VERSION ""

NS_ :

BS_:

BU_: VMCU TPM RCIOM FCIOM FAS ECUspare4 EBS EAS CCIOM BPMU APM

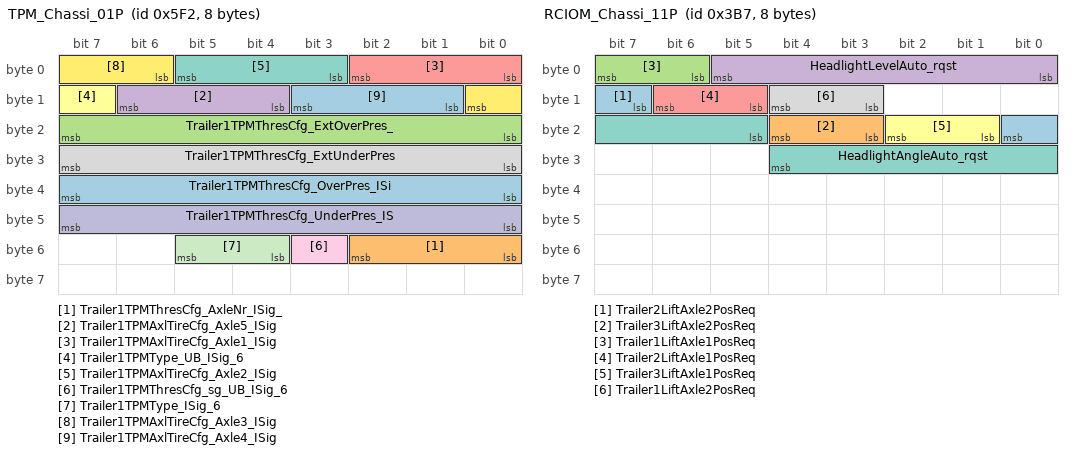
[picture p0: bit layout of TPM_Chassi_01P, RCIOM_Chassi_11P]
BO_ 1522 TPM_Chassi_01P: 8 TPM
 SG_ Trailer1TPMThresCfg_OverPres_ISi : 32|8@1+ (1,-125) [-125|130] "Percent"  VMCU
 SG_ Trailer1TPMThresCfg_AxleNr_ISig_ : 48|3@1+ (1,0) [0|0] ""  VMCU
 SG_ Trailer1TPMThresCfg_ExtOverPres_ : 16|8@1+ (1,-125) [-125|130] "Percent"  VMCU
 SG_ Trailer1TPMAxlTireCfg_Axle5_ISig : 12|3@1+ (1,0) [0|0] ""  VMCU
 SG_ Trailer1TPMAxlTireCfg_Axle1_ISig : 0|3@1+ (1,0) [0|0] ""  VMCU
 SG_ Trailer1TPMType_UB_ISig_6 : 15|1@1+ (1,0) [0|0] ""  VMCU
 SG_ Trailer1TPMAxlTireCfg_Axle2_ISig : 3|3@1+ (1,0) [0|0] ""  VMCU
 SG_ Trailer1TPMThresCfg_ExtUnderPres : 24|8@1+ (1,-125) [-125|130] "Percent"  VMCU
 SG_ Trailer1TPMThresCfg_sg_UB_ISig_6 : 51|1@1+ (1,0) [0|0] ""  VMCU
 SG_ Trailer1TPMThresCfg_UnderPres_IS : 40|8@1+ (1,-125) [-125|130] "Percent"  VMCU
 SG_ Trailer1TPMType_ISig_6 : 52|2@1+ (1,0) [0|0] ""  VMCU
 SG_ Trailer1TPMAxlTireCfg_Axle3_ISig : 6|3@1+ (1,0) [0|0] ""  VMCU
 SG_ Trailer1TPMAxlTireCfg_Axle4_ISig : 9|3@1+ (1,0) [0|0] ""  VMCU

BO_ 1349 RCIOM_Chassi_12P: 8 RCIOM
 SG_ RearAxleGroupLoad_ISig_6 : 0|16@1+ (2,0) [0|131070] "kg"  VMCU

BO_ 951 RCIOM_Chassi_11P: 8 RCIOM
 SG_ Trailer2LiftAxle2PosReq : 15|2@1+ (1,0) [0|0] ""  EBS
 SG_ Trailer3LiftAxle2PosReq : 19|2@1+ (1,0) [0|0] ""  EBS
 SG_ Trailer1LiftAxle1PosReq : 6|2@1+ (1,0) [0|0] ""  EBS
 SG_ HeadlightLevelAuto_rqst : 0|6@1+ (1,-16) [-16|47] ""  VMCU
 SG_ Trailer2LiftAxle1PosReq : 13|2@1+ (1,0) [0|0] ""  EBS
 SG_ Trailer3LiftAxle1PosReq : 17|2@1+ (1,0) [0|0] ""  EBS
 SG_ HeadlightAngleAuto_rqst : 21|8@1+ (0.025,-4) [-4|2.375] "deg"  VMCU
 SG_ Trailer1LiftAxle2PosReq : 11|2@1+ (1,0) [0|0] ""  EBS

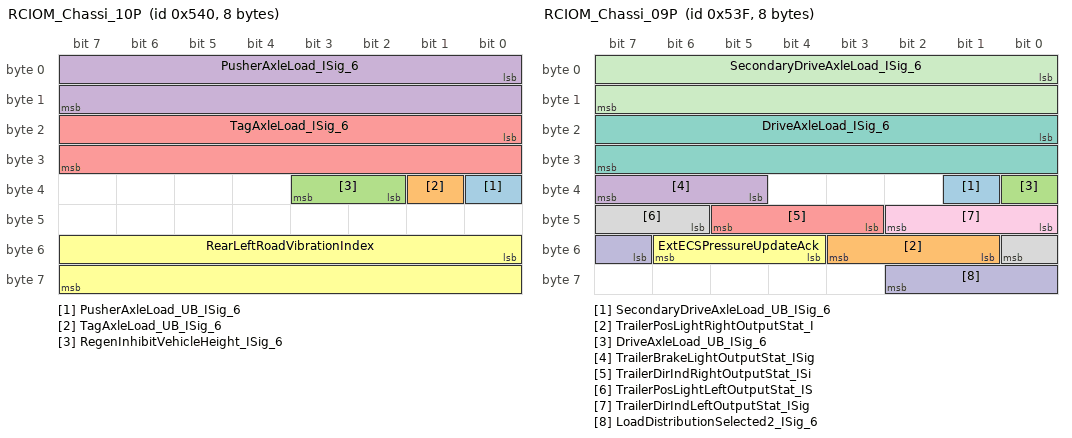
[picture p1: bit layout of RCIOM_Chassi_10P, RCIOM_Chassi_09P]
BO_ 1344 RCIOM_Chassi_10P: 8 RCIOM
 SG_ PusherAxleLoad_UB_ISig_6 : 32|1@1+ (1,0) [0|0] ""  FAS,EBS,EAS,APM,VMCU
 SG_ TagAxleLoad_UB_ISig_6 : 33|1@1+ (1,0) [0|0] ""  VMCU,EAS,APM,FAS,EBS
 SG_ RegenInhibitVehicleHeight_ISig_6 : 34|2@1+ (1,0) [0|0] ""  VMCU
 SG_ PusherAxleLoad_ISig_6 : 0|16@1+ (0.5,0) [0|32767.5] "kg"  EAS,VMCU,FAS,APM,EBS
 SG_ TagAxleLoad_ISig_6 : 16|16@1+ (0.5,0) [0|32767.5] "kg"  VMCU,EBS,APM,EAS,FAS
 SG_ RearLeftRoadVibrationIndex : 48|16@1+ (0.01,0) [0|655.35] ""  VMCU

BO_ 1343 RCIOM_Chassi_09P: 8 RCIOM
 SG_ SecondaryDriveAxleLoad_UB_ISig_6 : 33|1@1+ (1,0) [0|0] ""  FAS,APM,EBS,VMCU
 SG_ TrailerPosLightRightOutputStat_I : 49|3@1+ (1,0) [0|0] ""  VMCU
 SG_ DriveAxleLoad_UB_ISig_6 : 32|1@1+ (1,0) [0|0] ""  VMCU,EBS,FAS,APM
 SG_ TrailerBrakeLightOutputStat_ISig : 37|3@1+ (1,0) [0|0] ""  VMCU
 SG_ TrailerDirIndRightOutputStat_ISi : 43|3@1+ (1,0) [0|0] ""  VMCU
 SG_ ExtECSPressureUpdateAck : 52|3@1+ (1,0) [0|0] ""  VMCU
 SG_ DriveAxleLoad_ISig_6 : 16|16@1+ (0.5,0) [0|32767.5] "kg"  VMCU,FAS,EBS,APM
 SG_ TrailerPosLightLeftOutputStat_IS : 46|3@1+ (1,0) [0|0] ""  VMCU
 SG_ TrailerDirIndLeftOutputStat_ISig : 40|3@1+ (1,0) [0|0] ""  VMCU
 SG_ LoadDistributionSelected2_ISig_6 : 55|4@1+ (1,0) [0|0] ""  VMCU
 SG_ SecondaryDriveAxleLoad_ISig_6 : 0|16@1+ (0.5,0) [0|32767.5] "kg"  VMCU,FAS,APM,EBS

BO_ 825 RCIOM_Chassi_08P: 8 RCIOM
 SG_ RevLight_cmd : 6|2@1+ (1,0) [0|0] ""  CCIOM,VMCU
 SG_ LoadDistributionALDChangeACK_ISi : 32|3@1+ (1,0) [0|0] ""  VMCU
 SG_ LiftAxle2AutoLiftSelected_ISig_6 : 10|2@1+ (1,0) [0|0] ""  VMCU
 SG_ DriveLevelPosUserInteraction_ISi : 59|3@1+ (1,0) [0|0] ""  VMCU
 SG_ FirstAxleLowerPrioSelected_ISig_ : 27|3@1+ (1,0) [0|0] ""  VMCU
 SG_ FerryFunctionSwitchChangeACK_ISi : 0|2@1+ (1,0) [0|0] ""  VMCU
 SG_ TrailerDirInd_status : 56|3@1+ (1,0) [0|0] ""  VMCU
 SG_ RevLightLamp_stat_ISig_6 : 43|3@1+ (1,0) [0|0] ""  VMCU
 SG_ UnevenLoadWarning_ISig_6 : 38|2@1+ (1,0) [0|0] ""  VMCU
 SG_ LoadDistributionSelected_ISig_6 : 12|4@1+ (1,0) [0|0] ""  VMCU
 SG_ PositionLightRearLamp_stat_ISig_ : 40|3@1+ (1,0) [0|0] ""  VMCU
 SG_ LiftAxle1AutoLiftSelected_ISig_6 : 8|2@1+ (1,0) [0|0] ""  VMCU
 SG_ StartupProhibitStatus_ISig_6 : 53|2@1+ (1,0) [0|0] ""  VMCU
 SG_ BrakeLight_rqst_UB_ISig_6 : 55|1@1+ (1,0) [0|0] ""  VMCU
 SG_ LiftAxle1LowerACK_ISig_6 : 24|3@1+ (1,0) [0|0] ""  VMCU
 SG_ RampLevelRequestACK_ISig_6 : 4|2@1+ (1,0) [0|0] ""  VMCU
 SG_ BrakeLightLamp_stat_ISig_6 : 35|3@1+ (1,0) [0|0] ""  VMCU
 SG_ BrakeLightConvoy_rqst_UB_ISig_6 : 62|1@1+ (1,0) [0|0] ""  VMCU
 SG_ TrailerABSStatus_ISig_6 : 2|2@1+ (1,0) [0|0] ""  EBS,APM,VMCU
 SG_ FogLightRearLamp_stat_ISig_6 : 48|3@1+ (1,0) [0|0] ""  VMCU
 SG_ ECSLimpHomeNotification_ISig_6 : 19|3@1+ (1,0) [0|0] ""  VMCU
 SG_ BrakeLight_rqst_ISig_6 : 16|3@1+ (1,0) [0|0] ""  VMCU
 SG_ ECSValveActivationAllowed : 30|2@1+ (1,0) [0|0] ""  CCIOM
 SG_ BrakeLightConvoy_rqst_ISig_6 : 22|2@1+ (1,0) [0|0] ""  VMCU
 SG_ FrontParkBrakeOverrideInd_ISig_6 : 46|2@1+ (1,0) [0|0] ""  VMCU

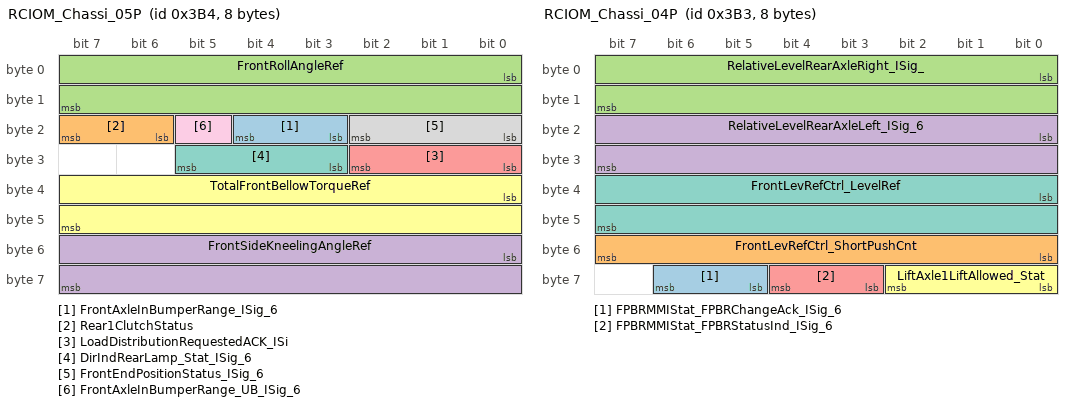
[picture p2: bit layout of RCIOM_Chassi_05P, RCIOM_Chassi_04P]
BO_ 948 RCIOM_Chassi_05P: 8 RCIOM
 SG_ FrontAxleInBumperRange_ISig_6 : 19|2@1+ (1,0) [0|0] ""  VMCU
 SG_ Rear1ClutchStatus : 22|2@1+ (1,0) [0|0] ""  VMCU
 SG_ FrontRollAngleRef : 0|16@1+ (0.001,-30) [-30|35.535] "deg"  CCIOM
 SG_ FrontSideKneelingAngleRef : 48|16@1+ (0.001,-30) [-30|35.535] "deg"  CCIOM
 SG_ LoadDistributionRequestedACK_ISi : 24|3@1+ (1,0) [0|0] ""  VMCU
 SG_ TotalFrontBellowTorqueRef : 32|16@1+ (1000,-10000000) [-10000000|55535000] "Nm"  CCIOM
 SG_ DirIndRearLamp_Stat_ISig_6 : 27|3@1+ (1,0) [0|0] ""  VMCU
 SG_ FrontEndPositionStatus_ISig_6 : 16|3@1+ (1,0) [0|0] ""  VMCU
 SG_ FrontAxleInBumperRange_UB_ISig_6 : 21|1@1+ (1,0) [0|0] ""  VMCU

BO_ 947 RCIOM_Chassi_04P: 8 RCIOM
 SG_ FPBRMMIStat_FPBRChangeAck_ISig_6 : 61|2@1+ (1,0) [0|0] ""  VMCU
 SG_ FrontLevRefCtrl_ShortPushCnt : 48|8@1+ (1,0) [0|255] "Count"  FAS,CCIOM
 SG_ RelativeLevelRearAxleRight_ISig_ : 0|16@1+ (0.1,-3200) [-3200|3353.5] "mm"  VMCU,EBS
 SG_ RelativeLevelRearAxleLeft_ISig_6 : 16|16@1+ (0.1,-3200) [-3200|3353.5] "mm"  EBS,VMCU
 SG_ FPBRMMIStat_FPBRStatusInd_ISig_6 : 59|2@1+ (1,0) [0|0] ""  VMCU
 SG_ LiftAxle1LiftAllowed_Stat : 56|3@1+ (1,0) [0|0] ""  VMCU
 SG_ FrontLevRefCtrl_LevelRef : 32|16@1+ (0.1,-3200) [-3200|3353.5] "mm"  CCIOM,FAS

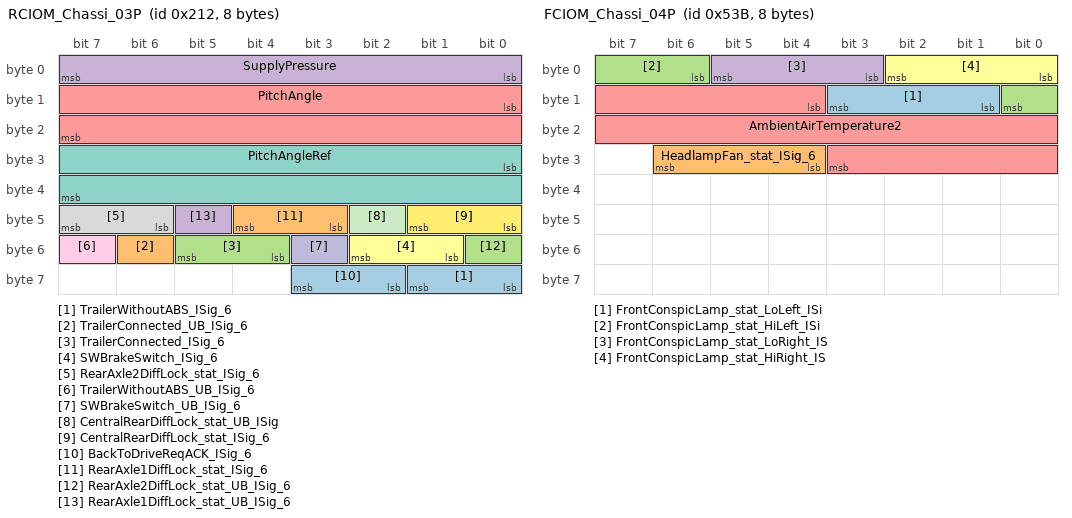
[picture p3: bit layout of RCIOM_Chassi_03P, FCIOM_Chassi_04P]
BO_ 530 RCIOM_Chassi_03P: 8 RCIOM
 SG_ TrailerWithoutABS_ISig_6 : 56|2@1+ (1,0) [0|0] ""  VMCU
 SG_ TrailerConnected_UB_ISig_6 : 54|1@1+ (1,0) [0|0] ""  APM,CCIOM,VMCU,TPM
 SG_ TrailerConnected_ISig_6 : 52|2@1+ (1,0) [0|0] ""  TPM,APM,CCIOM,VMCU
 SG_ SupplyPressure : 0|8@1+ (8,0) [0|2040] "kPa"  VMCU,CCIOM
 SG_ PitchAngle : 8|16@1+ (0.001,-30) [-30|35.535] "deg"  CCIOM,VMCU
 SG_ SWBrakeSwitch_ISig_6 : 49|2@1+ (1,0) [0|0] ""  APM,VMCU
 SG_ PitchAngleRef : 24|16@1+ (0.001,-30) [-30|35.535] "deg"  CCIOM
 SG_ RearAxle2DiffLock_stat_ISig_6 : 46|2@1+ (1,0) [0|0] ""  VMCU,EBS
 SG_ TrailerWithoutABS_UB_ISig_6 : 55|1@1+ (1,0) [0|0] ""  VMCU
 SG_ SWBrakeSwitch_UB_ISig_6 : 51|1@1+ (1,0) [0|0] ""  APM,VMCU
 SG_ CentralRearDiffLock_stat_UB_ISig : 42|1@1+ (1,0) [0|0] ""  VMCU,EBS
 SG_ CentralRearDiffLock_stat_ISig_6 : 40|2@1+ (1,0) [0|0] ""  VMCU,EBS
 SG_ BackToDriveReqACK_ISig_6 : 58|2@1+ (1,0) [0|0] ""  VMCU
 SG_ RearAxle1DiffLock_stat_ISig_6 : 43|2@1+ (1,0) [0|0] ""  VMCU,EBS
 SG_ RearAxle2DiffLock_stat_UB_ISig_6 : 48|1@1+ (1,0) [0|0] ""  EBS,VMCU
 SG_ RearAxle1DiffLock_stat_UB_ISig_6 : 45|1@1+ (1,0) [0|0] ""  VMCU,EBS

BO_ 528 RCIOM_Chassi_02P: 8 RCIOM
 SG_ RearEndPositionStatus_ISig_6 : 48|3@1+ (1,0) [0|0] ""  VMCU
 SG_ FrontFerryFunctionCmd : 59|3@1+ (1,0) [0|0] ""  CCIOM
 SG_ RideHeightStatus_ISig_6 : 20|4@1+ (1,0) [0|0] ""  VMCU
 SG_ KneelingInformation_ISig_6 : 24|4@1+ (1,0) [0|0] ""  VMCU
 SG_ RampHeightOutsideTargetRange_ISi : 51|3@1+ (1,0) [0|0] ""  VMCU
 SG_ LiftAxle1PositionStatus_ISig_6 : 8|3@1+ (1,0) [0|0] ""  CCIOM,VMCU,EBS,FAS,EAS
 SG_ HeightAdjustmentAllowed_ISig_6 : 54|2@1+ (1,0) [0|0] ""  VMCU
 SG_ FerryFunctionStatus_ISig_6 : 56|3@1+ (1,0) [0|0] ""  VMCU
 SG_ LoadDistributionFuncSelected_ISi : 28|4@1+ (1,0) [0|0] ""  VMCU
 SG_ LevelControlInformation_UB_ISig_ : 40|1@1+ (1,0) [0|0] ""  VMCU
 SG_ RollEndPositionStatus_ISig_6 : 3|3@1+ (1,0) [0|0] ""  VMCU
 SG_ HeightControlMode : 32|4@1+ (1,0) [0|0] ""  CCIOM
 SG_ RideHeightFunctionStatus_ISig_6 : 36|4@1+ (1,0) [0|0] ""  VMCU
 SG_ LevelControlInformation_ISig_6 : 16|4@1+ (1,0) [0|0] ""  VMCU
 SG_ KneelingStatusHMI_ISig_6 : 41|2@1+ (1,0) [0|0] ""  VMCU
 SG_ DirInd_Rear_Status : 0|3@1+ (1,0) [0|0] ""  VMCU
 SG_ VehicleDynamicSuspProhibitStat : 62|2@1+ (1,0) [0|0] ""  CCIOM
 SG_ ChangeKneelACK_ISig_6 : 45|2@1+ (1,0) [0|0] ""  VMCU
 SG_ ECSShutdownCmd : 43|2@1+ (1,0) [0|0] ""  CCIOM
 SG_ LiftAxle2PositionStatus_ISig_6 : 11|3@1+ (1,0) [0|0] ""  VMCU,EBS,FAS

BO_ 517 RCIOM_Chassi_01P: 8 RCIOM
 SG_ BrakePressureSensorDemand_ISig_6 : 8|8@1+ (1,0) [0|255] "Percent"  VMCU,APM
 SG_ RampLevelStatus_ISig_6 : 46|4@1+ (1,0) [0|0] ""  VMCU
 SG_ LiftAxle2LowerACK_ISig_6 : 37|3@1+ (1,0) [0|0] ""  VMCU
 SG_ LiftAxle2UpRequestACK_ISig_6 : 34|3@1+ (1,0) [0|0] ""  VMCU
 SG_ FrontLimpHomeCmd : 50|3@1+ (1,0) [0|0] ""  CCIOM
 SG_ LiftAxle1LiftFuncSelected_ISig_6 : 53|3@1+ (1,0) [0|0] ""  VMCU
 SG_ RearAxleInBumperRange_ISig_6 : 30|2@1+ (1,0) [0|0] ""  VMCU
 SG_ LiftAxle1UpRequestACK_ISig_6 : 40|3@1+ (1,0) [0|0] ""  VMCU
 SG_ FogLamp_Rear_Status : 20|2@1+ (1,0) [0|0] ""  VMCU
 SG_ StopLevelChangeAck_ISig_6 : 16|2@1+ (1,0) [0|0] ""  VMCU
 SG_ RampLevelStorageAck_ISig_6 : 24|2@1+ (1,0) [0|0] ""  VMCU
 SG_ RideHeightOutsideTargetRange_ISi : 43|3@1+ (1,0) [0|0] ""  VMCU
 SG_ LiftingControlModeFrontAxle_ISig : 2|2@1+ (1,0) [0|0] ""  APM,VMCU
 SG_ LoadDistributionChangeACK_ISig_6 : 56|3@1+ (1,0) [0|0] ""  VMCU
 SG_ RideHeightStorageAck_ISig_6 : 6|2@1+ (1,0) [0|0] ""  VMCU
 SG_ RearAxleInBumperRange_UB_ISig_6 : 0|1@1+ (1,0) [0|0] ""  VMCU
 SG_ ECSStandbyAllowed_ISig_6 : 32|2@1+ (1,0) [0|0] ""  VMCU
 SG_ LiftAxle2LiftFuncSelected_ISig_6 : 59|3@1+ (1,0) [0|0] ""  VMCU
 SG_ FrontProhibitControlRequest : 4|2@1+ (1,0) [0|0] ""  CCIOM
 SG_ LiftingControlModeRearAxle_ISig_ : 18|2@1+ (1,0) [0|0] ""  VMCU,APM
 SG_ ProhibitControlStatus_ISig_6 : 62|2@1+ (1,0) [0|0] ""  VMCU
 SG_ DisableMechFaultDctnFr_rqst : 26|2@1+ (1,0) [0|0] ""  CCIOM
 SG_ FrontParkBrakeOverrideCommand : 22|2@1+ (1,0) [0|0] ""  EBS
 SG_ BrakePressureSensorDemand_UB_ISi : 1|1@1+ (1,0) [0|0] ""  VMCU,APM

BO_ 2671833714 PhysDiagRespMsg_F2_72_Chas: 8 FCIOM
 SG_ PhysDiagRespSig_F2_72_ISig_6 : 0|64@1+ (1,0) [0|0] ""  VMCU

BO_ 2671833713 PhysDiagRespMsg_F2_71_Chas: 8 FCIOM
 SG_ PhysDiagRespSig_F2_71_ISig_6 : 0|64@1+ (1,0) [0|0] ""  VMCU

BO_ 2671833649 PhysDiagRespMsg_F2_31_Chassi: 8 EAS
 SG_ PhysDiagRespSig_F2_31_ISig_6 : 0|64@1+ (1,0) [0|0] ""  VMCU

BO_ 2671833648 PhysDiagRespMsg_F2_30_Chassi: 8 FAS
 SG_ PhysDiagRespSig_F2_30_ISig_6 : 0|64@1+ (1,0) [0|0] ""  VMCU

BO_ 2671833637 PhysDiagRespMsg_F2_25_Chassi: 8 TPM
 SG_ PhysDiagRespSig_F2_25_ISig_6 : 0|64@1+ (1,0) [0|0] ""  VMCU

BO_ 2671833635 PhysDiagRespMsg_F2_23_Chassi: 8 APM
 SG_ PhysDiagRespSig_F2_23_ISig_6 : 0|64@1+ (1,0) [0|0] ""  VMCU

BO_ 2671833634 PhysDiagRespMsg_F2_22_Chassi: 8 RCIOM
 SG_ PhysDiagRespSig_F2_22_ISig_6 : 0|64@1+ (1,0) [0|0] ""  VMCU

BO_ 2671833633 PhysDiagRespMsg_F2_21_Chassi: 8 FCIOM
 SG_ PhysDiagRespSig_F2_21_ISig_6 : 0|64@1+ (1,0) [0|0] ""  VMCU

BO_ 2671833632 PhysDiagRespMsg_F2_20_Chassi: 8 CCIOM
 SG_ PhysDiagRespSig_F2_20_ISig_6 : 0|64@1+ (1,0) [0|0] ""  VMCU

BO_ 2671833626 PhysDiagRespMsg_F2_1A_Chassi: 8 BPMU
 SG_ PhysDiagRespSig_F2_1A_ISig_6 : 0|64@1+ (1,0) [0|0] ""  VMCU

BO_ 2671801074 PhysDiagReqMsg_72_F2_Chas: 8 VMCU
 SG_ PhysDiagReqSig_72_F2_ISig_6 : 0|64@1+ (1,0) [0|0] ""  FCIOM

BO_ 2671800818 PhysDiagReqMsg_71_F2_Chas: 8 VMCU
 SG_ PhysDiagReqSig_71_F2_ISig_6 : 0|64@1+ (1,0) [0|0] ""  FCIOM

BO_ 2671784434 PhysDiagReqMsg_31_F2_Chassi: 8 VMCU
 SG_ PhysDiagReqSig_31_F2_ISig_6 : 0|64@1+ (1,0) [0|0] ""  EAS

BO_ 2671784178 PhysDiagReqMsg_30_F2_Chassi: 8 VMCU
 SG_ PhysDiagReqSig_30_F2_ISig_6 : 0|64@1+ (1,0) [0|0] ""  FAS

BO_ 2671781362 PhysDiagReqMsg_25_F2_Chassi: 8 VMCU
 SG_ PhysDiagReqSig_25_F2_ISig_6 : 0|64@1+ (1,0) [0|0] ""  TPM

BO_ 2671780850 PhysDiagReqMsg_23_F2_Chassi: 8 VMCU
 SG_ PhysDiagReqSig_23_F2_ISig_6 : 0|64@1+ (1,0) [0|0] ""  APM

BO_ 2671780594 PhysDiagReqMsg_22_F2_Chassi: 8 VMCU
 SG_ PhysDiagReqSig_22_F2_ISig_6 : 0|64@1+ (1,0) [0|0] ""  RCIOM

BO_ 2671780338 PhysDiagReqMsg_21_F2_Chassi: 8 VMCU
 SG_ PhysDiagReqSig_21_F2_ISig_6 : 0|64@1+ (1,0) [0|0] ""  FCIOM

BO_ 2671780082 PhysDiagReqMsg_20_F2_Chassi: 8 VMCU
 SG_ PhysDiagReqSig_20_F2_ISig_6 : 0|64@1+ (1,0) [0|0] ""  CCIOM

BO_ 2671778546 PhysDiagReqMsg_1A_F2_Chassi: 8 VMCU
 SG_ PhysDiagReqSig_1A_F2_ISig_6 : 0|64@1+ (1,0) [0|0] ""  BPMU

BO_ 2633990180 NmAsr_VMCU_Chassi: 1 VMCU

BO_ 2633990181 NmAsr_TPM_Chassi: 1 TPM

BO_ 2633990178 NmAsr_RCIOM_Chassi: 1 RCIOM

BO_ 2633990177 NmAsr_FCIOM_Chassi: 1 FCIOM

BO_ 2633990192 NmAsr_FAS_Chassi: 1 FAS

BO_ 2633990184 NmAsr_EBS_Chassi: 1 EBS

BO_ 2633990193 NmAsr_EAS_Chassi: 1 EAS

BO_ 2633990176 NmAsr_CCIOM_Chassi: 1 CCIOM

BO_ 2633990170 NmAsr_BPMU_Chassi: 1 BPMU

BO_ 2633990179 NmAsr_APM_Chassi: 1 APM

BO_ 2671902708 IntTesterTGW2FuncDiagMsg_Chas: 8 VMCU
 SG_ FuncDiagDataIntTesterTGW2_ISig_6 : 0|64@1+ (1,0) [0|0] ""  EAS,RCIOM,CCIOM,FCIOM,APM,TPM,BPMU,FAS

BO_ 1339 FCIOM_Chassi_04P: 8 FCIOM
 SG_ FrontConspicLamp_stat_LoLeft_ISi : 9|3@1+ (1,0) [0|0] ""  VMCU
 SG_ HeadlampFan_stat_ISig_6 : 28|3@1+ (1,0) [0|0] ""  VMCU
 SG_ FrontConspicLamp_stat_HiLeft_ISi : 6|3@1+ (1,0) [0|0] ""  VMCU
 SG_ FrontConspicLamp_stat_LoRight_IS : 3|3@1+ (1,0) [0|0] ""  VMCU
 SG_ AmbientAirTemperature2 : 12|16@1+ (0.03125,-273) [-273|1774.96875] "DegreeC"  VMCU
 SG_ FrontConspicLamp_stat_HiRight_IS : 0|3@1+ (1,0) [0|0] ""  VMCU

BO_ 1243 FCIOM_Chassi_03P: 8 FCIOM
 SG_ MainBeamLEDStatusLeft_ISig_6 : 0|3@1+ (1,0) [0|0] ""  VMCU
 SG_ MainBeamLEDStatusRight_ISig_6 : 3|3@1+ (1,0) [0|0] ""  VMCU

CM_ SG_ 1344 PusherAxleLoad_ISig_6 "65024 - 65279 Error ; 65280 - 65535 Not available";
CM_ SG_ 1344 TagAxleLoad_ISig_6 "65024 - 65279 Error ; 65280 - 65535 Not available";
CM_ SG_ 1343 DriveAxleLoad_ISig_6 "65024 - 65279 Error ; 65280 - 65535 Not available";
CM_ SG_ 1343 SecondaryDriveAxleLoad_ISig_6 "65024 - 65279 Error ; 65280 - 65535 Not available";
CM_ SG_ 948 FrontRollAngleRef "65024 - 65279 Error ; 65280 - 65535 Not available";
CM_ SG_ 948 TotalFrontBellowTorqueRef "65024-65279 Error ; 65280-65535 Not Available";
CM_ SG_ 947 RelativeLevelRearAxleRight_ISig_ "65024 - 65279 Error ; 65280 - 65535 Not available";
CM_ SG_ 947 RelativeLevelRearAxleLeft_ISig_6 "65024 - 65279 Error ; 65280 - 65535 Not available";
CM_ SG_ 530 SupplyPressure "254 Error ; 255 Not available";
CM_ SG_ 530 PitchAngle "65024 - 65279 Error ; 65280 - 65535 Not available";
CM_ SG_ 530 PitchAngleRef "65024 - 65279 Error ; 65280 - 65535 Not available";
CM_ SG_ 517 BrakePressureSensorDemand_ISig_6 "254 Error ; 255 Not available";
BA_DEF_ BO_  "GenMsgStartDelayTime" INT 0 0;
BA_DEF_ BO_  "GenMsgDelayTime" INT 0 0;
BA_DEF_ BO_  "GenMsgCycleTime" INT 0 0;
BA_DEF_ BO_  "GenMsgSendType" ENUM  "Cyclic","NotUsed","NotUsed","NotUsed","NotUsed","NotUsed","NotUsed","IfActive","NoMsgSendType","NotUsed";
BA_DEF_ SG_  "GenSigStartValue" INT 0 0;
BA_DEF_ SG_  "GenSigInactiveValue" INT 0 0;
BA_DEF_ SG_  "GenSigCycleTimeActive" INT 0 0;
BA_DEF_ SG_  "GenSigCycleTime" INT 0 0;
BA_DEF_ SG_  "GenSigSendType" ENUM  "Cyclic","OnWrite","OnWriteWithRepetition","OnChange","OnChangeWithRepetition","IfActive","IfActiveWithRepetition","NoSigSendType","NotUsed","NotUsed","NotUsed","NotUsed","NotUsed";
BA_DEF_ BO_  "VFrameFormat" ENUM  "StandardCAN","ExtendedCAN","reserved","J1939PG";
BA_DEF_ SG_  "SigType" ENUM  "Default","Range","RangeSigned","ASCII","Discrete","Control","ReferencePGN","DTC","StringDelimiter","StringLength","StringLengthControl";
BA_DEF_ SG_  "SeToolVersion_SIGNAL" STRING ;
BA_DEF_ SG_  "SeToolUniqueID_SIGNAL" STRING ;
BA_DEF_ SG_  "SeToolName_SIGNAL" STRING ;
BA_DEF_ SG_  "SeToolItemID_SIGNAL" STRING ;
BA_DEF_ SG_  "SeToolAncestorID_SIGNAL" STRING ;
BA_DEF_ SG_  "Platform_VMCU1_Sig" ENUM  "No","Yes";
BA_DEF_ BO_  "NmAsrMessage" ENUM  "No","Yes";
BA_DEF_ SG_  "NeedsUpdateBit" ENUM  "No","Yes";
BA_DEF_ SG_  "MmAnSignal" ENUM  "No","Yes";
BA_DEF_ SG_  "GenSigMaxLatency" INT 0 65535;
BA_DEF_ SG_  "GenSigILSupport" ENUM  "Yes","No";
BA_DEF_ BO_  "GenMsgRequestable" INT 0 1;
BA_DEF_ BO_  "GenMsgILSupport" ENUM  "No","Yes";
BA_DEF_ BO_  "DiagUUDTResponse" ENUM  "No","Yes";
BA_DEF_ BO_  "DiagState" ENUM  "No","Yes";
BA_DEF_ BO_  "DiagResponse" ENUM  "No","Yes";
BA_DEF_ BO_  "DiagRequest" ENUM  "No","Yes";
BA_DEF_ BO_  "DiagConnection" HEX 0 65535;
BA_DEF_ BO_  "CanTpFcFrameId" HEX 0 2147483647;
BA_DEF_ BO_  "CanTpBs" INT 0 255;
BA_DEF_ SG_  "SystemSignalLongSymbol" STRING ;
BA_DEF_REL_ BU_SG_REL_  "GenSigTimeoutTime" INT 0 65535;
BA_DEF_REL_ BU_SG_REL_  "GenSigFirstTimeoutTime" INT 0 65535;
BA_DEF_DEF_  "GenMsgStartDelayTime" 0;
BA_DEF_DEF_  "GenMsgDelayTime" 0;
BA_DEF_DEF_  "GenMsgCycleTime" 0;
BA_DEF_DEF_  "GenMsgSendType" "Cyclic";
BA_DEF_DEF_  "GenSigStartValue" 0;
BA_DEF_DEF_  "GenSigInactiveValue" 0;
BA_DEF_DEF_  "GenSigCycleTimeActive" 0;
BA_DEF_DEF_  "GenSigCycleTime" 0;
BA_DEF_DEF_  "GenSigSendType" "Cyclic";
BA_DEF_DEF_  "VFrameFormat" "ExtendedCAN";
BA_DEF_DEF_  "SigType" "Default";
BA_DEF_DEF_  "SeToolVersion_SIGNAL" "";
BA_DEF_DEF_  "SeToolUniqueID_SIGNAL" "";
BA_DEF_DEF_  "SeToolName_SIGNAL" "";
BA_DEF_DEF_  "SeToolItemID_SIGNAL" "";
BA_DEF_DEF_  "SeToolAncestorID_SIGNAL" "";
BA_DEF_DEF_  "Platform_VMCU1_Sig" "No";
BA_DEF_DEF_  "NmAsrMessage" "No";
BA_DEF_DEF_  "NeedsUpdateBit" "No";
BA_DEF_DEF_  "MmAnSignal" "No";
BA_DEF_DEF_  "GenSigMaxLatency" 0;
BA_DEF_DEF_  "GenSigILSupport" "Yes";
BA_DEF_DEF_  "GenMsgRequestable" 1;
BA_DEF_DEF_  "GenMsgILSupport" "Yes";
BA_DEF_DEF_  "DiagUUDTResponse" "No";
BA_DEF_DEF_  "DiagState" "No";
BA_DEF_DEF_  "DiagResponse" "No";
BA_DEF_DEF_  "DiagRequest" "No";
BA_DEF_DEF_  "DiagConnection" 0;
BA_DEF_DEF_  "CanTpFcFrameId" 2147483647;
BA_DEF_DEF_  "CanTpBs" 255;
BA_DEF_DEF_REL_ "GenSigTimeoutTime" 0;
BA_DEF_DEF_REL_ "GenSigFirstTimeoutTime" 0;
BA_DEF_DEF_  "SystemSignalLongSymbol" "";
BA_ "VFrameFormat" BO_ 1522 0;
BA_ "GenMsgCycleTime" BO_ 1522 1000;
BA_ "GenMsgStartDelayTime" BO_ 1522 230;
BA_ "VFrameFormat" BO_ 1349 0;
BA_ "GenMsgCycleTime" BO_ 1349 250;
BA_ "GenMsgStartDelayTime" BO_ 1349 75;
BA_ "VFrameFormat" BO_ 951 0;
BA_ "GenMsgCycleTime" BO_ 951 50;
BA_ "GenMsgStartDelayTime" BO_ 951 5;
BA_ "VFrameFormat" BO_ 1344 0;
BA_ "GenMsgCycleTime" BO_ 1344 250;
BA_ "GenMsgStartDelayTime" BO_ 1344 150;
BA_ "VFrameFormat" BO_ 1343 0;
BA_ "GenMsgCycleTime" BO_ 1343 250;
BA_ "GenMsgStartDelayTime" BO_ 1343 50;
BA_ "VFrameFormat" BO_ 825 0;
BA_ "GenMsgCycleTime" BO_ 825 30;
BA_ "VFrameFormat" BO_ 948 0;
BA_ "GenMsgCycleTime" BO_ 948 50;
BA_ "GenMsgStartDelayTime" BO_ 948 30;
BA_ "VFrameFormat" BO_ 947 0;
BA_ "GenMsgCycleTime" BO_ 947 50;
BA_ "GenMsgStartDelayTime" BO_ 947 10;
BA_ "VFrameFormat" BO_ 530 0;
BA_ "GenMsgCycleTime" BO_ 530 20;
BA_ "GenMsgStartDelayTime" BO_ 530 10;
BA_ "VFrameFormat" BO_ 528 0;
BA_ "GenMsgCycleTime" BO_ 528 20;
BA_ "GenMsgStartDelayTime" BO_ 528 5;
BA_ "VFrameFormat" BO_ 517 0;
BA_ "GenMsgCycleTime" BO_ 517 20;
BA_ "DiagConnection" BO_ 2671833714 62066;
BA_ "DiagResponse" BO_ 2671833714 1;
BA_ "GenMsgILSupport" BO_ 2671833714 0;
BA_ "GenMsgSendType" BO_ 2671833714 8;
BA_ "DiagConnection" BO_ 2671833713 62065;
BA_ "DiagResponse" BO_ 2671833713 1;
BA_ "GenMsgILSupport" BO_ 2671833713 0;
BA_ "GenMsgSendType" BO_ 2671833713 8;
BA_ "DiagConnection" BO_ 2671833649 62001;
BA_ "DiagResponse" BO_ 2671833649 1;
BA_ "GenMsgILSupport" BO_ 2671833649 0;
BA_ "GenMsgSendType" BO_ 2671833649 8;
BA_ "DiagConnection" BO_ 2671833648 62000;
BA_ "DiagResponse" BO_ 2671833648 1;
BA_ "GenMsgILSupport" BO_ 2671833648 0;
BA_ "GenMsgSendType" BO_ 2671833648 8;
BA_ "DiagConnection" BO_ 2671833637 61989;
BA_ "DiagResponse" BO_ 2671833637 1;
BA_ "GenMsgILSupport" BO_ 2671833637 0;
BA_ "GenMsgSendType" BO_ 2671833637 8;
BA_ "DiagConnection" BO_ 2671833635 61987;
BA_ "DiagResponse" BO_ 2671833635 1;
BA_ "GenMsgILSupport" BO_ 2671833635 0;
BA_ "GenMsgSendType" BO_ 2671833635 8;
BA_ "DiagConnection" BO_ 2671833634 61986;
BA_ "DiagResponse" BO_ 2671833634 1;
BA_ "GenMsgILSupport" BO_ 2671833634 0;
BA_ "GenMsgSendType" BO_ 2671833634 8;
BA_ "DiagConnection" BO_ 2671833633 61985;
BA_ "DiagResponse" BO_ 2671833633 1;
BA_ "GenMsgILSupport" BO_ 2671833633 0;
BA_ "GenMsgSendType" BO_ 2671833633 8;
BA_ "DiagConnection" BO_ 2671833632 61984;
BA_ "DiagResponse" BO_ 2671833632 1;
BA_ "GenMsgILSupport" BO_ 2671833632 0;
BA_ "GenMsgSendType" BO_ 2671833632 8;
BA_ "DiagConnection" BO_ 2671833626 61978;
BA_ "DiagResponse" BO_ 2671833626 1;
BA_ "GenMsgILSupport" BO_ 2671833626 0;
BA_ "GenMsgSendType" BO_ 2671833626 8;
BA_ "DiagConnection" BO_ 2671801074 62066;
BA_ "DiagRequest" BO_ 2671801074 1;
BA_ "GenMsgILSupport" BO_ 2671801074 0;
BA_ "GenMsgSendType" BO_ 2671801074 8;
BA_ "DiagConnection" BO_ 2671800818 62065;
BA_ "DiagRequest" BO_ 2671800818 1;
BA_ "GenMsgILSupport" BO_ 2671800818 0;
BA_ "GenMsgSendType" BO_ 2671800818 8;
BA_ "DiagConnection" BO_ 2671784434 62001;
BA_ "DiagRequest" BO_ 2671784434 1;
BA_ "GenMsgILSupport" BO_ 2671784434 0;
BA_ "GenMsgSendType" BO_ 2671784434 8;
BA_ "DiagConnection" BO_ 2671784178 62000;
BA_ "DiagRequest" BO_ 2671784178 1;
BA_ "GenMsgILSupport" BO_ 2671784178 0;
BA_ "GenMsgSendType" BO_ 2671784178 8;
BA_ "DiagConnection" BO_ 2671781362 61989;
BA_ "DiagRequest" BO_ 2671781362 1;
BA_ "GenMsgILSupport" BO_ 2671781362 0;
BA_ "GenMsgSendType" BO_ 2671781362 8;
BA_ "DiagConnection" BO_ 2671780850 61987;
BA_ "DiagRequest" BO_ 2671780850 1;
BA_ "GenMsgILSupport" BO_ 2671780850 0;
BA_ "GenMsgSendType" BO_ 2671780850 8;
BA_ "DiagConnection" BO_ 2671780594 61986;
BA_ "DiagRequest" BO_ 2671780594 1;
BA_ "GenMsgILSupport" BO_ 2671780594 0;
BA_ "GenMsgSendType" BO_ 2671780594 8;
BA_ "DiagConnection" BO_ 2671780338 61985;
BA_ "DiagRequest" BO_ 2671780338 1;
BA_ "GenMsgILSupport" BO_ 2671780338 0;
BA_ "GenMsgSendType" BO_ 2671780338 8;
BA_ "DiagConnection" BO_ 2671780082 61984;
BA_ "DiagRequest" BO_ 2671780082 1;
BA_ "GenMsgILSupport" BO_ 2671780082 0;
BA_ "GenMsgSendType" BO_ 2671780082 8;
BA_ "DiagConnection" BO_ 2671778546 61978;
BA_ "DiagRequest" BO_ 2671778546 1;
BA_ "GenMsgILSupport" BO_ 2671778546 0;
BA_ "GenMsgSendType" BO_ 2671778546 8;
BA_ "GenMsgILSupport" BO_ 2633990180 0;
BA_ "NmAsrMessage" BO_ 2633990180 1;
BA_ "GenMsgSendType" BO_ 2633990180 8;
BA_ "GenMsgILSupport" BO_ 2633990181 0;
BA_ "NmAsrMessage" BO_ 2633990181 1;
BA_ "GenMsgSendType" BO_ 2633990181 8;
BA_ "GenMsgILSupport" BO_ 2633990178 0;
BA_ "NmAsrMessage" BO_ 2633990178 1;
BA_ "GenMsgSendType" BO_ 2633990178 8;
BA_ "GenMsgILSupport" BO_ 2633990177 0;
BA_ "NmAsrMessage" BO_ 2633990177 1;
BA_ "GenMsgSendType" BO_ 2633990177 8;
BA_ "GenMsgILSupport" BO_ 2633990192 0;
BA_ "NmAsrMessage" BO_ 2633990192 1;
BA_ "GenMsgSendType" BO_ 2633990192 8;
BA_ "GenMsgILSupport" BO_ 2633990184 0;
BA_ "NmAsrMessage" BO_ 2633990184 1;
BA_ "GenMsgSendType" BO_ 2633990184 8;
BA_ "GenMsgILSupport" BO_ 2633990193 0;
BA_ "NmAsrMessage" BO_ 2633990193 1;
BA_ "GenMsgSendType" BO_ 2633990193 8;
BA_ "GenMsgILSupport" BO_ 2633990176 0;
BA_ "NmAsrMessage" BO_ 2633990176 1;
BA_ "GenMsgSendType" BO_ 2633990176 8;
BA_ "GenMsgILSupport" BO_ 2633990170 0;
BA_ "NmAsrMessage" BO_ 2633990170 1;
BA_ "GenMsgSendType" BO_ 2633990170 8;
BA_ "GenMsgILSupport" BO_ 2633990179 0;
BA_ "NmAsrMessage" BO_ 2633990179 1;
BA_ "GenMsgSendType" BO_ 2633990179 8;
BA_ "DiagConnection" BO_ 2671902708 62470;
BA_ "DiagState" BO_ 2671902708 1;
BA_ "GenMsgILSupport" BO_ 2671902708 0;
BA_ "GenMsgSendType" BO_ 2671902708 8;
BA_ "VFrameFormat" BO_ 1339 0;
BA_ "GenMsgCycleTime" BO_ 1339 250;
BA_ "GenMsgStartDelayTime" BO_ 1339 50;
BA_ "VFrameFormat" BO_ 1243 0;
BA_ "GenMsgCycleTime" BO_ 1243 100;
BA_ "GenMsgStartDelayTime" BO_ 1243 25;
BA_ "GenSigCycleTime" SG_ 1522 Trailer1TPMThresCfg_OverPres_ISi 100;
BA_ "GenSigCycleTimeActive" SG_ 1522 Trailer1TPMThresCfg_OverPres_ISi 100;
BA_ "GenSigStartValue" SG_ 1522 Trailer1TPMThresCfg_OverPres_ISi 255;
BA_ "NeedsUpdateBit" SG_ 1522 Trailer1TPMThresCfg_OverPres_ISi 1;
BA_ "Platform_VMCU1_Sig" SG_ 1522 Trailer1TPMThresCfg_OverPres_ISi 1;
BA_ "SystemSignalLongSymbol" SG_ 1522 Trailer1TPMThresCfg_OverPres_ISi "Trailer1TPMThresCfg_OverPres_ISig_6";
BA_ "GenSigCycleTime" SG_ 1522 Trailer1TPMThresCfg_AxleNr_ISig_ 100;
BA_ "GenSigCycleTimeActive" SG_ 1522 Trailer1TPMThresCfg_AxleNr_ISig_ 100;
BA_ "GenSigStartValue" SG_ 1522 Trailer1TPMThresCfg_AxleNr_ISig_ 7;
BA_ "NeedsUpdateBit" SG_ 1522 Trailer1TPMThresCfg_AxleNr_ISig_ 1;
BA_ "Platform_VMCU1_Sig" SG_ 1522 Trailer1TPMThresCfg_AxleNr_ISig_ 1;
BA_ "SystemSignalLongSymbol" SG_ 1522 Trailer1TPMThresCfg_AxleNr_ISig_ "Trailer1TPMThresCfg_AxleNr_ISig_6";
BA_ "GenSigCycleTime" SG_ 1522 Trailer1TPMThresCfg_ExtOverPres_ 100;
BA_ "GenSigCycleTimeActive" SG_ 1522 Trailer1TPMThresCfg_ExtOverPres_ 100;
BA_ "GenSigStartValue" SG_ 1522 Trailer1TPMThresCfg_ExtOverPres_ 255;
BA_ "NeedsUpdateBit" SG_ 1522 Trailer1TPMThresCfg_ExtOverPres_ 1;
BA_ "Platform_VMCU1_Sig" SG_ 1522 Trailer1TPMThresCfg_ExtOverPres_ 1;
BA_ "SystemSignalLongSymbol" SG_ 1522 Trailer1TPMThresCfg_ExtOverPres_ "Trailer1TPMThresCfg_ExtOverPres_ISig_6";
BA_ "GenSigCycleTime" SG_ 1522 Trailer1TPMAxlTireCfg_Axle5_ISig 100;
BA_ "GenSigCycleTimeActive" SG_ 1522 Trailer1TPMAxlTireCfg_Axle5_ISig 100;
BA_ "GenSigStartValue" SG_ 1522 Trailer1TPMAxlTireCfg_Axle5_ISig 7;
BA_ "Platform_VMCU1_Sig" SG_ 1522 Trailer1TPMAxlTireCfg_Axle5_ISig 1;
BA_ "SystemSignalLongSymbol" SG_ 1522 Trailer1TPMAxlTireCfg_Axle5_ISig "Trailer1TPMAxlTireCfg_Axle5_ISig_6";
BA_ "GenSigCycleTime" SG_ 1522 Trailer1TPMAxlTireCfg_Axle1_ISig 100;
BA_ "GenSigCycleTimeActive" SG_ 1522 Trailer1TPMAxlTireCfg_Axle1_ISig 100;
BA_ "GenSigStartValue" SG_ 1522 Trailer1TPMAxlTireCfg_Axle1_ISig 7;
BA_ "Platform_VMCU1_Sig" SG_ 1522 Trailer1TPMAxlTireCfg_Axle1_ISig 1;
BA_ "SystemSignalLongSymbol" SG_ 1522 Trailer1TPMAxlTireCfg_Axle1_ISig "Trailer1TPMAxlTireCfg_Axle1_ISig_6";
BA_ "GenSigSendType" SG_ 1522 Trailer1TPMType_UB_ISig_6 7;
BA_ "Platform_VMCU1_Sig" SG_ 1522 Trailer1TPMType_UB_ISig_6 1;
BA_ "GenSigCycleTime" SG_ 1522 Trailer1TPMAxlTireCfg_Axle2_ISig 100;
BA_ "GenSigCycleTimeActive" SG_ 1522 Trailer1TPMAxlTireCfg_Axle2_ISig 100;
BA_ "GenSigStartValue" SG_ 1522 Trailer1TPMAxlTireCfg_Axle2_ISig 7;
BA_ "Platform_VMCU1_Sig" SG_ 1522 Trailer1TPMAxlTireCfg_Axle2_ISig 1;
BA_ "SystemSignalLongSymbol" SG_ 1522 Trailer1TPMAxlTireCfg_Axle2_ISig "Trailer1TPMAxlTireCfg_Axle2_ISig_6";
BA_ "GenSigCycleTime" SG_ 1522 Trailer1TPMThresCfg_ExtUnderPres 100;
BA_ "GenSigCycleTimeActive" SG_ 1522 Trailer1TPMThresCfg_ExtUnderPres 100;
BA_ "GenSigStartValue" SG_ 1522 Trailer1TPMThresCfg_ExtUnderPres 255;
BA_ "NeedsUpdateBit" SG_ 1522 Trailer1TPMThresCfg_ExtUnderPres 1;
BA_ "Platform_VMCU1_Sig" SG_ 1522 Trailer1TPMThresCfg_ExtUnderPres 1;
BA_ "SystemSignalLongSymbol" SG_ 1522 Trailer1TPMThresCfg_ExtUnderPres "Trailer1TPMThresCfg_ExtUnderPres_ISig_6";
BA_ "GenSigSendType" SG_ 1522 Trailer1TPMThresCfg_sg_UB_ISig_6 7;
BA_ "GenSigCycleTime" SG_ 1522 Trailer1TPMThresCfg_sg_UB_ISig_6 100;
BA_ "GenSigCycleTimeActive" SG_ 1522 Trailer1TPMThresCfg_sg_UB_ISig_6 100;
BA_ "Platform_VMCU1_Sig" SG_ 1522 Trailer1TPMThresCfg_sg_UB_ISig_6 1;
BA_ "GenSigCycleTime" SG_ 1522 Trailer1TPMThresCfg_UnderPres_IS 100;
BA_ "GenSigCycleTimeActive" SG_ 1522 Trailer1TPMThresCfg_UnderPres_IS 100;
BA_ "GenSigStartValue" SG_ 1522 Trailer1TPMThresCfg_UnderPres_IS 255;
BA_ "NeedsUpdateBit" SG_ 1522 Trailer1TPMThresCfg_UnderPres_IS 1;
BA_ "Platform_VMCU1_Sig" SG_ 1522 Trailer1TPMThresCfg_UnderPres_IS 1;
BA_ "SystemSignalLongSymbol" SG_ 1522 Trailer1TPMThresCfg_UnderPres_IS "Trailer1TPMThresCfg_UnderPres_ISig_6";
BA_ "GenSigCycleTime" SG_ 1522 Trailer1TPMType_ISig_6 100;
BA_ "GenSigCycleTimeActive" SG_ 1522 Trailer1TPMType_ISig_6 100;
BA_ "GenSigStartValue" SG_ 1522 Trailer1TPMType_ISig_6 3;
BA_ "NeedsUpdateBit" SG_ 1522 Trailer1TPMType_ISig_6 1;
BA_ "Platform_VMCU1_Sig" SG_ 1522 Trailer1TPMType_ISig_6 1;
BA_ "GenSigCycleTime" SG_ 1522 Trailer1TPMAxlTireCfg_Axle3_ISig 100;
BA_ "GenSigCycleTimeActive" SG_ 1522 Trailer1TPMAxlTireCfg_Axle3_ISig 100;
BA_ "GenSigStartValue" SG_ 1522 Trailer1TPMAxlTireCfg_Axle3_ISig 7;
BA_ "Platform_VMCU1_Sig" SG_ 1522 Trailer1TPMAxlTireCfg_Axle3_ISig 1;
BA_ "SystemSignalLongSymbol" SG_ 1522 Trailer1TPMAxlTireCfg_Axle3_ISig "Trailer1TPMAxlTireCfg_Axle3_ISig_6";
BA_ "GenSigCycleTime" SG_ 1522 Trailer1TPMAxlTireCfg_Axle4_ISig 100;
BA_ "GenSigCycleTimeActive" SG_ 1522 Trailer1TPMAxlTireCfg_Axle4_ISig 100;
BA_ "GenSigStartValue" SG_ 1522 Trailer1TPMAxlTireCfg_Axle4_ISig 7;
BA_ "Platform_VMCU1_Sig" SG_ 1522 Trailer1TPMAxlTireCfg_Axle4_ISig 1;
BA_ "SystemSignalLongSymbol" SG_ 1522 Trailer1TPMAxlTireCfg_Axle4_ISig "Trailer1TPMAxlTireCfg_Axle4_ISig_6";
BA_ "GenSigCycleTime" SG_ 1349 RearAxleGroupLoad_ISig_6 100;
BA_ "GenSigCycleTimeActive" SG_ 1349 RearAxleGroupLoad_ISig_6 100;
BA_ "GenSigStartValue" SG_ 1349 RearAxleGroupLoad_ISig_6 65535;
BA_ "GenSigCycleTime" SG_ 951 Trailer2LiftAxle2PosReq 100;
BA_ "GenSigCycleTimeActive" SG_ 951 Trailer2LiftAxle2PosReq 100;
BA_ "GenSigStartValue" SG_ 951 Trailer2LiftAxle2PosReq 3;
BA_ "GenSigCycleTime" SG_ 951 Trailer3LiftAxle2PosReq 100;
BA_ "GenSigCycleTimeActive" SG_ 951 Trailer3LiftAxle2PosReq 100;
BA_ "GenSigStartValue" SG_ 951 Trailer3LiftAxle2PosReq 3;
BA_ "GenSigCycleTime" SG_ 951 Trailer1LiftAxle1PosReq 100;
BA_ "GenSigCycleTimeActive" SG_ 951 Trailer1LiftAxle1PosReq 100;
BA_ "GenSigStartValue" SG_ 951 Trailer1LiftAxle1PosReq 3;
BA_ "GenSigCycleTime" SG_ 951 HeadlightLevelAuto_rqst 100;
BA_ "GenSigCycleTimeActive" SG_ 951 HeadlightLevelAuto_rqst 100;
BA_ "GenSigStartValue" SG_ 951 HeadlightLevelAuto_rqst 63;
BA_ "Platform_VMCU1_Sig" SG_ 951 HeadlightLevelAuto_rqst 1;
BA_ "GenSigCycleTime" SG_ 951 Trailer2LiftAxle1PosReq 100;
BA_ "GenSigCycleTimeActive" SG_ 951 Trailer2LiftAxle1PosReq 100;
BA_ "GenSigStartValue" SG_ 951 Trailer2LiftAxle1PosReq 3;
BA_ "GenSigCycleTime" SG_ 951 Trailer3LiftAxle1PosReq 100;
BA_ "GenSigCycleTimeActive" SG_ 951 Trailer3LiftAxle1PosReq 100;
BA_ "GenSigStartValue" SG_ 951 Trailer3LiftAxle1PosReq 3;
BA_ "GenSigCycleTime" SG_ 951 HeadlightAngleAuto_rqst 100;
BA_ "GenSigCycleTimeActive" SG_ 951 HeadlightAngleAuto_rqst 100;
BA_ "GenSigStartValue" SG_ 951 HeadlightAngleAuto_rqst 255;
BA_ "GenSigCycleTime" SG_ 951 Trailer1LiftAxle2PosReq 100;
BA_ "GenSigCycleTimeActive" SG_ 951 Trailer1LiftAxle2PosReq 100;
BA_ "GenSigStartValue" SG_ 951 Trailer1LiftAxle2PosReq 3;
BA_ "GenSigSendType" SG_ 1344 PusherAxleLoad_UB_ISig_6 7;
BA_ "Platform_VMCU1_Sig" SG_ 1344 PusherAxleLoad_UB_ISig_6 1;
BA_ "GenSigSendType" SG_ 1344 TagAxleLoad_UB_ISig_6 7;
BA_ "Platform_VMCU1_Sig" SG_ 1344 TagAxleLoad_UB_ISig_6 1;
BA_ "GenSigCycleTime" SG_ 1344 RegenInhibitVehicleHeight_ISig_6 100;
BA_ "GenSigCycleTimeActive" SG_ 1344 RegenInhibitVehicleHeight_ISig_6 100;
BA_ "GenSigStartValue" SG_ 1344 RegenInhibitVehicleHeight_ISig_6 3;
BA_ "Platform_VMCU1_Sig" SG_ 1344 RegenInhibitVehicleHeight_ISig_6 1;
BA_ "GenSigCycleTime" SG_ 1344 PusherAxleLoad_ISig_6 100;
BA_ "GenSigCycleTimeActive" SG_ 1344 PusherAxleLoad_ISig_6 100;
BA_ "GenSigStartValue" SG_ 1344 PusherAxleLoad_ISig_6 65535;
BA_ "GenSigMaxLatency" SG_ 1344 PusherAxleLoad_ISig_6 255;
BA_ "NeedsUpdateBit" SG_ 1344 PusherAxleLoad_ISig_6 1;
BA_ "Platform_VMCU1_Sig" SG_ 1344 PusherAxleLoad_ISig_6 1;
BA_ "SeToolAncestorID_SIGNAL" SG_ 1344 PusherAxleLoad_ISig_6 "x0000001D0412EB1E";
BA_ "SeToolItemID_SIGNAL" SG_ 1344 PusherAxleLoad_ISig_6 "x0000001D04274C69";
BA_ "SeToolName_SIGNAL" SG_ 1344 PusherAxleLoad_ISig_6 "PusherAxleLoad";
BA_ "SeToolVersion_SIGNAL" SG_ 1344 PusherAxleLoad_ISig_6 "3";
BA_ "GenSigCycleTime" SG_ 1344 TagAxleLoad_ISig_6 100;
BA_ "GenSigCycleTimeActive" SG_ 1344 TagAxleLoad_ISig_6 100;
BA_ "GenSigStartValue" SG_ 1344 TagAxleLoad_ISig_6 65535;
BA_ "GenSigMaxLatency" SG_ 1344 TagAxleLoad_ISig_6 255;
BA_ "NeedsUpdateBit" SG_ 1344 TagAxleLoad_ISig_6 1;
BA_ "Platform_VMCU1_Sig" SG_ 1344 TagAxleLoad_ISig_6 1;
BA_ "SeToolAncestorID_SIGNAL" SG_ 1344 TagAxleLoad_ISig_6 "x0000001D0412EB1E";
BA_ "SeToolItemID_SIGNAL" SG_ 1344 TagAxleLoad_ISig_6 "x0000001D04274C69";
BA_ "SeToolName_SIGNAL" SG_ 1344 TagAxleLoad_ISig_6 "TagAxleLoad";
BA_ "SeToolVersion_SIGNAL" SG_ 1344 TagAxleLoad_ISig_6 "3";
BA_ "GenSigCycleTime" SG_ 1344 RearLeftRoadVibrationIndex 100;
BA_ "GenSigCycleTimeActive" SG_ 1344 RearLeftRoadVibrationIndex 100;
BA_ "GenSigStartValue" SG_ 1344 RearLeftRoadVibrationIndex 65535;
BA_ "Platform_VMCU1_Sig" SG_ 1344 RearLeftRoadVibrationIndex 1;
BA_ "GenSigSendType" SG_ 1343 SecondaryDriveAxleLoad_UB_ISig_6 7;
BA_ "Platform_VMCU1_Sig" SG_ 1343 SecondaryDriveAxleLoad_UB_ISig_6 1;
BA_ "GenSigCycleTime" SG_ 1343 TrailerPosLightRightOutputStat_I 100;
BA_ "GenSigCycleTimeActive" SG_ 1343 TrailerPosLightRightOutputStat_I 100;
BA_ "GenSigStartValue" SG_ 1343 TrailerPosLightRightOutputStat_I 7;
BA_ "SystemSignalLongSymbol" SG_ 1343 TrailerPosLightRightOutputStat_I "TrailerPosLightRightOutputStat_ISig_6";
BA_ "GenSigSendType" SG_ 1343 DriveAxleLoad_UB_ISig_6 7;
BA_ "Platform_VMCU1_Sig" SG_ 1343 DriveAxleLoad_UB_ISig_6 1;
BA_ "GenSigCycleTime" SG_ 1343 TrailerBrakeLightOutputStat_ISig 100;
BA_ "GenSigCycleTimeActive" SG_ 1343 TrailerBrakeLightOutputStat_ISig 100;
BA_ "GenSigStartValue" SG_ 1343 TrailerBrakeLightOutputStat_ISig 7;
BA_ "SystemSignalLongSymbol" SG_ 1343 TrailerBrakeLightOutputStat_ISig "TrailerBrakeLightOutputStat_ISig_6";
BA_ "GenSigCycleTime" SG_ 1343 TrailerDirIndRightOutputStat_ISi 100;
BA_ "GenSigCycleTimeActive" SG_ 1343 TrailerDirIndRightOutputStat_ISi 100;
BA_ "GenSigStartValue" SG_ 1343 TrailerDirIndRightOutputStat_ISi 7;
BA_ "SystemSignalLongSymbol" SG_ 1343 TrailerDirIndRightOutputStat_ISi "TrailerDirIndRightOutputStat_ISig_6";
BA_ "GenSigCycleTime" SG_ 1343 ExtECSPressureUpdateAck 100;
BA_ "GenSigCycleTimeActive" SG_ 1343 ExtECSPressureUpdateAck 100;
BA_ "GenSigStartValue" SG_ 1343 ExtECSPressureUpdateAck 7;
BA_ "GenSigCycleTime" SG_ 1343 DriveAxleLoad_ISig_6 100;
BA_ "GenSigCycleTimeActive" SG_ 1343 DriveAxleLoad_ISig_6 100;
BA_ "GenSigStartValue" SG_ 1343 DriveAxleLoad_ISig_6 65535;
BA_ "GenSigMaxLatency" SG_ 1343 DriveAxleLoad_ISig_6 255;
BA_ "NeedsUpdateBit" SG_ 1343 DriveAxleLoad_ISig_6 1;
BA_ "Platform_VMCU1_Sig" SG_ 1343 DriveAxleLoad_ISig_6 1;
BA_ "SeToolAncestorID_SIGNAL" SG_ 1343 DriveAxleLoad_ISig_6 "x0000001D0412EB1E";
BA_ "SeToolItemID_SIGNAL" SG_ 1343 DriveAxleLoad_ISig_6 "x0000001D04274C69";
BA_ "SeToolName_SIGNAL" SG_ 1343 DriveAxleLoad_ISig_6 "DriveAxleLoad";
BA_ "SeToolVersion_SIGNAL" SG_ 1343 DriveAxleLoad_ISig_6 "3";
BA_ "GenSigCycleTime" SG_ 1343 TrailerPosLightLeftOutputStat_IS 100;
BA_ "GenSigCycleTimeActive" SG_ 1343 TrailerPosLightLeftOutputStat_IS 100;
BA_ "GenSigStartValue" SG_ 1343 TrailerPosLightLeftOutputStat_IS 7;
BA_ "SystemSignalLongSymbol" SG_ 1343 TrailerPosLightLeftOutputStat_IS "TrailerPosLightLeftOutputStat_ISig_6";
BA_ "GenSigCycleTime" SG_ 1343 TrailerDirIndLeftOutputStat_ISig 100;
BA_ "GenSigCycleTimeActive" SG_ 1343 TrailerDirIndLeftOutputStat_ISig 100;
BA_ "GenSigStartValue" SG_ 1343 TrailerDirIndLeftOutputStat_ISig 7;
BA_ "SystemSignalLongSymbol" SG_ 1343 TrailerDirIndLeftOutputStat_ISig "TrailerDirIndLeftOutputStat_ISig_6";
BA_ "GenSigCycleTime" SG_ 1343 LoadDistributionSelected2_ISig_6 100;
BA_ "GenSigCycleTimeActive" SG_ 1343 LoadDistributionSelected2_ISig_6 100;
BA_ "GenSigStartValue" SG_ 1343 LoadDistributionSelected2_ISig_6 15;
BA_ "GenSigCycleTime" SG_ 1343 SecondaryDriveAxleLoad_ISig_6 100;
BA_ "GenSigCycleTimeActive" SG_ 1343 SecondaryDriveAxleLoad_ISig_6 100;
BA_ "GenSigStartValue" SG_ 1343 SecondaryDriveAxleLoad_ISig_6 65535;
BA_ "GenSigMaxLatency" SG_ 1343 SecondaryDriveAxleLoad_ISig_6 255;
BA_ "NeedsUpdateBit" SG_ 1343 SecondaryDriveAxleLoad_ISig_6 1;
BA_ "Platform_VMCU1_Sig" SG_ 1343 SecondaryDriveAxleLoad_ISig_6 1;
BA_ "SeToolAncestorID_SIGNAL" SG_ 1343 SecondaryDriveAxleLoad_ISig_6 "x0000001D0412EB1E";
BA_ "SeToolItemID_SIGNAL" SG_ 1343 SecondaryDriveAxleLoad_ISig_6 "x0000001D04274C69";
BA_ "SeToolName_SIGNAL" SG_ 1343 SecondaryDriveAxleLoad_ISig_6 "SecondaryDriveAxleLoad";
BA_ "SeToolVersion_SIGNAL" SG_ 1343 SecondaryDriveAxleLoad_ISig_6 "3";
BA_ "GenSigCycleTime" SG_ 825 RevLight_cmd 100;
BA_ "GenSigCycleTimeActive" SG_ 825 RevLight_cmd 100;
BA_ "GenSigStartValue" SG_ 825 RevLight_cmd 3;
BA_ "GenSigMaxLatency" SG_ 825 RevLight_cmd 35;
BA_ "Platform_VMCU1_Sig" SG_ 825 RevLight_cmd 1;
BA_ "GenSigCycleTime" SG_ 825 LoadDistributionALDChangeACK_ISi 100;
BA_ "GenSigCycleTimeActive" SG_ 825 LoadDistributionALDChangeACK_ISi 100;
BA_ "GenSigStartValue" SG_ 825 LoadDistributionALDChangeACK_ISi 7;
BA_ "GenSigMaxLatency" SG_ 825 LoadDistributionALDChangeACK_ISi 35;
BA_ "Platform_VMCU1_Sig" SG_ 825 LoadDistributionALDChangeACK_ISi 1;
BA_ "SystemSignalLongSymbol" SG_ 825 LoadDistributionALDChangeACK_ISi "LoadDistributionALDChangeACK_ISig_6";
BA_ "GenSigCycleTime" SG_ 825 LiftAxle2AutoLiftSelected_ISig_6 100;
BA_ "GenSigCycleTimeActive" SG_ 825 LiftAxle2AutoLiftSelected_ISig_6 100;
BA_ "GenSigStartValue" SG_ 825 LiftAxle2AutoLiftSelected_ISig_6 3;
BA_ "GenSigCycleTime" SG_ 825 DriveLevelPosUserInteraction_ISi 100;
BA_ "GenSigCycleTimeActive" SG_ 825 DriveLevelPosUserInteraction_ISi 100;
BA_ "GenSigStartValue" SG_ 825 DriveLevelPosUserInteraction_ISi 7;
BA_ "Platform_VMCU1_Sig" SG_ 825 DriveLevelPosUserInteraction_ISi 1;
BA_ "SystemSignalLongSymbol" SG_ 825 DriveLevelPosUserInteraction_ISi "DriveLevelPosUserInteraction_ISig_6";
BA_ "GenSigCycleTime" SG_ 825 FirstAxleLowerPrioSelected_ISig_ 100;
BA_ "GenSigCycleTimeActive" SG_ 825 FirstAxleLowerPrioSelected_ISig_ 100;
BA_ "GenSigStartValue" SG_ 825 FirstAxleLowerPrioSelected_ISig_ 7;
BA_ "SystemSignalLongSymbol" SG_ 825 FirstAxleLowerPrioSelected_ISig_ "FirstAxleLowerPrioSelected_ISig_6";
BA_ "GenSigCycleTime" SG_ 825 FerryFunctionSwitchChangeACK_ISi 100;
BA_ "GenSigCycleTimeActive" SG_ 825 FerryFunctionSwitchChangeACK_ISi 100;
BA_ "GenSigStartValue" SG_ 825 FerryFunctionSwitchChangeACK_ISi 3;
BA_ "Platform_VMCU1_Sig" SG_ 825 FerryFunctionSwitchChangeACK_ISi 1;
BA_ "SystemSignalLongSymbol" SG_ 825 FerryFunctionSwitchChangeACK_ISi "FerryFunctionSwitchChangeACK_ISig_6";
BA_ "GenSigCycleTime" SG_ 825 TrailerDirInd_status 100;
BA_ "GenSigCycleTimeActive" SG_ 825 TrailerDirInd_status 100;
BA_ "GenSigStartValue" SG_ 825 TrailerDirInd_status 7;
BA_ "GenSigMaxLatency" SG_ 825 TrailerDirInd_status 23;
BA_ "Platform_VMCU1_Sig" SG_ 825 TrailerDirInd_status 1;
BA_ "SeToolAncestorID_SIGNAL" SG_ 825 TrailerDirInd_status "x0000001D04166184";
BA_ "SeToolItemID_SIGNAL" SG_ 825 TrailerDirInd_status "x0000001D0433C84C";
BA_ "SeToolName_SIGNAL" SG_ 825 TrailerDirInd_status "Trailer_Lamp_Error_Info";
BA_ "SeToolVersion_SIGNAL" SG_ 825 TrailerDirInd_status "2";
BA_ "GenSigCycleTime" SG_ 825 RevLightLamp_stat_ISig_6 100;
BA_ "GenSigCycleTimeActive" SG_ 825 RevLightLamp_stat_ISig_6 100;
BA_ "GenSigInactiveValue" SG_ 825 RevLightLamp_stat_ISig_6 7;
BA_ "GenSigStartValue" SG_ 825 RevLightLamp_stat_ISig_6 7;
BA_ "GenSigMaxLatency" SG_ 825 RevLightLamp_stat_ISig_6 35;
BA_ "Platform_VMCU1_Sig" SG_ 825 RevLightLamp_stat_ISig_6 1;
BA_ "GenSigCycleTime" SG_ 825 UnevenLoadWarning_ISig_6 100;
BA_ "GenSigCycleTimeActive" SG_ 825 UnevenLoadWarning_ISig_6 100;
BA_ "GenSigStartValue" SG_ 825 UnevenLoadWarning_ISig_6 3;
BA_ "GenSigMaxLatency" SG_ 825 UnevenLoadWarning_ISig_6 35;
BA_ "Platform_VMCU1_Sig" SG_ 825 UnevenLoadWarning_ISig_6 1;
BA_ "GenSigCycleTime" SG_ 825 LoadDistributionSelected_ISig_6 100;
BA_ "GenSigCycleTimeActive" SG_ 825 LoadDistributionSelected_ISig_6 100;
BA_ "GenSigStartValue" SG_ 825 LoadDistributionSelected_ISig_6 15;
BA_ "GenSigMaxLatency" SG_ 825 LoadDistributionSelected_ISig_6 35;
BA_ "Platform_VMCU1_Sig" SG_ 825 LoadDistributionSelected_ISig_6 1;
BA_ "GenSigCycleTime" SG_ 825 PositionLightRearLamp_stat_ISig_ 100;
BA_ "GenSigCycleTimeActive" SG_ 825 PositionLightRearLamp_stat_ISig_ 100;
BA_ "GenSigInactiveValue" SG_ 825 PositionLightRearLamp_stat_ISig_ 7;
BA_ "GenSigStartValue" SG_ 825 PositionLightRearLamp_stat_ISig_ 7;
BA_ "GenSigMaxLatency" SG_ 825 PositionLightRearLamp_stat_ISig_ 35;
BA_ "Platform_VMCU1_Sig" SG_ 825 PositionLightRearLamp_stat_ISig_ 1;
BA_ "SystemSignalLongSymbol" SG_ 825 PositionLightRearLamp_stat_ISig_ "PositionLightRearLamp_stat_ISig_6";
BA_ "GenSigCycleTime" SG_ 825 LiftAxle1AutoLiftSelected_ISig_6 100;
BA_ "GenSigCycleTimeActive" SG_ 825 LiftAxle1AutoLiftSelected_ISig_6 100;
BA_ "GenSigStartValue" SG_ 825 LiftAxle1AutoLiftSelected_ISig_6 3;
BA_ "GenSigCycleTime" SG_ 825 StartupProhibitStatus_ISig_6 100;
BA_ "GenSigCycleTimeActive" SG_ 825 StartupProhibitStatus_ISig_6 100;
BA_ "GenSigStartValue" SG_ 825 StartupProhibitStatus_ISig_6 3;
BA_ "Platform_VMCU1_Sig" SG_ 825 StartupProhibitStatus_ISig_6 1;
BA_ "GenSigSendType" SG_ 825 BrakeLight_rqst_UB_ISig_6 7;
BA_ "Platform_VMCU1_Sig" SG_ 825 BrakeLight_rqst_UB_ISig_6 1;
BA_ "GenSigCycleTime" SG_ 825 LiftAxle1LowerACK_ISig_6 100;
BA_ "GenSigCycleTimeActive" SG_ 825 LiftAxle1LowerACK_ISig_6 100;
BA_ "GenSigStartValue" SG_ 825 LiftAxle1LowerACK_ISig_6 7;
BA_ "GenSigCycleTime" SG_ 825 RampLevelRequestACK_ISig_6 100;
BA_ "GenSigCycleTimeActive" SG_ 825 RampLevelRequestACK_ISig_6 100;
BA_ "GenSigStartValue" SG_ 825 RampLevelRequestACK_ISig_6 3;
BA_ "Platform_VMCU1_Sig" SG_ 825 RampLevelRequestACK_ISig_6 1;
BA_ "GenSigCycleTime" SG_ 825 BrakeLightLamp_stat_ISig_6 100;
BA_ "GenSigCycleTimeActive" SG_ 825 BrakeLightLamp_stat_ISig_6 100;
BA_ "GenSigInactiveValue" SG_ 825 BrakeLightLamp_stat_ISig_6 7;
BA_ "GenSigStartValue" SG_ 825 BrakeLightLamp_stat_ISig_6 7;
BA_ "GenSigMaxLatency" SG_ 825 BrakeLightLamp_stat_ISig_6 35;
BA_ "Platform_VMCU1_Sig" SG_ 825 BrakeLightLamp_stat_ISig_6 1;
BA_ "GenSigSendType" SG_ 825 BrakeLightConvoy_rqst_UB_ISig_6 7;
BA_ "Platform_VMCU1_Sig" SG_ 825 BrakeLightConvoy_rqst_UB_ISig_6 1;
BA_ "GenSigCycleTime" SG_ 825 TrailerABSStatus_ISig_6 100;
BA_ "GenSigCycleTimeActive" SG_ 825 TrailerABSStatus_ISig_6 100;
BA_ "GenSigStartValue" SG_ 825 TrailerABSStatus_ISig_6 3;
BA_ "GenSigMaxLatency" SG_ 825 TrailerABSStatus_ISig_6 35;
BA_ "Platform_VMCU1_Sig" SG_ 825 TrailerABSStatus_ISig_6 1;
BA_ "GenSigCycleTime" SG_ 825 FogLightRearLamp_stat_ISig_6 100;
BA_ "GenSigCycleTimeActive" SG_ 825 FogLightRearLamp_stat_ISig_6 100;
BA_ "GenSigInactiveValue" SG_ 825 FogLightRearLamp_stat_ISig_6 7;
BA_ "GenSigStartValue" SG_ 825 FogLightRearLamp_stat_ISig_6 7;
BA_ "GenSigMaxLatency" SG_ 825 FogLightRearLamp_stat_ISig_6 35;
BA_ "Platform_VMCU1_Sig" SG_ 825 FogLightRearLamp_stat_ISig_6 1;
BA_ "GenSigCycleTime" SG_ 825 ECSLimpHomeNotification_ISig_6 100;
BA_ "GenSigCycleTimeActive" SG_ 825 ECSLimpHomeNotification_ISig_6 100;
BA_ "GenSigStartValue" SG_ 825 ECSLimpHomeNotification_ISig_6 7;
BA_ "GenSigMaxLatency" SG_ 825 ECSLimpHomeNotification_ISig_6 35;
BA_ "Platform_VMCU1_Sig" SG_ 825 ECSLimpHomeNotification_ISig_6 1;
BA_ "GenSigCycleTime" SG_ 825 BrakeLight_rqst_ISig_6 100;
BA_ "GenSigCycleTimeActive" SG_ 825 BrakeLight_rqst_ISig_6 100;
BA_ "GenSigStartValue" SG_ 825 BrakeLight_rqst_ISig_6 7;
BA_ "GenSigMaxLatency" SG_ 825 BrakeLight_rqst_ISig_6 35;
BA_ "NeedsUpdateBit" SG_ 825 BrakeLight_rqst_ISig_6 1;
BA_ "Platform_VMCU1_Sig" SG_ 825 BrakeLight_rqst_ISig_6 1;
BA_ "GenSigCycleTime" SG_ 825 ECSValveActivationAllowed 100;
BA_ "GenSigCycleTimeActive" SG_ 825 ECSValveActivationAllowed 100;
BA_ "GenSigStartValue" SG_ 825 ECSValveActivationAllowed 3;
BA_ "GenSigMaxLatency" SG_ 825 ECSValveActivationAllowed 35;
BA_ "Platform_VMCU1_Sig" SG_ 825 ECSValveActivationAllowed 1;
BA_ "GenSigCycleTime" SG_ 825 BrakeLightConvoy_rqst_ISig_6 100;
BA_ "GenSigCycleTimeActive" SG_ 825 BrakeLightConvoy_rqst_ISig_6 100;
BA_ "GenSigStartValue" SG_ 825 BrakeLightConvoy_rqst_ISig_6 3;
BA_ "GenSigMaxLatency" SG_ 825 BrakeLightConvoy_rqst_ISig_6 35;
BA_ "NeedsUpdateBit" SG_ 825 BrakeLightConvoy_rqst_ISig_6 1;
BA_ "Platform_VMCU1_Sig" SG_ 825 BrakeLightConvoy_rqst_ISig_6 1;
BA_ "GenSigCycleTime" SG_ 825 FrontParkBrakeOverrideInd_ISig_6 100;
BA_ "GenSigCycleTimeActive" SG_ 825 FrontParkBrakeOverrideInd_ISig_6 100;
BA_ "GenSigStartValue" SG_ 825 FrontParkBrakeOverrideInd_ISig_6 3;
BA_ "GenSigCycleTime" SG_ 948 FrontAxleInBumperRange_ISig_6 100;
BA_ "GenSigCycleTimeActive" SG_ 948 FrontAxleInBumperRange_ISig_6 100;
BA_ "GenSigStartValue" SG_ 948 FrontAxleInBumperRange_ISig_6 3;
BA_ "GenSigMaxLatency" SG_ 948 FrontAxleInBumperRange_ISig_6 27;
BA_ "NeedsUpdateBit" SG_ 948 FrontAxleInBumperRange_ISig_6 1;
BA_ "Platform_VMCU1_Sig" SG_ 948 FrontAxleInBumperRange_ISig_6 1;
BA_ "SeToolAncestorID_SIGNAL" SG_ 948 FrontAxleInBumperRange_ISig_6 "x0000001D04149915";
BA_ "SeToolItemID_SIGNAL" SG_ 948 FrontAxleInBumperRange_ISig_6 "x0000001D04149915";
BA_ "SeToolName_SIGNAL" SG_ 948 FrontAxleInBumperRange_ISig_6 "FrontAxleInBumperRange";
BA_ "SeToolVersion_SIGNAL" SG_ 948 FrontAxleInBumperRange_ISig_6 "1";
BA_ "GenSigCycleTime" SG_ 948 Rear1ClutchStatus 100;
BA_ "GenSigCycleTimeActive" SG_ 948 Rear1ClutchStatus 100;
BA_ "GenSigStartValue" SG_ 948 Rear1ClutchStatus 3;
BA_ "Platform_VMCU1_Sig" SG_ 948 Rear1ClutchStatus 1;
BA_ "GenSigCycleTime" SG_ 948 FrontRollAngleRef 100;
BA_ "GenSigCycleTimeActive" SG_ 948 FrontRollAngleRef 100;
BA_ "GenSigStartValue" SG_ 948 FrontRollAngleRef 65535;
BA_ "GenSigMaxLatency" SG_ 948 FrontRollAngleRef 57;
BA_ "Platform_VMCU1_Sig" SG_ 948 FrontRollAngleRef 1;
BA_ "SeToolAncestorID_SIGNAL" SG_ 948 FrontRollAngleRef "x0000001D04348121";
BA_ "SeToolItemID_SIGNAL" SG_ 948 FrontRollAngleRef "x0000001D04348121";
BA_ "SeToolName_SIGNAL" SG_ 948 FrontRollAngleRef "FrontRollAngleRef";
BA_ "SeToolVersion_SIGNAL" SG_ 948 FrontRollAngleRef "1";
BA_ "GenSigCycleTime" SG_ 948 FrontSideKneelingAngleRef 100;
BA_ "GenSigCycleTimeActive" SG_ 948 FrontSideKneelingAngleRef 100;
BA_ "GenSigStartValue" SG_ 948 FrontSideKneelingAngleRef 65535;
BA_ "Platform_VMCU1_Sig" SG_ 948 FrontSideKneelingAngleRef 1;
BA_ "GenSigCycleTime" SG_ 948 LoadDistributionRequestedACK_ISi 100;
BA_ "GenSigCycleTimeActive" SG_ 948 LoadDistributionRequestedACK_ISi 100;
BA_ "GenSigStartValue" SG_ 948 LoadDistributionRequestedACK_ISi 7;
BA_ "Platform_VMCU1_Sig" SG_ 948 LoadDistributionRequestedACK_ISi 1;
BA_ "SystemSignalLongSymbol" SG_ 948 LoadDistributionRequestedACK_ISi "LoadDistributionRequestedACK_ISig_6";
BA_ "GenSigCycleTime" SG_ 948 TotalFrontBellowTorqueRef 100;
BA_ "GenSigCycleTimeActive" SG_ 948 TotalFrontBellowTorqueRef 100;
BA_ "GenSigStartValue" SG_ 948 TotalFrontBellowTorqueRef 65535;
BA_ "GenSigMaxLatency" SG_ 948 TotalFrontBellowTorqueRef 57;
BA_ "Platform_VMCU1_Sig" SG_ 948 TotalFrontBellowTorqueRef 1;
BA_ "SeToolAncestorID_SIGNAL" SG_ 948 TotalFrontBellowTorqueRef "x0000001D0414B288";
BA_ "SeToolItemID_SIGNAL" SG_ 948 TotalFrontBellowTorqueRef "x0000001D04384364";
BA_ "SeToolName_SIGNAL" SG_ 948 TotalFrontBellowTorqueRef "TotalFrontBellowTorqueRef";
BA_ "SeToolVersion_SIGNAL" SG_ 948 TotalFrontBellowTorqueRef "2";
BA_ "GenSigCycleTime" SG_ 948 DirIndRearLamp_Stat_ISig_6 100;
BA_ "GenSigCycleTimeActive" SG_ 948 DirIndRearLamp_Stat_ISig_6 100;
BA_ "GenSigStartValue" SG_ 948 DirIndRearLamp_Stat_ISig_6 7;
BA_ "Platform_VMCU1_Sig" SG_ 948 DirIndRearLamp_Stat_ISig_6 1;
BA_ "GenSigCycleTime" SG_ 948 FrontEndPositionStatus_ISig_6 100;
BA_ "GenSigCycleTimeActive" SG_ 948 FrontEndPositionStatus_ISig_6 100;
BA_ "GenSigInactiveValue" SG_ 948 FrontEndPositionStatus_ISig_6 7;
BA_ "GenSigStartValue" SG_ 948 FrontEndPositionStatus_ISig_6 7;
BA_ "GenSigMaxLatency" SG_ 948 FrontEndPositionStatus_ISig_6 35;
BA_ "Platform_VMCU1_Sig" SG_ 948 FrontEndPositionStatus_ISig_6 1;
BA_ "GenSigSendType" SG_ 948 FrontAxleInBumperRange_UB_ISig_6 7;
BA_ "Platform_VMCU1_Sig" SG_ 948 FrontAxleInBumperRange_UB_ISig_6 1;
BA_ "GenSigCycleTime" SG_ 947 FPBRMMIStat_FPBRChangeAck_ISig_6 100;
BA_ "GenSigCycleTimeActive" SG_ 947 FPBRMMIStat_FPBRChangeAck_ISig_6 100;
BA_ "GenSigStartValue" SG_ 947 FPBRMMIStat_FPBRChangeAck_ISig_6 3;
BA_ "Platform_VMCU1_Sig" SG_ 947 FPBRMMIStat_FPBRChangeAck_ISig_6 1;
BA_ "GenSigCycleTime" SG_ 947 FrontLevRefCtrl_ShortPushCnt 100;
BA_ "GenSigCycleTimeActive" SG_ 947 FrontLevRefCtrl_ShortPushCnt 100;
BA_ "GenSigStartValue" SG_ 947 FrontLevRefCtrl_ShortPushCnt 255;
BA_ "Platform_VMCU1_Sig" SG_ 947 FrontLevRefCtrl_ShortPushCnt 1;
BA_ "GenSigCycleTime" SG_ 947 RelativeLevelRearAxleRight_ISig_ 100;
BA_ "GenSigCycleTimeActive" SG_ 947 RelativeLevelRearAxleRight_ISig_ 100;
BA_ "GenSigStartValue" SG_ 947 RelativeLevelRearAxleRight_ISig_ 65535;
BA_ "GenSigMaxLatency" SG_ 947 RelativeLevelRearAxleRight_ISig_ 56;
BA_ "Platform_VMCU1_Sig" SG_ 947 RelativeLevelRearAxleRight_ISig_ 1;
BA_ "SeToolAncestorID_SIGNAL" SG_ 947 RelativeLevelRearAxleRight_ISig_ "x0000001D0412EE40";
BA_ "SeToolItemID_SIGNAL" SG_ 947 RelativeLevelRearAxleRight_ISig_ "x0000001D04384E50";
BA_ "SeToolName_SIGNAL" SG_ 947 RelativeLevelRearAxleRight_ISig_ "RelativeLevelRearAxleRight";
BA_ "SeToolVersion_SIGNAL" SG_ 947 RelativeLevelRearAxleRight_ISig_ "2";
BA_ "SystemSignalLongSymbol" SG_ 947 RelativeLevelRearAxleRight_ISig_ "RelativeLevelRearAxleRight_ISig_6";
BA_ "GenSigCycleTime" SG_ 947 RelativeLevelRearAxleLeft_ISig_6 100;
BA_ "GenSigCycleTimeActive" SG_ 947 RelativeLevelRearAxleLeft_ISig_6 100;
BA_ "GenSigStartValue" SG_ 947 RelativeLevelRearAxleLeft_ISig_6 65535;
BA_ "GenSigMaxLatency" SG_ 947 RelativeLevelRearAxleLeft_ISig_6 56;
BA_ "Platform_VMCU1_Sig" SG_ 947 RelativeLevelRearAxleLeft_ISig_6 1;
BA_ "SeToolAncestorID_SIGNAL" SG_ 947 RelativeLevelRearAxleLeft_ISig_6 "x0000001D0412EE3E";
BA_ "SeToolItemID_SIGNAL" SG_ 947 RelativeLevelRearAxleLeft_ISig_6 "x0000001D04384E3D";
BA_ "SeToolName_SIGNAL" SG_ 947 RelativeLevelRearAxleLeft_ISig_6 "RelativeLevelRearAxleLeft";
BA_ "SeToolVersion_SIGNAL" SG_ 947 RelativeLevelRearAxleLeft_ISig_6 "2";
BA_ "GenSigCycleTime" SG_ 947 FPBRMMIStat_FPBRStatusInd_ISig_6 100;
BA_ "GenSigCycleTimeActive" SG_ 947 FPBRMMIStat_FPBRStatusInd_ISig_6 100;
BA_ "GenSigStartValue" SG_ 947 FPBRMMIStat_FPBRStatusInd_ISig_6 3;
BA_ "Platform_VMCU1_Sig" SG_ 947 FPBRMMIStat_FPBRStatusInd_ISig_6 1;
BA_ "GenSigCycleTime" SG_ 947 LiftAxle1LiftAllowed_Stat 100;
BA_ "GenSigCycleTimeActive" SG_ 947 LiftAxle1LiftAllowed_Stat 100;
BA_ "GenSigStartValue" SG_ 947 LiftAxle1LiftAllowed_Stat 7;
BA_ "Platform_VMCU1_Sig" SG_ 947 LiftAxle1LiftAllowed_Stat 1;
BA_ "GenSigCycleTime" SG_ 947 FrontLevRefCtrl_LevelRef 100;
BA_ "GenSigCycleTimeActive" SG_ 947 FrontLevRefCtrl_LevelRef 100;
BA_ "GenSigStartValue" SG_ 947 FrontLevRefCtrl_LevelRef 65535;
BA_ "Platform_VMCU1_Sig" SG_ 947 FrontLevRefCtrl_LevelRef 1;
BA_ "GenSigCycleTime" SG_ 530 TrailerWithoutABS_ISig_6 100;
BA_ "GenSigCycleTimeActive" SG_ 530 TrailerWithoutABS_ISig_6 100;
BA_ "GenSigStartValue" SG_ 530 TrailerWithoutABS_ISig_6 3;
BA_ "GenSigMaxLatency" SG_ 530 TrailerWithoutABS_ISig_6 35;
BA_ "NeedsUpdateBit" SG_ 530 TrailerWithoutABS_ISig_6 1;
BA_ "Platform_VMCU1_Sig" SG_ 530 TrailerWithoutABS_ISig_6 1;
BA_ "SeToolAncestorID_SIGNAL" SG_ 530 TrailerWithoutABS_ISig_6 "x0000001D0410CF7C";
BA_ "SeToolItemID_SIGNAL" SG_ 530 TrailerWithoutABS_ISig_6 "x0000001D0410CF7C";
BA_ "SeToolName_SIGNAL" SG_ 530 TrailerWithoutABS_ISig_6 "TrailerWithoutABS";
BA_ "SeToolVersion_SIGNAL" SG_ 530 TrailerWithoutABS_ISig_6 "1";
BA_ "GenSigSendType" SG_ 530 TrailerConnected_UB_ISig_6 7;
BA_ "Platform_VMCU1_Sig" SG_ 530 TrailerConnected_UB_ISig_6 1;
BA_ "GenSigCycleTime" SG_ 530 TrailerConnected_ISig_6 100;
BA_ "GenSigCycleTimeActive" SG_ 530 TrailerConnected_ISig_6 100;
BA_ "GenSigStartValue" SG_ 530 TrailerConnected_ISig_6 3;
BA_ "GenSigMaxLatency" SG_ 530 TrailerConnected_ISig_6 35;
BA_ "NeedsUpdateBit" SG_ 530 TrailerConnected_ISig_6 1;
BA_ "Platform_VMCU1_Sig" SG_ 530 TrailerConnected_ISig_6 1;
BA_ "GenSigCycleTime" SG_ 530 SupplyPressure 100;
BA_ "GenSigCycleTimeActive" SG_ 530 SupplyPressure 100;
BA_ "GenSigStartValue" SG_ 530 SupplyPressure 255;
BA_ "GenSigMaxLatency" SG_ 530 SupplyPressure 55;
BA_ "Platform_VMCU1_Sig" SG_ 530 SupplyPressure 1;
BA_ "SeToolAncestorID_SIGNAL" SG_ 530 SupplyPressure "x0000001D0422262B";
BA_ "SeToolItemID_SIGNAL" SG_ 530 SupplyPressure "x0000001D0422262B";
BA_ "SeToolName_SIGNAL" SG_ 530 SupplyPressure "SupplyPressure";
BA_ "SeToolVersion_SIGNAL" SG_ 530 SupplyPressure "1";
BA_ "GenSigCycleTime" SG_ 530 PitchAngle 100;
BA_ "GenSigCycleTimeActive" SG_ 530 PitchAngle 100;
BA_ "GenSigStartValue" SG_ 530 PitchAngle 65535;
BA_ "GenSigMaxLatency" SG_ 530 PitchAngle 55;
BA_ "Platform_VMCU1_Sig" SG_ 530 PitchAngle 1;
BA_ "SeToolAncestorID_SIGNAL" SG_ 530 PitchAngle "x0000001D04348121";
BA_ "SeToolItemID_SIGNAL" SG_ 530 PitchAngle "x0000001D04348121";
BA_ "SeToolName_SIGNAL" SG_ 530 PitchAngle "PitchAngle";
BA_ "SeToolVersion_SIGNAL" SG_ 530 PitchAngle "1";
BA_ "GenSigCycleTime" SG_ 530 SWBrakeSwitch_ISig_6 100;
BA_ "GenSigCycleTimeActive" SG_ 530 SWBrakeSwitch_ISig_6 100;
BA_ "GenSigStartValue" SG_ 530 SWBrakeSwitch_ISig_6 3;
BA_ "GenSigMaxLatency" SG_ 530 SWBrakeSwitch_ISig_6 23;
BA_ "NeedsUpdateBit" SG_ 530 SWBrakeSwitch_ISig_6 1;
BA_ "Platform_VMCU1_Sig" SG_ 530 SWBrakeSwitch_ISig_6 1;
BA_ "SeToolAncestorID_SIGNAL" SG_ 530 SWBrakeSwitch_ISig_6 "x0000001D0432AB74";
BA_ "SeToolItemID_SIGNAL" SG_ 530 SWBrakeSwitch_ISig_6 "x0000001D0432AB74";
BA_ "SeToolName_SIGNAL" SG_ 530 SWBrakeSwitch_ISig_6 "SWBrakeSwitch";
BA_ "SeToolVersion_SIGNAL" SG_ 530 SWBrakeSwitch_ISig_6 "1";
BA_ "GenSigCycleTime" SG_ 530 PitchAngleRef 100;
BA_ "GenSigCycleTimeActive" SG_ 530 PitchAngleRef 100;
BA_ "GenSigStartValue" SG_ 530 PitchAngleRef 65535;
BA_ "GenSigMaxLatency" SG_ 530 PitchAngleRef 55;
BA_ "Platform_VMCU1_Sig" SG_ 530 PitchAngleRef 1;
BA_ "SeToolAncestorID_SIGNAL" SG_ 530 PitchAngleRef "x0000001D04348121";
BA_ "SeToolItemID_SIGNAL" SG_ 530 PitchAngleRef "x0000001D04348121";
BA_ "SeToolName_SIGNAL" SG_ 530 PitchAngleRef "PitchAngleRef";
BA_ "SeToolVersion_SIGNAL" SG_ 530 PitchAngleRef "1";
BA_ "GenSigCycleTime" SG_ 530 RearAxle2DiffLock_stat_ISig_6 100;
BA_ "GenSigCycleTimeActive" SG_ 530 RearAxle2DiffLock_stat_ISig_6 100;
BA_ "GenSigStartValue" SG_ 530 RearAxle2DiffLock_stat_ISig_6 3;
BA_ "GenSigMaxLatency" SG_ 530 RearAxle2DiffLock_stat_ISig_6 23;
BA_ "NeedsUpdateBit" SG_ 530 RearAxle2DiffLock_stat_ISig_6 1;
BA_ "Platform_VMCU1_Sig" SG_ 530 RearAxle2DiffLock_stat_ISig_6 1;
BA_ "SeToolAncestorID_SIGNAL" SG_ 530 RearAxle2DiffLock_stat_ISig_6 "x0000001D04128800";
BA_ "SeToolItemID_SIGNAL" SG_ 530 RearAxle2DiffLock_stat_ISig_6 "x0000001D04128800";
BA_ "SeToolName_SIGNAL" SG_ 530 RearAxle2DiffLock_stat_ISig_6 "DifferentialLockState-RearAxle2";
BA_ "SeToolVersion_SIGNAL" SG_ 530 RearAxle2DiffLock_stat_ISig_6 "1";
BA_ "GenSigSendType" SG_ 530 TrailerWithoutABS_UB_ISig_6 7;
BA_ "Platform_VMCU1_Sig" SG_ 530 TrailerWithoutABS_UB_ISig_6 1;
BA_ "GenSigSendType" SG_ 530 SWBrakeSwitch_UB_ISig_6 7;
BA_ "Platform_VMCU1_Sig" SG_ 530 SWBrakeSwitch_UB_ISig_6 1;
BA_ "GenSigSendType" SG_ 530 CentralRearDiffLock_stat_UB_ISig 7;
BA_ "Platform_VMCU1_Sig" SG_ 530 CentralRearDiffLock_stat_UB_ISig 1;
BA_ "SystemSignalLongSymbol" SG_ 530 CentralRearDiffLock_stat_UB_ISig "CentralRearDiffLock_stat_UB_ISig_6";
BA_ "GenSigCycleTime" SG_ 530 CentralRearDiffLock_stat_ISig_6 100;
BA_ "GenSigCycleTimeActive" SG_ 530 CentralRearDiffLock_stat_ISig_6 100;
BA_ "GenSigStartValue" SG_ 530 CentralRearDiffLock_stat_ISig_6 3;
BA_ "GenSigMaxLatency" SG_ 530 CentralRearDiffLock_stat_ISig_6 23;
BA_ "NeedsUpdateBit" SG_ 530 CentralRearDiffLock_stat_ISig_6 1;
BA_ "Platform_VMCU1_Sig" SG_ 530 CentralRearDiffLock_stat_ISig_6 1;
BA_ "SeToolAncestorID_SIGNAL" SG_ 530 CentralRearDiffLock_stat_ISig_6 "x0000001D04119DA2";
BA_ "SeToolItemID_SIGNAL" SG_ 530 CentralRearDiffLock_stat_ISig_6 "x0000001D04119DA2";
BA_ "SeToolName_SIGNAL" SG_ 530 CentralRearDiffLock_stat_ISig_6 "Differential LockState-CentralRear";
BA_ "SeToolVersion_SIGNAL" SG_ 530 CentralRearDiffLock_stat_ISig_6 "1";
BA_ "GenSigCycleTime" SG_ 530 BackToDriveReqACK_ISig_6 100;
BA_ "GenSigCycleTimeActive" SG_ 530 BackToDriveReqACK_ISig_6 100;
BA_ "GenSigStartValue" SG_ 530 BackToDriveReqACK_ISig_6 3;
BA_ "Platform_VMCU1_Sig" SG_ 530 BackToDriveReqACK_ISig_6 1;
BA_ "GenSigCycleTime" SG_ 530 RearAxle1DiffLock_stat_ISig_6 100;
BA_ "GenSigCycleTimeActive" SG_ 530 RearAxle1DiffLock_stat_ISig_6 100;
BA_ "GenSigStartValue" SG_ 530 RearAxle1DiffLock_stat_ISig_6 3;
BA_ "GenSigMaxLatency" SG_ 530 RearAxle1DiffLock_stat_ISig_6 23;
BA_ "NeedsUpdateBit" SG_ 530 RearAxle1DiffLock_stat_ISig_6 1;
BA_ "Platform_VMCU1_Sig" SG_ 530 RearAxle1DiffLock_stat_ISig_6 1;
BA_ "SeToolAncestorID_SIGNAL" SG_ 530 RearAxle1DiffLock_stat_ISig_6 "x0000001D041287FE";
BA_ "SeToolItemID_SIGNAL" SG_ 530 RearAxle1DiffLock_stat_ISig_6 "x0000001D043FB883";
BA_ "SeToolName_SIGNAL" SG_ 530 RearAxle1DiffLock_stat_ISig_6 "DifferentialLockState-RearAxle1";
BA_ "SeToolVersion_SIGNAL" SG_ 530 RearAxle1DiffLock_stat_ISig_6 "2";
BA_ "GenSigSendType" SG_ 530 RearAxle2DiffLock_stat_UB_ISig_6 7;
BA_ "Platform_VMCU1_Sig" SG_ 530 RearAxle2DiffLock_stat_UB_ISig_6 1;
BA_ "GenSigSendType" SG_ 530 RearAxle1DiffLock_stat_UB_ISig_6 7;
BA_ "Platform_VMCU1_Sig" SG_ 530 RearAxle1DiffLock_stat_UB_ISig_6 1;
BA_ "GenSigCycleTime" SG_ 528 RearEndPositionStatus_ISig_6 100;
BA_ "GenSigCycleTimeActive" SG_ 528 RearEndPositionStatus_ISig_6 100;
BA_ "GenSigInactiveValue" SG_ 528 RearEndPositionStatus_ISig_6 7;
BA_ "GenSigStartValue" SG_ 528 RearEndPositionStatus_ISig_6 7;
BA_ "Platform_VMCU1_Sig" SG_ 528 RearEndPositionStatus_ISig_6 1;
BA_ "GenSigCycleTime" SG_ 528 FrontFerryFunctionCmd 100;
BA_ "GenSigCycleTimeActive" SG_ 528 FrontFerryFunctionCmd 100;
BA_ "GenSigStartValue" SG_ 528 FrontFerryFunctionCmd 7;
BA_ "GenSigMaxLatency" SG_ 528 FrontFerryFunctionCmd 23;
BA_ "Platform_VMCU1_Sig" SG_ 528 FrontFerryFunctionCmd 1;
BA_ "SeToolAncestorID_SIGNAL" SG_ 528 FrontFerryFunctionCmd "x0000001D04374A6A";
BA_ "SeToolItemID_SIGNAL" SG_ 528 FrontFerryFunctionCmd "x0000001D04374A6A";
BA_ "SeToolName_SIGNAL" SG_ 528 FrontFerryFunctionCmd "FrontDrainBellowsReq";
BA_ "SeToolVersion_SIGNAL" SG_ 528 FrontFerryFunctionCmd "1";
BA_ "GenSigCycleTime" SG_ 528 RideHeightStatus_ISig_6 100;
BA_ "GenSigCycleTimeActive" SG_ 528 RideHeightStatus_ISig_6 100;
BA_ "GenSigStartValue" SG_ 528 RideHeightStatus_ISig_6 15;
BA_ "GenSigMaxLatency" SG_ 528 RideHeightStatus_ISig_6 23;
BA_ "Platform_VMCU1_Sig" SG_ 528 RideHeightStatus_ISig_6 1;
BA_ "SeToolAncestorID_SIGNAL" SG_ 528 RideHeightStatus_ISig_6 "x0000001D041304DF";
BA_ "SeToolItemID_SIGNAL" SG_ 528 RideHeightStatus_ISig_6 "x0000001D0442415B";
BA_ "SeToolName_SIGNAL" SG_ 528 RideHeightStatus_ISig_6 "RideHeightStatus";
BA_ "SeToolVersion_SIGNAL" SG_ 528 RideHeightStatus_ISig_6 "3";
BA_ "GenSigCycleTime" SG_ 528 KneelingInformation_ISig_6 100;
BA_ "GenSigCycleTimeActive" SG_ 528 KneelingInformation_ISig_6 100;
BA_ "GenSigStartValue" SG_ 528 KneelingInformation_ISig_6 15;
BA_ "Platform_VMCU1_Sig" SG_ 528 KneelingInformation_ISig_6 1;
BA_ "GenSigCycleTime" SG_ 528 RampHeightOutsideTargetRange_ISi 100;
BA_ "GenSigCycleTimeActive" SG_ 528 RampHeightOutsideTargetRange_ISi 100;
BA_ "GenSigInactiveValue" SG_ 528 RampHeightOutsideTargetRange_ISi 7;
BA_ "GenSigStartValue" SG_ 528 RampHeightOutsideTargetRange_ISi 7;
BA_ "Platform_VMCU1_Sig" SG_ 528 RampHeightOutsideTargetRange_ISi 1;
BA_ "SystemSignalLongSymbol" SG_ 528 RampHeightOutsideTargetRange_ISi "RampHeightOutsideTargetRange_ISig_6";
BA_ "GenSigCycleTime" SG_ 528 LiftAxle1PositionStatus_ISig_6 100;
BA_ "GenSigCycleTimeActive" SG_ 528 LiftAxle1PositionStatus_ISig_6 100;
BA_ "GenSigStartValue" SG_ 528 LiftAxle1PositionStatus_ISig_6 7;
BA_ "GenSigMaxLatency" SG_ 528 LiftAxle1PositionStatus_ISig_6 23;
BA_ "Platform_VMCU1_Sig" SG_ 528 LiftAxle1PositionStatus_ISig_6 1;
BA_ "SeToolAncestorID_SIGNAL" SG_ 528 LiftAxle1PositionStatus_ISig_6 "x0000001D04131A08";
BA_ "SeToolItemID_SIGNAL" SG_ 528 LiftAxle1PositionStatus_ISig_6 "x0000001D0423C412";
BA_ "SeToolName_SIGNAL" SG_ 528 LiftAxle1PositionStatus_ISig_6 "LiftAxle1PositionStatus";
BA_ "SeToolVersion_SIGNAL" SG_ 528 LiftAxle1PositionStatus_ISig_6 "2";
BA_ "GenSigCycleTime" SG_ 528 HeightAdjustmentAllowed_ISig_6 100;
BA_ "GenSigCycleTimeActive" SG_ 528 HeightAdjustmentAllowed_ISig_6 100;
BA_ "GenSigStartValue" SG_ 528 HeightAdjustmentAllowed_ISig_6 3;
BA_ "Platform_VMCU1_Sig" SG_ 528 HeightAdjustmentAllowed_ISig_6 1;
BA_ "GenSigCycleTime" SG_ 528 FerryFunctionStatus_ISig_6 100;
BA_ "GenSigCycleTimeActive" SG_ 528 FerryFunctionStatus_ISig_6 100;
BA_ "GenSigStartValue" SG_ 528 FerryFunctionStatus_ISig_6 7;
BA_ "GenSigMaxLatency" SG_ 528 FerryFunctionStatus_ISig_6 35;
BA_ "Platform_VMCU1_Sig" SG_ 528 FerryFunctionStatus_ISig_6 1;
BA_ "GenSigCycleTime" SG_ 528 LoadDistributionFuncSelected_ISi 100;
BA_ "GenSigCycleTimeActive" SG_ 528 LoadDistributionFuncSelected_ISi 100;
BA_ "GenSigStartValue" SG_ 528 LoadDistributionFuncSelected_ISi 15;
BA_ "GenSigMaxLatency" SG_ 528 LoadDistributionFuncSelected_ISi 23;
BA_ "Platform_VMCU1_Sig" SG_ 528 LoadDistributionFuncSelected_ISi 1;
BA_ "SeToolAncestorID_SIGNAL" SG_ 528 LoadDistributionFuncSelected_ISi "x0000001D04355313";
BA_ "SeToolItemID_SIGNAL" SG_ 528 LoadDistributionFuncSelected_ISi "x0000001D043AB18A";
BA_ "SeToolName_SIGNAL" SG_ 528 LoadDistributionFuncSelected_ISi "LoadDistributionRequested";
BA_ "SeToolVersion_SIGNAL" SG_ 528 LoadDistributionFuncSelected_ISi "2";
BA_ "SystemSignalLongSymbol" SG_ 528 LoadDistributionFuncSelected_ISi "LoadDistributionFuncSelected_ISig_6";
BA_ "GenSigSendType" SG_ 528 LevelControlInformation_UB_ISig_ 7;
BA_ "Platform_VMCU1_Sig" SG_ 528 LevelControlInformation_UB_ISig_ 1;
BA_ "SystemSignalLongSymbol" SG_ 528 LevelControlInformation_UB_ISig_ "LevelControlInformation_UB_ISig_6";
BA_ "GenSigCycleTime" SG_ 528 RollEndPositionStatus_ISig_6 100;
BA_ "GenSigCycleTimeActive" SG_ 528 RollEndPositionStatus_ISig_6 100;
BA_ "GenSigInactiveValue" SG_ 528 RollEndPositionStatus_ISig_6 7;
BA_ "GenSigStartValue" SG_ 528 RollEndPositionStatus_ISig_6 7;
BA_ "Platform_VMCU1_Sig" SG_ 528 RollEndPositionStatus_ISig_6 1;
BA_ "GenSigCycleTime" SG_ 528 HeightControlMode 100;
BA_ "GenSigCycleTimeActive" SG_ 528 HeightControlMode 100;
BA_ "GenSigStartValue" SG_ 528 HeightControlMode 15;
BA_ "GenSigMaxLatency" SG_ 528 HeightControlMode 23;
BA_ "Platform_VMCU1_Sig" SG_ 528 HeightControlMode 1;
BA_ "SeToolAncestorID_SIGNAL" SG_ 528 HeightControlMode "x0000001D04348B44";
BA_ "SeToolItemID_SIGNAL" SG_ 528 HeightControlMode "x0000001D04348B44";
BA_ "SeToolName_SIGNAL" SG_ 528 HeightControlMode "LevelFunctionControlReq";
BA_ "SeToolVersion_SIGNAL" SG_ 528 HeightControlMode "1";
BA_ "GenSigCycleTime" SG_ 528 RideHeightFunctionStatus_ISig_6 100;
BA_ "GenSigCycleTimeActive" SG_ 528 RideHeightFunctionStatus_ISig_6 100;
BA_ "GenSigStartValue" SG_ 528 RideHeightFunctionStatus_ISig_6 15;
BA_ "GenSigMaxLatency" SG_ 528 RideHeightFunctionStatus_ISig_6 23;
BA_ "Platform_VMCU1_Sig" SG_ 528 RideHeightFunctionStatus_ISig_6 1;
BA_ "SeToolAncestorID_SIGNAL" SG_ 528 RideHeightFunctionStatus_ISig_6 "x0000001D042186C7";
BA_ "SeToolItemID_SIGNAL" SG_ 528 RideHeightFunctionStatus_ISig_6 "x0000001D043FB877";
BA_ "SeToolName_SIGNAL" SG_ 528 RideHeightFunctionStatus_ISig_6 "RideHeightFunctionStatus";
BA_ "SeToolVersion_SIGNAL" SG_ 528 RideHeightFunctionStatus_ISig_6 "2";
BA_ "GenSigCycleTime" SG_ 528 LevelControlInformation_ISig_6 100;
BA_ "GenSigCycleTimeActive" SG_ 528 LevelControlInformation_ISig_6 100;
BA_ "GenSigStartValue" SG_ 528 LevelControlInformation_ISig_6 15;
BA_ "GenSigMaxLatency" SG_ 528 LevelControlInformation_ISig_6 23;
BA_ "NeedsUpdateBit" SG_ 528 LevelControlInformation_ISig_6 1;
BA_ "Platform_VMCU1_Sig" SG_ 528 LevelControlInformation_ISig_6 1;
BA_ "SeToolAncestorID_SIGNAL" SG_ 528 LevelControlInformation_ISig_6 "x0000001D04290369";
BA_ "SeToolItemID_SIGNAL" SG_ 528 LevelControlInformation_ISig_6 "x0000001D04290369";
BA_ "SeToolName_SIGNAL" SG_ 528 LevelControlInformation_ISig_6 "LevelControlInformation";
BA_ "SeToolVersion_SIGNAL" SG_ 528 LevelControlInformation_ISig_6 "1";
BA_ "GenSigCycleTime" SG_ 528 KneelingStatusHMI_ISig_6 100;
BA_ "GenSigCycleTimeActive" SG_ 528 KneelingStatusHMI_ISig_6 100;
BA_ "GenSigStartValue" SG_ 528 KneelingStatusHMI_ISig_6 3;
BA_ "Platform_VMCU1_Sig" SG_ 528 KneelingStatusHMI_ISig_6 1;
BA_ "GenSigCycleTime" SG_ 528 DirInd_Rear_Status 100;
BA_ "GenSigCycleTimeActive" SG_ 528 DirInd_Rear_Status 100;
BA_ "GenSigStartValue" SG_ 528 DirInd_Rear_Status 7;
BA_ "GenSigMaxLatency" SG_ 528 DirInd_Rear_Status 23;
BA_ "Platform_VMCU1_Sig" SG_ 528 DirInd_Rear_Status 1;
BA_ "SeToolAncestorID_SIGNAL" SG_ 528 DirInd_Rear_Status "x0000001D041661D0";
BA_ "SeToolItemID_SIGNAL" SG_ 528 DirInd_Rear_Status "x0000001D042DB8F6";
BA_ "SeToolName_SIGNAL" SG_ 528 DirInd_Rear_Status "DirInd_Rear_Status";
BA_ "SeToolVersion_SIGNAL" SG_ 528 DirInd_Rear_Status "2";
BA_ "GenSigCycleTime" SG_ 528 VehicleDynamicSuspProhibitStat 100;
BA_ "GenSigCycleTimeActive" SG_ 528 VehicleDynamicSuspProhibitStat 100;
BA_ "GenSigStartValue" SG_ 528 VehicleDynamicSuspProhibitStat 3;
BA_ "Platform_VMCU1_Sig" SG_ 528 VehicleDynamicSuspProhibitStat 1;
BA_ "GenSigCycleTime" SG_ 528 ChangeKneelACK_ISig_6 100;
BA_ "GenSigCycleTimeActive" SG_ 528 ChangeKneelACK_ISig_6 100;
BA_ "GenSigStartValue" SG_ 528 ChangeKneelACK_ISig_6 3;
BA_ "Platform_VMCU1_Sig" SG_ 528 ChangeKneelACK_ISig_6 1;
BA_ "GenSigCycleTime" SG_ 528 ECSShutdownCmd 100;
BA_ "GenSigCycleTimeActive" SG_ 528 ECSShutdownCmd 100;
BA_ "GenSigStartValue" SG_ 528 ECSShutdownCmd 3;
BA_ "Platform_VMCU1_Sig" SG_ 528 ECSShutdownCmd 1;
BA_ "GenSigCycleTime" SG_ 528 LiftAxle2PositionStatus_ISig_6 100;
BA_ "GenSigCycleTimeActive" SG_ 528 LiftAxle2PositionStatus_ISig_6 100;
BA_ "GenSigStartValue" SG_ 528 LiftAxle2PositionStatus_ISig_6 7;
BA_ "GenSigMaxLatency" SG_ 528 LiftAxle2PositionStatus_ISig_6 23;
BA_ "Platform_VMCU1_Sig" SG_ 528 LiftAxle2PositionStatus_ISig_6 1;
BA_ "SeToolAncestorID_SIGNAL" SG_ 528 LiftAxle2PositionStatus_ISig_6 "x0000001D04131A0A";
BA_ "SeToolItemID_SIGNAL" SG_ 528 LiftAxle2PositionStatus_ISig_6 "x0000001D04295880";
BA_ "SeToolName_SIGNAL" SG_ 528 LiftAxle2PositionStatus_ISig_6 "LiftAxle2PositionStatus";
BA_ "SeToolVersion_SIGNAL" SG_ 528 LiftAxle2PositionStatus_ISig_6 "3";
BA_ "GenSigCycleTime" SG_ 517 BrakePressureSensorDemand_ISig_6 100;
BA_ "GenSigCycleTimeActive" SG_ 517 BrakePressureSensorDemand_ISig_6 100;
BA_ "GenSigStartValue" SG_ 517 BrakePressureSensorDemand_ISig_6 255;
BA_ "GenSigMaxLatency" SG_ 517 BrakePressureSensorDemand_ISig_6 23;
BA_ "NeedsUpdateBit" SG_ 517 BrakePressureSensorDemand_ISig_6 1;
BA_ "Platform_VMCU1_Sig" SG_ 517 BrakePressureSensorDemand_ISig_6 1;
BA_ "SeToolAncestorID_SIGNAL" SG_ 517 BrakePressureSensorDemand_ISig_6 "x0000001D0422D695";
BA_ "SeToolItemID_SIGNAL" SG_ 517 BrakePressureSensorDemand_ISig_6 "x0000001D042FD0DC";
BA_ "SeToolName_SIGNAL" SG_ 517 BrakePressureSensorDemand_ISig_6 "BrakePressureSensorDemand";
BA_ "SeToolVersion_SIGNAL" SG_ 517 BrakePressureSensorDemand_ISig_6 "2";
BA_ "GenSigCycleTime" SG_ 517 RampLevelStatus_ISig_6 100;
BA_ "GenSigCycleTimeActive" SG_ 517 RampLevelStatus_ISig_6 100;
BA_ "GenSigStartValue" SG_ 517 RampLevelStatus_ISig_6 15;
BA_ "GenSigMaxLatency" SG_ 517 RampLevelStatus_ISig_6 23;
BA_ "Platform_VMCU1_Sig" SG_ 517 RampLevelStatus_ISig_6 1;
BA_ "GenSigCycleTime" SG_ 517 LiftAxle2LowerACK_ISig_6 100;
BA_ "GenSigCycleTimeActive" SG_ 517 LiftAxle2LowerACK_ISig_6 100;
BA_ "GenSigStartValue" SG_ 517 LiftAxle2LowerACK_ISig_6 7;
BA_ "GenSigCycleTime" SG_ 517 LiftAxle2UpRequestACK_ISig_6 100;
BA_ "GenSigCycleTimeActive" SG_ 517 LiftAxle2UpRequestACK_ISig_6 100;
BA_ "GenSigStartValue" SG_ 517 LiftAxle2UpRequestACK_ISig_6 7;
BA_ "GenSigMaxLatency" SG_ 517 LiftAxle2UpRequestACK_ISig_6 23;
BA_ "Platform_VMCU1_Sig" SG_ 517 LiftAxle2UpRequestACK_ISig_6 1;
BA_ "SeToolAncestorID_SIGNAL" SG_ 517 LiftAxle2UpRequestACK_ISig_6 "x0000001D043E0E16";
BA_ "SeToolItemID_SIGNAL" SG_ 517 LiftAxle2UpRequestACK_ISig_6 "x0000001D043E0E16";
BA_ "SeToolName_SIGNAL" SG_ 517 LiftAxle2UpRequestACK_ISig_6 "LiftAxle2UpRequestACK";
BA_ "SeToolVersion_SIGNAL" SG_ 517 LiftAxle2UpRequestACK_ISig_6 "1";
BA_ "GenSigCycleTime" SG_ 517 FrontLimpHomeCmd 100;
BA_ "GenSigCycleTimeActive" SG_ 517 FrontLimpHomeCmd 100;
BA_ "GenSigStartValue" SG_ 517 FrontLimpHomeCmd 7;
BA_ "GenSigMaxLatency" SG_ 517 FrontLimpHomeCmd 23;
BA_ "Platform_VMCU1_Sig" SG_ 517 FrontLimpHomeCmd 1;
BA_ "SeToolAncestorID_SIGNAL" SG_ 517 FrontLimpHomeCmd "x0000001D0412F8A4";
BA_ "SeToolItemID_SIGNAL" SG_ 517 FrontLimpHomeCmd "x0000001D0412F8A4";
BA_ "SeToolName_SIGNAL" SG_ 517 FrontLimpHomeCmd "FrontLimphomeRequest";
BA_ "SeToolVersion_SIGNAL" SG_ 517 FrontLimpHomeCmd "1";
BA_ "GenSigCycleTime" SG_ 517 LiftAxle1LiftFuncSelected_ISig_6 100;
BA_ "GenSigCycleTimeActive" SG_ 517 LiftAxle1LiftFuncSelected_ISig_6 100;
BA_ "GenSigStartValue" SG_ 517 LiftAxle1LiftFuncSelected_ISig_6 7;
BA_ "SeToolAncestorID_SIGNAL" SG_ 517 LiftAxle1LiftFuncSelected_ISig_6 "x0000001D04134C43";
BA_ "SeToolItemID_SIGNAL" SG_ 517 LiftAxle1LiftFuncSelected_ISig_6 "x0000001D04134C43";
BA_ "SeToolName_SIGNAL" SG_ 517 LiftAxle1LiftFuncSelected_ISig_6 "LiftAxle1LiftAutoFunctionSelected";
BA_ "SeToolVersion_SIGNAL" SG_ 517 LiftAxle1LiftFuncSelected_ISig_6 "1";
BA_ "GenSigCycleTime" SG_ 517 RearAxleInBumperRange_ISig_6 100;
BA_ "GenSigCycleTimeActive" SG_ 517 RearAxleInBumperRange_ISig_6 100;
BA_ "GenSigStartValue" SG_ 517 RearAxleInBumperRange_ISig_6 3;
BA_ "GenSigMaxLatency" SG_ 517 RearAxleInBumperRange_ISig_6 23;
BA_ "NeedsUpdateBit" SG_ 517 RearAxleInBumperRange_ISig_6 1;
BA_ "Platform_VMCU1_Sig" SG_ 517 RearAxleInBumperRange_ISig_6 1;
BA_ "SeToolAncestorID_SIGNAL" SG_ 517 RearAxleInBumperRange_ISig_6 "x0000001D04149986";
BA_ "SeToolItemID_SIGNAL" SG_ 517 RearAxleInBumperRange_ISig_6 "x0000001D04149986";
BA_ "SeToolName_SIGNAL" SG_ 517 RearAxleInBumperRange_ISig_6 "RearAxleInBumperRange";
BA_ "SeToolVersion_SIGNAL" SG_ 517 RearAxleInBumperRange_ISig_6 "1";
BA_ "GenSigCycleTime" SG_ 517 LiftAxle1UpRequestACK_ISig_6 100;
BA_ "GenSigCycleTimeActive" SG_ 517 LiftAxle1UpRequestACK_ISig_6 100;
BA_ "GenSigStartValue" SG_ 517 LiftAxle1UpRequestACK_ISig_6 7;
BA_ "GenSigMaxLatency" SG_ 517 LiftAxle1UpRequestACK_ISig_6 23;
BA_ "Platform_VMCU1_Sig" SG_ 517 LiftAxle1UpRequestACK_ISig_6 1;
BA_ "SeToolAncestorID_SIGNAL" SG_ 517 LiftAxle1UpRequestACK_ISig_6 "x0000001D043E0DFD";
BA_ "SeToolItemID_SIGNAL" SG_ 517 LiftAxle1UpRequestACK_ISig_6 "x0000001D043E0DFD";
BA_ "SeToolName_SIGNAL" SG_ 517 LiftAxle1UpRequestACK_ISig_6 "LiftAxle1UpRequestACK";
BA_ "SeToolVersion_SIGNAL" SG_ 517 LiftAxle1UpRequestACK_ISig_6 "1";
BA_ "GenSigCycleTime" SG_ 517 FogLamp_Rear_Status 100;
BA_ "GenSigCycleTimeActive" SG_ 517 FogLamp_Rear_Status 100;
BA_ "GenSigStartValue" SG_ 517 FogLamp_Rear_Status 3;
BA_ "GenSigMaxLatency" SG_ 517 FogLamp_Rear_Status 23;
BA_ "Platform_VMCU1_Sig" SG_ 517 FogLamp_Rear_Status 1;
BA_ "SeToolAncestorID_SIGNAL" SG_ 517 FogLamp_Rear_Status "x0000001D04166FEF";
BA_ "SeToolItemID_SIGNAL" SG_ 517 FogLamp_Rear_Status "x0000001D042E380F";
BA_ "SeToolName_SIGNAL" SG_ 517 FogLamp_Rear_Status "FogLamp_Rear_Status";
BA_ "SeToolVersion_SIGNAL" SG_ 517 FogLamp_Rear_Status "4";
BA_ "GenSigCycleTime" SG_ 517 StopLevelChangeAck_ISig_6 100;
BA_ "GenSigCycleTimeActive" SG_ 517 StopLevelChangeAck_ISig_6 100;
BA_ "GenSigStartValue" SG_ 517 StopLevelChangeAck_ISig_6 3;
BA_ "GenSigMaxLatency" SG_ 517 StopLevelChangeAck_ISig_6 23;
BA_ "Platform_VMCU1_Sig" SG_ 517 StopLevelChangeAck_ISig_6 1;
BA_ "SeToolAncestorID_SIGNAL" SG_ 517 StopLevelChangeAck_ISig_6 "x0000001D0412ECBE";
BA_ "SeToolItemID_SIGNAL" SG_ 517 StopLevelChangeAck_ISig_6 "x0000001D0412ECBE";
BA_ "SeToolName_SIGNAL" SG_ 517 StopLevelChangeAck_ISig_6 "StopLevelChangeAck";
BA_ "SeToolVersion_SIGNAL" SG_ 517 StopLevelChangeAck_ISig_6 "1";
BA_ "GenSigCycleTime" SG_ 517 RampLevelStorageAck_ISig_6 100;
BA_ "GenSigCycleTimeActive" SG_ 517 RampLevelStorageAck_ISig_6 100;
BA_ "GenSigStartValue" SG_ 517 RampLevelStorageAck_ISig_6 3;
BA_ "GenSigMaxLatency" SG_ 517 RampLevelStorageAck_ISig_6 23;
BA_ "Platform_VMCU1_Sig" SG_ 517 RampLevelStorageAck_ISig_6 1;
BA_ "SeToolAncestorID_SIGNAL" SG_ 517 RampLevelStorageAck_ISig_6 "x0000001D0421FE10";
BA_ "SeToolItemID_SIGNAL" SG_ 517 RampLevelStorageAck_ISig_6 "x0000001D0421FE10";
BA_ "SeToolName_SIGNAL" SG_ 517 RampLevelStorageAck_ISig_6 "RampLevelStorageAck";
BA_ "SeToolVersion_SIGNAL" SG_ 517 RampLevelStorageAck_ISig_6 "1";
BA_ "GenSigCycleTime" SG_ 517 RideHeightOutsideTargetRange_ISi 100;
BA_ "GenSigCycleTimeActive" SG_ 517 RideHeightOutsideTargetRange_ISi 100;
BA_ "GenSigStartValue" SG_ 517 RideHeightOutsideTargetRange_ISi 7;
BA_ "GenSigMaxLatency" SG_ 517 RideHeightOutsideTargetRange_ISi 23;
BA_ "Platform_VMCU1_Sig" SG_ 517 RideHeightOutsideTargetRange_ISi 1;
BA_ "SeToolAncestorID_SIGNAL" SG_ 517 RideHeightOutsideTargetRange_ISi "x0000001D041F15D9";
BA_ "SeToolItemID_SIGNAL" SG_ 517 RideHeightOutsideTargetRange_ISi "x0000001D041F15D9";
BA_ "SeToolName_SIGNAL" SG_ 517 RideHeightOutsideTargetRange_ISi "RideHeightOutsideTargetRange";
BA_ "SeToolVersion_SIGNAL" SG_ 517 RideHeightOutsideTargetRange_ISi "1";
BA_ "SystemSignalLongSymbol" SG_ 517 RideHeightOutsideTargetRange_ISi "RideHeightOutsideTargetRange_ISig_6";
BA_ "GenSigCycleTime" SG_ 517 LiftingControlModeFrontAxle_ISig 100;
BA_ "GenSigCycleTimeActive" SG_ 517 LiftingControlModeFrontAxle_ISig 100;
BA_ "GenSigStartValue" SG_ 517 LiftingControlModeFrontAxle_ISig 3;
BA_ "GenSigMaxLatency" SG_ 517 LiftingControlModeFrontAxle_ISig 27;
BA_ "Platform_VMCU1_Sig" SG_ 517 LiftingControlModeFrontAxle_ISig 1;
BA_ "SeToolAncestorID_SIGNAL" SG_ 517 LiftingControlModeFrontAxle_ISig "x0000001D04149903";
BA_ "SeToolItemID_SIGNAL" SG_ 517 LiftingControlModeFrontAxle_ISig "x0000001D04149903";
BA_ "SeToolName_SIGNAL" SG_ 517 LiftingControlModeFrontAxle_ISig "LiftingControlModeFrontAxle";
BA_ "SeToolVersion_SIGNAL" SG_ 517 LiftingControlModeFrontAxle_ISig "1";
BA_ "SystemSignalLongSymbol" SG_ 517 LiftingControlModeFrontAxle_ISig "LiftingControlModeFrontAxle_ISig_6";
BA_ "GenSigCycleTime" SG_ 517 LoadDistributionChangeACK_ISig_6 100;
BA_ "GenSigCycleTimeActive" SG_ 517 LoadDistributionChangeACK_ISig_6 100;
BA_ "GenSigStartValue" SG_ 517 LoadDistributionChangeACK_ISig_6 7;
BA_ "GenSigMaxLatency" SG_ 517 LoadDistributionChangeACK_ISig_6 23;
BA_ "Platform_VMCU1_Sig" SG_ 517 LoadDistributionChangeACK_ISig_6 1;
BA_ "SeToolAncestorID_SIGNAL" SG_ 517 LoadDistributionChangeACK_ISig_6 "x0000001D04176D2D";
BA_ "SeToolItemID_SIGNAL" SG_ 517 LoadDistributionChangeACK_ISig_6 "x0000001D0440C942";
BA_ "SeToolName_SIGNAL" SG_ 517 LoadDistributionChangeACK_ISig_6 "LoadDistributionChangeAck";
BA_ "SeToolVersion_SIGNAL" SG_ 517 LoadDistributionChangeACK_ISig_6 "2";
BA_ "GenSigCycleTime" SG_ 517 RideHeightStorageAck_ISig_6 100;
BA_ "GenSigCycleTimeActive" SG_ 517 RideHeightStorageAck_ISig_6 100;
BA_ "GenSigStartValue" SG_ 517 RideHeightStorageAck_ISig_6 3;
BA_ "GenSigMaxLatency" SG_ 517 RideHeightStorageAck_ISig_6 23;
BA_ "Platform_VMCU1_Sig" SG_ 517 RideHeightStorageAck_ISig_6 1;
BA_ "SeToolAncestorID_SIGNAL" SG_ 517 RideHeightStorageAck_ISig_6 "x0000001D0421D044";
BA_ "SeToolItemID_SIGNAL" SG_ 517 RideHeightStorageAck_ISig_6 "x0000001D0421D044";
BA_ "SeToolName_SIGNAL" SG_ 517 RideHeightStorageAck_ISig_6 "RideHeightStorageAck";
BA_ "SeToolVersion_SIGNAL" SG_ 517 RideHeightStorageAck_ISig_6 "1";
BA_ "GenSigSendType" SG_ 517 RearAxleInBumperRange_UB_ISig_6 7;
BA_ "Platform_VMCU1_Sig" SG_ 517 RearAxleInBumperRange_UB_ISig_6 1;
BA_ "GenSigCycleTime" SG_ 517 ECSStandbyAllowed_ISig_6 100;
BA_ "GenSigCycleTimeActive" SG_ 517 ECSStandbyAllowed_ISig_6 100;
BA_ "GenSigStartValue" SG_ 517 ECSStandbyAllowed_ISig_6 3;
BA_ "Platform_VMCU1_Sig" SG_ 517 ECSStandbyAllowed_ISig_6 1;
BA_ "GenSigCycleTime" SG_ 517 LiftAxle2LiftFuncSelected_ISig_6 100;
BA_ "GenSigCycleTimeActive" SG_ 517 LiftAxle2LiftFuncSelected_ISig_6 100;
BA_ "GenSigStartValue" SG_ 517 LiftAxle2LiftFuncSelected_ISig_6 7;
BA_ "SeToolAncestorID_SIGNAL" SG_ 517 LiftAxle2LiftFuncSelected_ISig_6 "x0000001D04134C4B";
BA_ "SeToolItemID_SIGNAL" SG_ 517 LiftAxle2LiftFuncSelected_ISig_6 "x0000001D04134C4B";
BA_ "SeToolName_SIGNAL" SG_ 517 LiftAxle2LiftFuncSelected_ISig_6 "LiftAxle2LiftAutoFunctionSelected";
BA_ "SeToolVersion_SIGNAL" SG_ 517 LiftAxle2LiftFuncSelected_ISig_6 "1";
BA_ "GenSigCycleTime" SG_ 517 FrontProhibitControlRequest 100;
BA_ "GenSigCycleTimeActive" SG_ 517 FrontProhibitControlRequest 100;
BA_ "GenSigStartValue" SG_ 517 FrontProhibitControlRequest 3;
BA_ "GenSigMaxLatency" SG_ 517 FrontProhibitControlRequest 23;
BA_ "Platform_VMCU1_Sig" SG_ 517 FrontProhibitControlRequest 1;
BA_ "SeToolAncestorID_SIGNAL" SG_ 517 FrontProhibitControlRequest "x0000001D0413140A";
BA_ "SeToolItemID_SIGNAL" SG_ 517 FrontProhibitControlRequest "x0000001D0413140A";
BA_ "SeToolName_SIGNAL" SG_ 517 FrontProhibitControlRequest "FrontProhibitControlRequest";
BA_ "SeToolVersion_SIGNAL" SG_ 517 FrontProhibitControlRequest "1";
BA_ "GenSigCycleTime" SG_ 517 LiftingControlModeRearAxle_ISig_ 100;
BA_ "GenSigCycleTimeActive" SG_ 517 LiftingControlModeRearAxle_ISig_ 100;
BA_ "GenSigStartValue" SG_ 517 LiftingControlModeRearAxle_ISig_ 3;
BA_ "GenSigMaxLatency" SG_ 517 LiftingControlModeRearAxle_ISig_ 23;
BA_ "Platform_VMCU1_Sig" SG_ 517 LiftingControlModeRearAxle_ISig_ 1;
BA_ "SeToolAncestorID_SIGNAL" SG_ 517 LiftingControlModeRearAxle_ISig_ "x0000001D04149A4E";
BA_ "SeToolItemID_SIGNAL" SG_ 517 LiftingControlModeRearAxle_ISig_ "x0000001D04149A4E";
BA_ "SeToolName_SIGNAL" SG_ 517 LiftingControlModeRearAxle_ISig_ "LiftingControlModeRearAxle";
BA_ "SeToolVersion_SIGNAL" SG_ 517 LiftingControlModeRearAxle_ISig_ "1";
BA_ "SystemSignalLongSymbol" SG_ 517 LiftingControlModeRearAxle_ISig_ "LiftingControlModeRearAxle_ISig_6";
BA_ "GenSigCycleTime" SG_ 517 ProhibitControlStatus_ISig_6 100;
BA_ "GenSigCycleTimeActive" SG_ 517 ProhibitControlStatus_ISig_6 100;
BA_ "GenSigStartValue" SG_ 517 ProhibitControlStatus_ISig_6 3;
BA_ "GenSigMaxLatency" SG_ 517 ProhibitControlStatus_ISig_6 23;
BA_ "Platform_VMCU1_Sig" SG_ 517 ProhibitControlStatus_ISig_6 1;
BA_ "GenSigCycleTime" SG_ 517 DisableMechFaultDctnFr_rqst 100;
BA_ "GenSigCycleTimeActive" SG_ 517 DisableMechFaultDctnFr_rqst 100;
BA_ "GenSigStartValue" SG_ 517 DisableMechFaultDctnFr_rqst 3;
BA_ "GenSigMaxLatency" SG_ 517 DisableMechFaultDctnFr_rqst 23;
BA_ "Platform_VMCU1_Sig" SG_ 517 DisableMechFaultDctnFr_rqst 1;
BA_ "SeToolAncestorID_SIGNAL" SG_ 517 DisableMechFaultDctnFr_rqst "x0000001D04222579";
BA_ "SeToolItemID_SIGNAL" SG_ 517 DisableMechFaultDctnFr_rqst "x0000001D04222579";
BA_ "SeToolName_SIGNAL" SG_ 517 DisableMechFaultDctnFr_rqst "DisableMechanicalFaultDetectionFront";
BA_ "SeToolVersion_SIGNAL" SG_ 517 DisableMechFaultDctnFr_rqst "1";
BA_ "GenSigCycleTime" SG_ 517 FrontParkBrakeOverrideCommand 100;
BA_ "GenSigCycleTimeActive" SG_ 517 FrontParkBrakeOverrideCommand 100;
BA_ "GenSigStartValue" SG_ 517 FrontParkBrakeOverrideCommand 3;
BA_ "Platform_VMCU1_Sig" SG_ 517 FrontParkBrakeOverrideCommand 1;
BA_ "GenSigSendType" SG_ 517 BrakePressureSensorDemand_UB_ISi 7;
BA_ "Platform_VMCU1_Sig" SG_ 517 BrakePressureSensorDemand_UB_ISi 1;
BA_ "SystemSignalLongSymbol" SG_ 517 BrakePressureSensorDemand_UB_ISi "BrakePressureSensorDemand_UB_ISig_6";
BA_ "GenSigSendType" SG_ 2671833714 PhysDiagRespSig_F2_72_ISig_6 7;
BA_ "GenSigSendType" SG_ 2671833713 PhysDiagRespSig_F2_71_ISig_6 7;
BA_ "GenSigSendType" SG_ 2671833649 PhysDiagRespSig_F2_31_ISig_6 7;
BA_ "Platform_VMCU1_Sig" SG_ 2671833649 PhysDiagRespSig_F2_31_ISig_6 1;
BA_ "GenSigSendType" SG_ 2671833648 PhysDiagRespSig_F2_30_ISig_6 7;
BA_ "Platform_VMCU1_Sig" SG_ 2671833648 PhysDiagRespSig_F2_30_ISig_6 1;
BA_ "GenSigSendType" SG_ 2671833637 PhysDiagRespSig_F2_25_ISig_6 7;
BA_ "Platform_VMCU1_Sig" SG_ 2671833637 PhysDiagRespSig_F2_25_ISig_6 1;
BA_ "GenSigSendType" SG_ 2671833635 PhysDiagRespSig_F2_23_ISig_6 7;
BA_ "Platform_VMCU1_Sig" SG_ 2671833635 PhysDiagRespSig_F2_23_ISig_6 1;
BA_ "GenSigSendType" SG_ 2671833634 PhysDiagRespSig_F2_22_ISig_6 7;
BA_ "Platform_VMCU1_Sig" SG_ 2671833634 PhysDiagRespSig_F2_22_ISig_6 1;
BA_ "GenSigSendType" SG_ 2671833633 PhysDiagRespSig_F2_21_ISig_6 7;
BA_ "Platform_VMCU1_Sig" SG_ 2671833633 PhysDiagRespSig_F2_21_ISig_6 1;
BA_ "GenSigSendType" SG_ 2671833632 PhysDiagRespSig_F2_20_ISig_6 7;
BA_ "Platform_VMCU1_Sig" SG_ 2671833632 PhysDiagRespSig_F2_20_ISig_6 1;
BA_ "GenSigSendType" SG_ 2671833626 PhysDiagRespSig_F2_1A_ISig_6 7;
BA_ "GenSigSendType" SG_ 2671801074 PhysDiagReqSig_72_F2_ISig_6 7;
BA_ "GenSigSendType" SG_ 2671800818 PhysDiagReqSig_71_F2_ISig_6 7;
BA_ "GenSigSendType" SG_ 2671784434 PhysDiagReqSig_31_F2_ISig_6 7;
BA_ "Platform_VMCU1_Sig" SG_ 2671784434 PhysDiagReqSig_31_F2_ISig_6 1;
BA_ "GenSigSendType" SG_ 2671784178 PhysDiagReqSig_30_F2_ISig_6 7;
BA_ "Platform_VMCU1_Sig" SG_ 2671784178 PhysDiagReqSig_30_F2_ISig_6 1;
BA_ "GenSigSendType" SG_ 2671781362 PhysDiagReqSig_25_F2_ISig_6 7;
BA_ "Platform_VMCU1_Sig" SG_ 2671781362 PhysDiagReqSig_25_F2_ISig_6 1;
BA_ "GenSigSendType" SG_ 2671780850 PhysDiagReqSig_23_F2_ISig_6 7;
BA_ "Platform_VMCU1_Sig" SG_ 2671780850 PhysDiagReqSig_23_F2_ISig_6 1;
BA_ "GenSigSendType" SG_ 2671780594 PhysDiagReqSig_22_F2_ISig_6 7;
BA_ "Platform_VMCU1_Sig" SG_ 2671780594 PhysDiagReqSig_22_F2_ISig_6 1;
BA_ "GenSigSendType" SG_ 2671780338 PhysDiagReqSig_21_F2_ISig_6 7;
BA_ "Platform_VMCU1_Sig" SG_ 2671780338 PhysDiagReqSig_21_F2_ISig_6 1;
BA_ "GenSigSendType" SG_ 2671780082 PhysDiagReqSig_20_F2_ISig_6 7;
BA_ "Platform_VMCU1_Sig" SG_ 2671780082 PhysDiagReqSig_20_F2_ISig_6 1;
BA_ "GenSigSendType" SG_ 2671778546 PhysDiagReqSig_1A_F2_ISig_6 7;
BA_ "GenSigSendType" SG_ 2671902708 FuncDiagDataIntTesterTGW2_ISig_6 7;
BA_ "Platform_VMCU1_Sig" SG_ 2671902708 FuncDiagDataIntTesterTGW2_ISig_6 1;
BA_ "GenSigCycleTime" SG_ 1339 FrontConspicLamp_stat_LoLeft_ISi 100;
BA_ "GenSigCycleTimeActive" SG_ 1339 FrontConspicLamp_stat_LoLeft_ISi 100;
BA_ "GenSigStartValue" SG_ 1339 FrontConspicLamp_stat_LoLeft_ISi 7;
BA_ "GenSigMaxLatency" SG_ 1339 FrontConspicLamp_stat_LoLeft_ISi 250;
BA_ "SystemSignalLongSymbol" SG_ 1339 FrontConspicLamp_stat_LoLeft_ISi "FrontConspicLamp_stat_LoLeft_ISig_6";
BA_ "GenSigCycleTime" SG_ 1339 HeadlampFan_stat_ISig_6 100;
BA_ "GenSigCycleTimeActive" SG_ 1339 HeadlampFan_stat_ISig_6 100;
BA_ "GenSigStartValue" SG_ 1339 HeadlampFan_stat_ISig_6 7;
BA_ "GenSigCycleTime" SG_ 1339 FrontConspicLamp_stat_HiLeft_ISi 100;
BA_ "GenSigCycleTimeActive" SG_ 1339 FrontConspicLamp_stat_HiLeft_ISi 100;
BA_ "GenSigStartValue" SG_ 1339 FrontConspicLamp_stat_HiLeft_ISi 7;
BA_ "GenSigMaxLatency" SG_ 1339 FrontConspicLamp_stat_HiLeft_ISi 250;
BA_ "SystemSignalLongSymbol" SG_ 1339 FrontConspicLamp_stat_HiLeft_ISi "FrontConspicLamp_stat_HiLeft_ISig_6";
BA_ "GenSigCycleTime" SG_ 1339 FrontConspicLamp_stat_LoRight_IS 100;
BA_ "GenSigCycleTimeActive" SG_ 1339 FrontConspicLamp_stat_LoRight_IS 100;
BA_ "GenSigStartValue" SG_ 1339 FrontConspicLamp_stat_LoRight_IS 7;
BA_ "GenSigMaxLatency" SG_ 1339 FrontConspicLamp_stat_LoRight_IS 250;
BA_ "SystemSignalLongSymbol" SG_ 1339 FrontConspicLamp_stat_LoRight_IS "FrontConspicLamp_stat_LoRight_ISig_6";
BA_ "GenSigCycleTime" SG_ 1339 AmbientAirTemperature2 100;
BA_ "GenSigCycleTimeActive" SG_ 1339 AmbientAirTemperature2 100;
BA_ "GenSigStartValue" SG_ 1339 AmbientAirTemperature2 65535;
BA_ "GenSigCycleTime" SG_ 1339 FrontConspicLamp_stat_HiRight_IS 100;
BA_ "GenSigCycleTimeActive" SG_ 1339 FrontConspicLamp_stat_HiRight_IS 100;
BA_ "GenSigStartValue" SG_ 1339 FrontConspicLamp_stat_HiRight_IS 7;
BA_ "GenSigMaxLatency" SG_ 1339 FrontConspicLamp_stat_HiRight_IS 250;
BA_ "SystemSignalLongSymbol" SG_ 1339 FrontConspicLamp_stat_HiRight_IS "FrontConspicLamp_stat_HiRight_ISig_6";
BA_ "GenSigCycleTime" SG_ 1243 MainBeamLEDStatusLeft_ISig_6 100;
BA_ "GenSigCycleTimeActive" SG_ 1243 MainBeamLEDStatusLeft_ISig_6 100;
BA_ "GenSigStartValue" SG_ 1243 MainBeamLEDStatusLeft_ISig_6 7;
BA_ "Platform_VMCU1_Sig" SG_ 1243 MainBeamLEDStatusLeft_ISig_6 1;
BA_ "GenSigCycleTime" SG_ 1243 MainBeamLEDStatusRight_ISig_6 100;
BA_ "GenSigCycleTimeActive" SG_ 1243 MainBeamLEDStatusRight_ISig_6 100;
BA_ "GenSigStartValue" SG_ 1243 MainBeamLEDStatusRight_ISig_6 7;
BA_ "Platform_VMCU1_Sig" SG_ 1243 MainBeamLEDStatusRight_ISig_6 1;
BA_REL_ "GenSigFirstTimeoutTime" BU_SG_REL_ VMCU SG_ 1522 Trailer1TPMThresCfg_OverPres_ISi 24000;
BA_REL_ "GenSigTimeoutTime" BU_SG_REL_ VMCU SG_ 1522 Trailer1TPMThresCfg_OverPres_ISi 6000;
BA_REL_ "GenSigFirstTimeoutTime" BU_SG_REL_ VMCU SG_ 1522 Trailer1TPMThresCfg_AxleNr_ISig_ 24000;
BA_REL_ "GenSigTimeoutTime" BU_SG_REL_ VMCU SG_ 1522 Trailer1TPMThresCfg_AxleNr_ISig_ 6000;
BA_REL_ "GenSigFirstTimeoutTime" BU_SG_REL_ VMCU SG_ 1522 Trailer1TPMThresCfg_ExtOverPres_ 24000;
BA_REL_ "GenSigTimeoutTime" BU_SG_REL_ VMCU SG_ 1522 Trailer1TPMThresCfg_ExtOverPres_ 6000;
BA_REL_ "GenSigFirstTimeoutTime" BU_SG_REL_ VMCU SG_ 1522 Trailer1TPMAxlTireCfg_Axle5_ISig 24000;
BA_REL_ "GenSigTimeoutTime" BU_SG_REL_ VMCU SG_ 1522 Trailer1TPMAxlTireCfg_Axle5_ISig 6000;
BA_REL_ "GenSigFirstTimeoutTime" BU_SG_REL_ VMCU SG_ 1522 Trailer1TPMAxlTireCfg_Axle1_ISig 24000;
BA_REL_ "GenSigTimeoutTime" BU_SG_REL_ VMCU SG_ 1522 Trailer1TPMAxlTireCfg_Axle1_ISig 6000;
BA_REL_ "GenSigFirstTimeoutTime" BU_SG_REL_ VMCU SG_ 1522 Trailer1TPMAxlTireCfg_Axle2_ISig 24000;
BA_REL_ "GenSigTimeoutTime" BU_SG_REL_ VMCU SG_ 1522 Trailer1TPMAxlTireCfg_Axle2_ISig 6000;
BA_REL_ "GenSigFirstTimeoutTime" BU_SG_REL_ VMCU SG_ 1522 Trailer1TPMThresCfg_ExtUnderPres 24000;
BA_REL_ "GenSigTimeoutTime" BU_SG_REL_ VMCU SG_ 1522 Trailer1TPMThresCfg_ExtUnderPres 6000;
BA_REL_ "GenSigFirstTimeoutTime" BU_SG_REL_ VMCU SG_ 1522 Trailer1TPMThresCfg_UnderPres_IS 24000;
BA_REL_ "GenSigTimeoutTime" BU_SG_REL_ VMCU SG_ 1522 Trailer1TPMThresCfg_UnderPres_IS 6000;
BA_REL_ "GenSigFirstTimeoutTime" BU_SG_REL_ VMCU SG_ 1522 Trailer1TPMType_ISig_6 24000;
BA_REL_ "GenSigTimeoutTime" BU_SG_REL_ VMCU SG_ 1522 Trailer1TPMType_ISig_6 6000;
BA_REL_ "GenSigFirstTimeoutTime" BU_SG_REL_ VMCU SG_ 1522 Trailer1TPMAxlTireCfg_Axle3_ISig 24000;
BA_REL_ "GenSigTimeoutTime" BU_SG_REL_ VMCU SG_ 1522 Trailer1TPMAxlTireCfg_Axle3_ISig 6000;
BA_REL_ "GenSigFirstTimeoutTime" BU_SG_REL_ VMCU SG_ 1522 Trailer1TPMAxlTireCfg_Axle4_ISig 24000;
BA_REL_ "GenSigTimeoutTime" BU_SG_REL_ VMCU SG_ 1522 Trailer1TPMAxlTireCfg_Axle4_ISig 6000;
BA_REL_ "GenSigFirstTimeoutTime" BU_SG_REL_ VMCU SG_ 1349 RearAxleGroupLoad_ISig_6 6000;
BA_REL_ "GenSigTimeoutTime" BU_SG_REL_ VMCU SG_ 1349 RearAxleGroupLoad_ISig_6 1500;
BA_REL_ "GenSigFirstTimeoutTime" BU_SG_REL_ EBS SG_ 951 Trailer2LiftAxle2PosReq 1200;
BA_REL_ "GenSigTimeoutTime" BU_SG_REL_ EBS SG_ 951 Trailer2LiftAxle2PosReq 300;
BA_REL_ "GenSigFirstTimeoutTime" BU_SG_REL_ EBS SG_ 951 Trailer3LiftAxle2PosReq 1200;
BA_REL_ "GenSigTimeoutTime" BU_SG_REL_ EBS SG_ 951 Trailer3LiftAxle2PosReq 300;
BA_REL_ "GenSigFirstTimeoutTime" BU_SG_REL_ EBS SG_ 951 Trailer1LiftAxle1PosReq 1200;
BA_REL_ "GenSigTimeoutTime" BU_SG_REL_ EBS SG_ 951 Trailer1LiftAxle1PosReq 300;
BA_REL_ "GenSigFirstTimeoutTime" BU_SG_REL_ VMCU SG_ 951 HeadlightLevelAuto_rqst 3000;
BA_REL_ "GenSigTimeoutTime" BU_SG_REL_ VMCU SG_ 951 HeadlightLevelAuto_rqst 300;
BA_REL_ "GenSigFirstTimeoutTime" BU_SG_REL_ EBS SG_ 951 Trailer2LiftAxle1PosReq 1200;
BA_REL_ "GenSigTimeoutTime" BU_SG_REL_ EBS SG_ 951 Trailer2LiftAxle1PosReq 300;
BA_REL_ "GenSigFirstTimeoutTime" BU_SG_REL_ EBS SG_ 951 Trailer3LiftAxle1PosReq 1200;
BA_REL_ "GenSigTimeoutTime" BU_SG_REL_ EBS SG_ 951 Trailer3LiftAxle1PosReq 300;
BA_REL_ "GenSigFirstTimeoutTime" BU_SG_REL_ VMCU SG_ 951 HeadlightAngleAuto_rqst 3000;
BA_REL_ "GenSigTimeoutTime" BU_SG_REL_ VMCU SG_ 951 HeadlightAngleAuto_rqst 300;
BA_REL_ "GenSigFirstTimeoutTime" BU_SG_REL_ EBS SG_ 951 Trailer1LiftAxle2PosReq 1200;
BA_REL_ "GenSigTimeoutTime" BU_SG_REL_ EBS SG_ 951 Trailer1LiftAxle2PosReq 300;
BA_REL_ "GenSigFirstTimeoutTime" BU_SG_REL_ VMCU SG_ 1344 RegenInhibitVehicleHeight_ISig_6 6000;
BA_REL_ "GenSigTimeoutTime" BU_SG_REL_ VMCU SG_ 1344 RegenInhibitVehicleHeight_ISig_6 1500;
BA_REL_ "GenSigFirstTimeoutTime" BU_SG_REL_ EAS SG_ 1344 PusherAxleLoad_ISig_6 6000;
BA_REL_ "GenSigTimeoutTime" BU_SG_REL_ EAS SG_ 1344 PusherAxleLoad_ISig_6 1500;
BA_REL_ "GenSigFirstTimeoutTime" BU_SG_REL_ VMCU SG_ 1344 PusherAxleLoad_ISig_6 6000;
BA_REL_ "GenSigTimeoutTime" BU_SG_REL_ VMCU SG_ 1344 PusherAxleLoad_ISig_6 1500;
BA_REL_ "GenSigFirstTimeoutTime" BU_SG_REL_ FAS SG_ 1344 PusherAxleLoad_ISig_6 6000;
BA_REL_ "GenSigTimeoutTime" BU_SG_REL_ FAS SG_ 1344 PusherAxleLoad_ISig_6 1500;
BA_REL_ "GenSigFirstTimeoutTime" BU_SG_REL_ APM SG_ 1344 PusherAxleLoad_ISig_6 5000;
BA_REL_ "GenSigTimeoutTime" BU_SG_REL_ APM SG_ 1344 PusherAxleLoad_ISig_6 1500;
BA_REL_ "GenSigFirstTimeoutTime" BU_SG_REL_ EBS SG_ 1344 PusherAxleLoad_ISig_6 6000;
BA_REL_ "GenSigTimeoutTime" BU_SG_REL_ EBS SG_ 1344 PusherAxleLoad_ISig_6 1500;
BA_REL_ "GenSigFirstTimeoutTime" BU_SG_REL_ VMCU SG_ 1344 TagAxleLoad_ISig_6 6000;
BA_REL_ "GenSigTimeoutTime" BU_SG_REL_ VMCU SG_ 1344 TagAxleLoad_ISig_6 1500;
BA_REL_ "GenSigFirstTimeoutTime" BU_SG_REL_ EBS SG_ 1344 TagAxleLoad_ISig_6 6000;
BA_REL_ "GenSigTimeoutTime" BU_SG_REL_ EBS SG_ 1344 TagAxleLoad_ISig_6 1500;
BA_REL_ "GenSigFirstTimeoutTime" BU_SG_REL_ APM SG_ 1344 TagAxleLoad_ISig_6 3000;
BA_REL_ "GenSigTimeoutTime" BU_SG_REL_ APM SG_ 1344 TagAxleLoad_ISig_6 1500;
BA_REL_ "GenSigFirstTimeoutTime" BU_SG_REL_ EAS SG_ 1344 TagAxleLoad_ISig_6 6000;
BA_REL_ "GenSigTimeoutTime" BU_SG_REL_ EAS SG_ 1344 TagAxleLoad_ISig_6 1500;
BA_REL_ "GenSigFirstTimeoutTime" BU_SG_REL_ FAS SG_ 1344 TagAxleLoad_ISig_6 3000;
BA_REL_ "GenSigTimeoutTime" BU_SG_REL_ FAS SG_ 1344 TagAxleLoad_ISig_6 1500;
BA_REL_ "GenSigFirstTimeoutTime" BU_SG_REL_ VMCU SG_ 1344 RearLeftRoadVibrationIndex 6000;
BA_REL_ "GenSigTimeoutTime" BU_SG_REL_ VMCU SG_ 1344 RearLeftRoadVibrationIndex 1500;
BA_REL_ "GenSigFirstTimeoutTime" BU_SG_REL_ VMCU SG_ 1343 TrailerPosLightRightOutputStat_I 6000;
BA_REL_ "GenSigTimeoutTime" BU_SG_REL_ VMCU SG_ 1343 TrailerPosLightRightOutputStat_I 1500;
BA_REL_ "GenSigFirstTimeoutTime" BU_SG_REL_ VMCU SG_ 1343 TrailerBrakeLightOutputStat_ISig 6000;
BA_REL_ "GenSigTimeoutTime" BU_SG_REL_ VMCU SG_ 1343 TrailerBrakeLightOutputStat_ISig 1500;
BA_REL_ "GenSigFirstTimeoutTime" BU_SG_REL_ VMCU SG_ 1343 TrailerDirIndRightOutputStat_ISi 6000;
BA_REL_ "GenSigTimeoutTime" BU_SG_REL_ VMCU SG_ 1343 TrailerDirIndRightOutputStat_ISi 1500;
BA_REL_ "GenSigFirstTimeoutTime" BU_SG_REL_ VMCU SG_ 1343 ExtECSPressureUpdateAck 6000;
BA_REL_ "GenSigTimeoutTime" BU_SG_REL_ VMCU SG_ 1343 ExtECSPressureUpdateAck 1500;
BA_REL_ "GenSigFirstTimeoutTime" BU_SG_REL_ VMCU SG_ 1343 DriveAxleLoad_ISig_6 6000;
BA_REL_ "GenSigTimeoutTime" BU_SG_REL_ VMCU SG_ 1343 DriveAxleLoad_ISig_6 1500;
BA_REL_ "GenSigFirstTimeoutTime" BU_SG_REL_ FAS SG_ 1343 DriveAxleLoad_ISig_6 6000;
BA_REL_ "GenSigTimeoutTime" BU_SG_REL_ FAS SG_ 1343 DriveAxleLoad_ISig_6 1500;
BA_REL_ "GenSigFirstTimeoutTime" BU_SG_REL_ EBS SG_ 1343 DriveAxleLoad_ISig_6 6000;
BA_REL_ "GenSigTimeoutTime" BU_SG_REL_ EBS SG_ 1343 DriveAxleLoad_ISig_6 1500;
BA_REL_ "GenSigFirstTimeoutTime" BU_SG_REL_ APM SG_ 1343 DriveAxleLoad_ISig_6 6000;
BA_REL_ "GenSigTimeoutTime" BU_SG_REL_ APM SG_ 1343 DriveAxleLoad_ISig_6 1500;
BA_REL_ "GenSigFirstTimeoutTime" BU_SG_REL_ VMCU SG_ 1343 TrailerPosLightLeftOutputStat_IS 6000;
BA_REL_ "GenSigTimeoutTime" BU_SG_REL_ VMCU SG_ 1343 TrailerPosLightLeftOutputStat_IS 1500;
BA_REL_ "GenSigFirstTimeoutTime" BU_SG_REL_ VMCU SG_ 1343 TrailerDirIndLeftOutputStat_ISig 6000;
BA_REL_ "GenSigTimeoutTime" BU_SG_REL_ VMCU SG_ 1343 TrailerDirIndLeftOutputStat_ISig 1500;
BA_REL_ "GenSigFirstTimeoutTime" BU_SG_REL_ VMCU SG_ 1343 LoadDistributionSelected2_ISig_6 6000;
BA_REL_ "GenSigTimeoutTime" BU_SG_REL_ VMCU SG_ 1343 LoadDistributionSelected2_ISig_6 1500;
BA_REL_ "GenSigFirstTimeoutTime" BU_SG_REL_ VMCU SG_ 1343 SecondaryDriveAxleLoad_ISig_6 6000;
BA_REL_ "GenSigTimeoutTime" BU_SG_REL_ VMCU SG_ 1343 SecondaryDriveAxleLoad_ISig_6 1500;
BA_REL_ "GenSigFirstTimeoutTime" BU_SG_REL_ FAS SG_ 1343 SecondaryDriveAxleLoad_ISig_6 6000;
BA_REL_ "GenSigTimeoutTime" BU_SG_REL_ FAS SG_ 1343 SecondaryDriveAxleLoad_ISig_6 1500;
BA_REL_ "GenSigFirstTimeoutTime" BU_SG_REL_ APM SG_ 1343 SecondaryDriveAxleLoad_ISig_6 6000;
BA_REL_ "GenSigTimeoutTime" BU_SG_REL_ APM SG_ 1343 SecondaryDriveAxleLoad_ISig_6 1500;
BA_REL_ "GenSigFirstTimeoutTime" BU_SG_REL_ EBS SG_ 1343 SecondaryDriveAxleLoad_ISig_6 6000;
BA_REL_ "GenSigTimeoutTime" BU_SG_REL_ EBS SG_ 1343 SecondaryDriveAxleLoad_ISig_6 1500;
BA_REL_ "GenSigFirstTimeoutTime" BU_SG_REL_ CCIOM SG_ 825 RevLight_cmd 3000;
BA_REL_ "GenSigTimeoutTime" BU_SG_REL_ CCIOM SG_ 825 RevLight_cmd 180;
BA_REL_ "GenSigFirstTimeoutTime" BU_SG_REL_ VMCU SG_ 825 RevLight_cmd 3000;
BA_REL_ "GenSigTimeoutTime" BU_SG_REL_ VMCU SG_ 825 RevLight_cmd 180;
BA_REL_ "GenSigFirstTimeoutTime" BU_SG_REL_ VMCU SG_ 825 LoadDistributionALDChangeACK_ISi 3000;
BA_REL_ "GenSigTimeoutTime" BU_SG_REL_ VMCU SG_ 825 LoadDistributionALDChangeACK_ISi 180;
BA_REL_ "GenSigFirstTimeoutTime" BU_SG_REL_ VMCU SG_ 825 LiftAxle2AutoLiftSelected_ISig_6 3000;
BA_REL_ "GenSigTimeoutTime" BU_SG_REL_ VMCU SG_ 825 LiftAxle2AutoLiftSelected_ISig_6 180;
BA_REL_ "GenSigFirstTimeoutTime" BU_SG_REL_ VMCU SG_ 825 DriveLevelPosUserInteraction_ISi 3000;
BA_REL_ "GenSigTimeoutTime" BU_SG_REL_ VMCU SG_ 825 DriveLevelPosUserInteraction_ISi 180;
BA_REL_ "GenSigFirstTimeoutTime" BU_SG_REL_ VMCU SG_ 825 FirstAxleLowerPrioSelected_ISig_ 3000;
BA_REL_ "GenSigTimeoutTime" BU_SG_REL_ VMCU SG_ 825 FirstAxleLowerPrioSelected_ISig_ 180;
BA_REL_ "GenSigFirstTimeoutTime" BU_SG_REL_ VMCU SG_ 825 FerryFunctionSwitchChangeACK_ISi 3000;
BA_REL_ "GenSigTimeoutTime" BU_SG_REL_ VMCU SG_ 825 FerryFunctionSwitchChangeACK_ISi 180;
BA_REL_ "GenSigFirstTimeoutTime" BU_SG_REL_ VMCU SG_ 825 TrailerDirInd_status 3000;
BA_REL_ "GenSigTimeoutTime" BU_SG_REL_ VMCU SG_ 825 TrailerDirInd_status 180;
BA_REL_ "GenSigFirstTimeoutTime" BU_SG_REL_ VMCU SG_ 825 RevLightLamp_stat_ISig_6 3000;
BA_REL_ "GenSigTimeoutTime" BU_SG_REL_ VMCU SG_ 825 RevLightLamp_stat_ISig_6 180;
BA_REL_ "GenSigFirstTimeoutTime" BU_SG_REL_ VMCU SG_ 825 UnevenLoadWarning_ISig_6 3000;
BA_REL_ "GenSigTimeoutTime" BU_SG_REL_ VMCU SG_ 825 UnevenLoadWarning_ISig_6 180;
BA_REL_ "GenSigFirstTimeoutTime" BU_SG_REL_ VMCU SG_ 825 LoadDistributionSelected_ISig_6 3000;
BA_REL_ "GenSigTimeoutTime" BU_SG_REL_ VMCU SG_ 825 LoadDistributionSelected_ISig_6 180;
BA_REL_ "GenSigFirstTimeoutTime" BU_SG_REL_ VMCU SG_ 825 PositionLightRearLamp_stat_ISig_ 3000;
BA_REL_ "GenSigTimeoutTime" BU_SG_REL_ VMCU SG_ 825 PositionLightRearLamp_stat_ISig_ 180;
BA_REL_ "GenSigFirstTimeoutTime" BU_SG_REL_ VMCU SG_ 825 LiftAxle1AutoLiftSelected_ISig_6 3000;
BA_REL_ "GenSigTimeoutTime" BU_SG_REL_ VMCU SG_ 825 LiftAxle1AutoLiftSelected_ISig_6 180;
BA_REL_ "GenSigFirstTimeoutTime" BU_SG_REL_ VMCU SG_ 825 StartupProhibitStatus_ISig_6 3000;
BA_REL_ "GenSigTimeoutTime" BU_SG_REL_ VMCU SG_ 825 StartupProhibitStatus_ISig_6 180;
BA_REL_ "GenSigFirstTimeoutTime" BU_SG_REL_ VMCU SG_ 825 LiftAxle1LowerACK_ISig_6 3000;
BA_REL_ "GenSigTimeoutTime" BU_SG_REL_ VMCU SG_ 825 LiftAxle1LowerACK_ISig_6 180;
BA_REL_ "GenSigFirstTimeoutTime" BU_SG_REL_ VMCU SG_ 825 RampLevelRequestACK_ISig_6 3000;
BA_REL_ "GenSigTimeoutTime" BU_SG_REL_ VMCU SG_ 825 RampLevelRequestACK_ISig_6 180;
BA_REL_ "GenSigFirstTimeoutTime" BU_SG_REL_ VMCU SG_ 825 BrakeLightLamp_stat_ISig_6 3000;
BA_REL_ "GenSigTimeoutTime" BU_SG_REL_ VMCU SG_ 825 BrakeLightLamp_stat_ISig_6 180;
BA_REL_ "GenSigFirstTimeoutTime" BU_SG_REL_ EBS SG_ 825 TrailerABSStatus_ISig_6 3000;
BA_REL_ "GenSigTimeoutTime" BU_SG_REL_ EBS SG_ 825 TrailerABSStatus_ISig_6 180;
BA_REL_ "GenSigFirstTimeoutTime" BU_SG_REL_ APM SG_ 825 TrailerABSStatus_ISig_6 3000;
BA_REL_ "GenSigTimeoutTime" BU_SG_REL_ APM SG_ 825 TrailerABSStatus_ISig_6 180;
BA_REL_ "GenSigFirstTimeoutTime" BU_SG_REL_ VMCU SG_ 825 TrailerABSStatus_ISig_6 3000;
BA_REL_ "GenSigTimeoutTime" BU_SG_REL_ VMCU SG_ 825 TrailerABSStatus_ISig_6 180;
BA_REL_ "GenSigFirstTimeoutTime" BU_SG_REL_ VMCU SG_ 825 FogLightRearLamp_stat_ISig_6 3000;
BA_REL_ "GenSigTimeoutTime" BU_SG_REL_ VMCU SG_ 825 FogLightRearLamp_stat_ISig_6 180;
BA_REL_ "GenSigFirstTimeoutTime" BU_SG_REL_ VMCU SG_ 825 ECSLimpHomeNotification_ISig_6 3000;
BA_REL_ "GenSigTimeoutTime" BU_SG_REL_ VMCU SG_ 825 ECSLimpHomeNotification_ISig_6 180;
BA_REL_ "GenSigFirstTimeoutTime" BU_SG_REL_ VMCU SG_ 825 BrakeLight_rqst_ISig_6 3000;
BA_REL_ "GenSigTimeoutTime" BU_SG_REL_ VMCU SG_ 825 BrakeLight_rqst_ISig_6 500;
BA_REL_ "GenSigFirstTimeoutTime" BU_SG_REL_ CCIOM SG_ 825 ECSValveActivationAllowed 3000;
BA_REL_ "GenSigTimeoutTime" BU_SG_REL_ CCIOM SG_ 825 ECSValveActivationAllowed 180;
BA_REL_ "GenSigFirstTimeoutTime" BU_SG_REL_ VMCU SG_ 825 BrakeLightConvoy_rqst_ISig_6 3000;
BA_REL_ "GenSigTimeoutTime" BU_SG_REL_ VMCU SG_ 825 BrakeLightConvoy_rqst_ISig_6 500;
BA_REL_ "GenSigFirstTimeoutTime" BU_SG_REL_ VMCU SG_ 825 FrontParkBrakeOverrideInd_ISig_6 3000;
BA_REL_ "GenSigTimeoutTime" BU_SG_REL_ VMCU SG_ 825 FrontParkBrakeOverrideInd_ISig_6 180;
BA_REL_ "GenSigFirstTimeoutTime" BU_SG_REL_ VMCU SG_ 948 FrontAxleInBumperRange_ISig_6 3000;
BA_REL_ "GenSigTimeoutTime" BU_SG_REL_ VMCU SG_ 948 FrontAxleInBumperRange_ISig_6 500;
BA_REL_ "GenSigFirstTimeoutTime" BU_SG_REL_ VMCU SG_ 948 Rear1ClutchStatus 3000;
BA_REL_ "GenSigTimeoutTime" BU_SG_REL_ VMCU SG_ 948 Rear1ClutchStatus 500;
BA_REL_ "GenSigFirstTimeoutTime" BU_SG_REL_ CCIOM SG_ 948 FrontRollAngleRef 3000;
BA_REL_ "GenSigTimeoutTime" BU_SG_REL_ CCIOM SG_ 948 FrontRollAngleRef 300;
BA_REL_ "GenSigFirstTimeoutTime" BU_SG_REL_ CCIOM SG_ 948 FrontSideKneelingAngleRef 3000;
BA_REL_ "GenSigTimeoutTime" BU_SG_REL_ CCIOM SG_ 948 FrontSideKneelingAngleRef 300;
BA_REL_ "GenSigFirstTimeoutTime" BU_SG_REL_ VMCU SG_ 948 LoadDistributionRequestedACK_ISi 3000;
BA_REL_ "GenSigTimeoutTime" BU_SG_REL_ VMCU SG_ 948 LoadDistributionRequestedACK_ISi 300;
BA_REL_ "GenSigFirstTimeoutTime" BU_SG_REL_ CCIOM SG_ 948 TotalFrontBellowTorqueRef 3000;
BA_REL_ "GenSigTimeoutTime" BU_SG_REL_ CCIOM SG_ 948 TotalFrontBellowTorqueRef 300;
BA_REL_ "GenSigFirstTimeoutTime" BU_SG_REL_ VMCU SG_ 948 DirIndRearLamp_Stat_ISig_6 3000;
BA_REL_ "GenSigTimeoutTime" BU_SG_REL_ VMCU SG_ 948 DirIndRearLamp_Stat_ISig_6 500;
BA_REL_ "GenSigFirstTimeoutTime" BU_SG_REL_ VMCU SG_ 948 FrontEndPositionStatus_ISig_6 3000;
BA_REL_ "GenSigTimeoutTime" BU_SG_REL_ VMCU SG_ 948 FrontEndPositionStatus_ISig_6 300;
BA_REL_ "GenSigFirstTimeoutTime" BU_SG_REL_ VMCU SG_ 947 FPBRMMIStat_FPBRChangeAck_ISig_6 3000;
BA_REL_ "GenSigTimeoutTime" BU_SG_REL_ VMCU SG_ 947 FPBRMMIStat_FPBRChangeAck_ISig_6 300;
BA_REL_ "GenSigFirstTimeoutTime" BU_SG_REL_ FAS SG_ 947 FrontLevRefCtrl_ShortPushCnt 3000;
BA_REL_ "GenSigTimeoutTime" BU_SG_REL_ FAS SG_ 947 FrontLevRefCtrl_ShortPushCnt 300;
BA_REL_ "GenSigFirstTimeoutTime" BU_SG_REL_ CCIOM SG_ 947 FrontLevRefCtrl_ShortPushCnt 3000;
BA_REL_ "GenSigTimeoutTime" BU_SG_REL_ CCIOM SG_ 947 FrontLevRefCtrl_ShortPushCnt 300;
BA_REL_ "GenSigFirstTimeoutTime" BU_SG_REL_ VMCU SG_ 947 RelativeLevelRearAxleRight_ISig_ 3000;
BA_REL_ "GenSigTimeoutTime" BU_SG_REL_ VMCU SG_ 947 RelativeLevelRearAxleRight_ISig_ 300;
BA_REL_ "GenSigFirstTimeoutTime" BU_SG_REL_ EBS SG_ 947 RelativeLevelRearAxleRight_ISig_ 3000;
BA_REL_ "GenSigTimeoutTime" BU_SG_REL_ EBS SG_ 947 RelativeLevelRearAxleRight_ISig_ 300;
BA_REL_ "GenSigFirstTimeoutTime" BU_SG_REL_ EBS SG_ 947 RelativeLevelRearAxleLeft_ISig_6 3000;
BA_REL_ "GenSigTimeoutTime" BU_SG_REL_ EBS SG_ 947 RelativeLevelRearAxleLeft_ISig_6 300;
BA_REL_ "GenSigFirstTimeoutTime" BU_SG_REL_ VMCU SG_ 947 RelativeLevelRearAxleLeft_ISig_6 3000;
BA_REL_ "GenSigTimeoutTime" BU_SG_REL_ VMCU SG_ 947 RelativeLevelRearAxleLeft_ISig_6 300;
BA_REL_ "GenSigFirstTimeoutTime" BU_SG_REL_ VMCU SG_ 947 FPBRMMIStat_FPBRStatusInd_ISig_6 3000;
BA_REL_ "GenSigTimeoutTime" BU_SG_REL_ VMCU SG_ 947 FPBRMMIStat_FPBRStatusInd_ISig_6 300;
BA_REL_ "GenSigFirstTimeoutTime" BU_SG_REL_ VMCU SG_ 947 LiftAxle1LiftAllowed_Stat 3000;
BA_REL_ "GenSigTimeoutTime" BU_SG_REL_ VMCU SG_ 947 LiftAxle1LiftAllowed_Stat 300;
BA_REL_ "GenSigFirstTimeoutTime" BU_SG_REL_ CCIOM SG_ 947 FrontLevRefCtrl_LevelRef 3000;
BA_REL_ "GenSigTimeoutTime" BU_SG_REL_ CCIOM SG_ 947 FrontLevRefCtrl_LevelRef 300;
BA_REL_ "GenSigFirstTimeoutTime" BU_SG_REL_ FAS SG_ 947 FrontLevRefCtrl_LevelRef 3000;
BA_REL_ "GenSigTimeoutTime" BU_SG_REL_ FAS SG_ 947 FrontLevRefCtrl_LevelRef 300;
BA_REL_ "GenSigFirstTimeoutTime" BU_SG_REL_ VMCU SG_ 530 TrailerWithoutABS_ISig_6 3000;
BA_REL_ "GenSigTimeoutTime" BU_SG_REL_ VMCU SG_ 530 TrailerWithoutABS_ISig_6 500;
BA_REL_ "GenSigFirstTimeoutTime" BU_SG_REL_ TPM SG_ 530 TrailerConnected_ISig_6 3000;
BA_REL_ "GenSigTimeoutTime" BU_SG_REL_ TPM SG_ 530 TrailerConnected_ISig_6 500;
BA_REL_ "GenSigFirstTimeoutTime" BU_SG_REL_ APM SG_ 530 TrailerConnected_ISig_6 3000;
BA_REL_ "GenSigTimeoutTime" BU_SG_REL_ APM SG_ 530 TrailerConnected_ISig_6 500;
BA_REL_ "GenSigFirstTimeoutTime" BU_SG_REL_ CCIOM SG_ 530 TrailerConnected_ISig_6 3000;
BA_REL_ "GenSigTimeoutTime" BU_SG_REL_ CCIOM SG_ 530 TrailerConnected_ISig_6 500;
BA_REL_ "GenSigFirstTimeoutTime" BU_SG_REL_ VMCU SG_ 530 TrailerConnected_ISig_6 3000;
BA_REL_ "GenSigTimeoutTime" BU_SG_REL_ VMCU SG_ 530 TrailerConnected_ISig_6 500;
BA_REL_ "GenSigFirstTimeoutTime" BU_SG_REL_ VMCU SG_ 530 SupplyPressure 3000;
BA_REL_ "GenSigTimeoutTime" BU_SG_REL_ VMCU SG_ 530 SupplyPressure 120;
BA_REL_ "GenSigFirstTimeoutTime" BU_SG_REL_ CCIOM SG_ 530 SupplyPressure 3000;
BA_REL_ "GenSigTimeoutTime" BU_SG_REL_ CCIOM SG_ 530 SupplyPressure 300;
BA_REL_ "GenSigFirstTimeoutTime" BU_SG_REL_ CCIOM SG_ 530 PitchAngle 3000;
BA_REL_ "GenSigTimeoutTime" BU_SG_REL_ CCIOM SG_ 530 PitchAngle 300;
BA_REL_ "GenSigFirstTimeoutTime" BU_SG_REL_ VMCU SG_ 530 PitchAngle 3000;
BA_REL_ "GenSigTimeoutTime" BU_SG_REL_ VMCU SG_ 530 PitchAngle 120;
BA_REL_ "GenSigFirstTimeoutTime" BU_SG_REL_ APM SG_ 530 SWBrakeSwitch_ISig_6 3000;
BA_REL_ "GenSigTimeoutTime" BU_SG_REL_ APM SG_ 530 SWBrakeSwitch_ISig_6 500;
BA_REL_ "GenSigFirstTimeoutTime" BU_SG_REL_ VMCU SG_ 530 SWBrakeSwitch_ISig_6 3000;
BA_REL_ "GenSigTimeoutTime" BU_SG_REL_ VMCU SG_ 530 SWBrakeSwitch_ISig_6 500;
BA_REL_ "GenSigFirstTimeoutTime" BU_SG_REL_ CCIOM SG_ 530 PitchAngleRef 3000;
BA_REL_ "GenSigTimeoutTime" BU_SG_REL_ CCIOM SG_ 530 PitchAngleRef 300;
BA_REL_ "GenSigFirstTimeoutTime" BU_SG_REL_ VMCU SG_ 530 RearAxle2DiffLock_stat_ISig_6 3000;
BA_REL_ "GenSigTimeoutTime" BU_SG_REL_ VMCU SG_ 530 RearAxle2DiffLock_stat_ISig_6 500;
BA_REL_ "GenSigFirstTimeoutTime" BU_SG_REL_ EBS SG_ 530 RearAxle2DiffLock_stat_ISig_6 3000;
BA_REL_ "GenSigTimeoutTime" BU_SG_REL_ EBS SG_ 530 RearAxle2DiffLock_stat_ISig_6 500;
BA_REL_ "GenSigFirstTimeoutTime" BU_SG_REL_ VMCU SG_ 530 CentralRearDiffLock_stat_ISig_6 3000;
BA_REL_ "GenSigTimeoutTime" BU_SG_REL_ VMCU SG_ 530 CentralRearDiffLock_stat_ISig_6 500;
BA_REL_ "GenSigFirstTimeoutTime" BU_SG_REL_ EBS SG_ 530 CentralRearDiffLock_stat_ISig_6 3000;
BA_REL_ "GenSigTimeoutTime" BU_SG_REL_ EBS SG_ 530 CentralRearDiffLock_stat_ISig_6 500;
BA_REL_ "GenSigFirstTimeoutTime" BU_SG_REL_ VMCU SG_ 530 BackToDriveReqACK_ISig_6 3000;
BA_REL_ "GenSigTimeoutTime" BU_SG_REL_ VMCU SG_ 530 BackToDriveReqACK_ISig_6 120;
BA_REL_ "GenSigFirstTimeoutTime" BU_SG_REL_ VMCU SG_ 530 RearAxle1DiffLock_stat_ISig_6 3000;
BA_REL_ "GenSigTimeoutTime" BU_SG_REL_ VMCU SG_ 530 RearAxle1DiffLock_stat_ISig_6 500;
BA_REL_ "GenSigFirstTimeoutTime" BU_SG_REL_ EBS SG_ 530 RearAxle1DiffLock_stat_ISig_6 3000;
BA_REL_ "GenSigTimeoutTime" BU_SG_REL_ EBS SG_ 530 RearAxle1DiffLock_stat_ISig_6 500;
BA_REL_ "GenSigFirstTimeoutTime" BU_SG_REL_ VMCU SG_ 528 RearEndPositionStatus_ISig_6 3000;
BA_REL_ "GenSigTimeoutTime" BU_SG_REL_ VMCU SG_ 528 RearEndPositionStatus_ISig_6 120;
BA_REL_ "GenSigFirstTimeoutTime" BU_SG_REL_ CCIOM SG_ 528 FrontFerryFunctionCmd 3000;
BA_REL_ "GenSigTimeoutTime" BU_SG_REL_ CCIOM SG_ 528 FrontFerryFunctionCmd 120;
BA_REL_ "GenSigFirstTimeoutTime" BU_SG_REL_ VMCU SG_ 528 RideHeightStatus_ISig_6 3000;
BA_REL_ "GenSigTimeoutTime" BU_SG_REL_ VMCU SG_ 528 RideHeightStatus_ISig_6 120;
BA_REL_ "GenSigFirstTimeoutTime" BU_SG_REL_ VMCU SG_ 528 KneelingInformation_ISig_6 3000;
BA_REL_ "GenSigTimeoutTime" BU_SG_REL_ VMCU SG_ 528 KneelingInformation_ISig_6 120;
BA_REL_ "GenSigFirstTimeoutTime" BU_SG_REL_ VMCU SG_ 528 RampHeightOutsideTargetRange_ISi 3000;
BA_REL_ "GenSigTimeoutTime" BU_SG_REL_ VMCU SG_ 528 RampHeightOutsideTargetRange_ISi 120;
BA_REL_ "GenSigFirstTimeoutTime" BU_SG_REL_ CCIOM SG_ 528 LiftAxle1PositionStatus_ISig_6 3000;
BA_REL_ "GenSigTimeoutTime" BU_SG_REL_ CCIOM SG_ 528 LiftAxle1PositionStatus_ISig_6 120;
BA_REL_ "GenSigFirstTimeoutTime" BU_SG_REL_ VMCU SG_ 528 LiftAxle1PositionStatus_ISig_6 3000;
BA_REL_ "GenSigTimeoutTime" BU_SG_REL_ VMCU SG_ 528 LiftAxle1PositionStatus_ISig_6 120;
BA_REL_ "GenSigFirstTimeoutTime" BU_SG_REL_ EBS SG_ 528 LiftAxle1PositionStatus_ISig_6 3000;
BA_REL_ "GenSigTimeoutTime" BU_SG_REL_ EBS SG_ 528 LiftAxle1PositionStatus_ISig_6 120;
BA_REL_ "GenSigFirstTimeoutTime" BU_SG_REL_ FAS SG_ 528 LiftAxle1PositionStatus_ISig_6 3000;
BA_REL_ "GenSigTimeoutTime" BU_SG_REL_ FAS SG_ 528 LiftAxle1PositionStatus_ISig_6 120;
BA_REL_ "GenSigFirstTimeoutTime" BU_SG_REL_ EAS SG_ 528 LiftAxle1PositionStatus_ISig_6 3000;
BA_REL_ "GenSigTimeoutTime" BU_SG_REL_ EAS SG_ 528 LiftAxle1PositionStatus_ISig_6 120;
BA_REL_ "GenSigFirstTimeoutTime" BU_SG_REL_ VMCU SG_ 528 HeightAdjustmentAllowed_ISig_6 3000;
BA_REL_ "GenSigTimeoutTime" BU_SG_REL_ VMCU SG_ 528 HeightAdjustmentAllowed_ISig_6 120;
BA_REL_ "GenSigFirstTimeoutTime" BU_SG_REL_ VMCU SG_ 528 FerryFunctionStatus_ISig_6 3000;
BA_REL_ "GenSigTimeoutTime" BU_SG_REL_ VMCU SG_ 528 FerryFunctionStatus_ISig_6 500;
BA_REL_ "GenSigFirstTimeoutTime" BU_SG_REL_ VMCU SG_ 528 LoadDistributionFuncSelected_ISi 3000;
BA_REL_ "GenSigTimeoutTime" BU_SG_REL_ VMCU SG_ 528 LoadDistributionFuncSelected_ISi 120;
BA_REL_ "GenSigFirstTimeoutTime" BU_SG_REL_ VMCU SG_ 528 RollEndPositionStatus_ISig_6 3000;
BA_REL_ "GenSigTimeoutTime" BU_SG_REL_ VMCU SG_ 528 RollEndPositionStatus_ISig_6 120;
BA_REL_ "GenSigFirstTimeoutTime" BU_SG_REL_ CCIOM SG_ 528 HeightControlMode 3000;
BA_REL_ "GenSigTimeoutTime" BU_SG_REL_ CCIOM SG_ 528 HeightControlMode 120;
BA_REL_ "GenSigFirstTimeoutTime" BU_SG_REL_ VMCU SG_ 528 RideHeightFunctionStatus_ISig_6 3000;
BA_REL_ "GenSigTimeoutTime" BU_SG_REL_ VMCU SG_ 528 RideHeightFunctionStatus_ISig_6 120;
BA_REL_ "GenSigFirstTimeoutTime" BU_SG_REL_ VMCU SG_ 528 LevelControlInformation_ISig_6 3000;
BA_REL_ "GenSigTimeoutTime" BU_SG_REL_ VMCU SG_ 528 LevelControlInformation_ISig_6 500;
BA_REL_ "GenSigFirstTimeoutTime" BU_SG_REL_ VMCU SG_ 528 KneelingStatusHMI_ISig_6 3000;
BA_REL_ "GenSigTimeoutTime" BU_SG_REL_ VMCU SG_ 528 KneelingStatusHMI_ISig_6 120;
BA_REL_ "GenSigFirstTimeoutTime" BU_SG_REL_ VMCU SG_ 528 DirInd_Rear_Status 3000;
BA_REL_ "GenSigTimeoutTime" BU_SG_REL_ VMCU SG_ 528 DirInd_Rear_Status 120;
BA_REL_ "GenSigFirstTimeoutTime" BU_SG_REL_ CCIOM SG_ 528 VehicleDynamicSuspProhibitStat 3000;
BA_REL_ "GenSigTimeoutTime" BU_SG_REL_ CCIOM SG_ 528 VehicleDynamicSuspProhibitStat 120;
BA_REL_ "GenSigFirstTimeoutTime" BU_SG_REL_ VMCU SG_ 528 ChangeKneelACK_ISig_6 3000;
BA_REL_ "GenSigTimeoutTime" BU_SG_REL_ VMCU SG_ 528 ChangeKneelACK_ISig_6 120;
BA_REL_ "GenSigFirstTimeoutTime" BU_SG_REL_ CCIOM SG_ 528 ECSShutdownCmd 3000;
BA_REL_ "GenSigTimeoutTime" BU_SG_REL_ CCIOM SG_ 528 ECSShutdownCmd 120;
BA_REL_ "GenSigFirstTimeoutTime" BU_SG_REL_ VMCU SG_ 528 LiftAxle2PositionStatus_ISig_6 3000;
BA_REL_ "GenSigTimeoutTime" BU_SG_REL_ VMCU SG_ 528 LiftAxle2PositionStatus_ISig_6 120;
BA_REL_ "GenSigFirstTimeoutTime" BU_SG_REL_ EBS SG_ 528 LiftAxle2PositionStatus_ISig_6 3000;
BA_REL_ "GenSigTimeoutTime" BU_SG_REL_ EBS SG_ 528 LiftAxle2PositionStatus_ISig_6 120;
BA_REL_ "GenSigFirstTimeoutTime" BU_SG_REL_ FAS SG_ 528 LiftAxle2PositionStatus_ISig_6 3000;
BA_REL_ "GenSigTimeoutTime" BU_SG_REL_ FAS SG_ 528 LiftAxle2PositionStatus_ISig_6 120;
BA_REL_ "GenSigFirstTimeoutTime" BU_SG_REL_ VMCU SG_ 517 BrakePressureSensorDemand_ISig_6 3000;
BA_REL_ "GenSigTimeoutTime" BU_SG_REL_ VMCU SG_ 517 BrakePressureSensorDemand_ISig_6 500;
BA_REL_ "GenSigFirstTimeoutTime" BU_SG_REL_ APM SG_ 517 BrakePressureSensorDemand_ISig_6 3000;
BA_REL_ "GenSigTimeoutTime" BU_SG_REL_ APM SG_ 517 BrakePressureSensorDemand_ISig_6 500;
BA_REL_ "GenSigFirstTimeoutTime" BU_SG_REL_ VMCU SG_ 517 RampLevelStatus_ISig_6 3000;
BA_REL_ "GenSigTimeoutTime" BU_SG_REL_ VMCU SG_ 517 RampLevelStatus_ISig_6 120;
BA_REL_ "GenSigFirstTimeoutTime" BU_SG_REL_ VMCU SG_ 517 LiftAxle2LowerACK_ISig_6 3000;
BA_REL_ "GenSigTimeoutTime" BU_SG_REL_ VMCU SG_ 517 LiftAxle2LowerACK_ISig_6 120;
BA_REL_ "GenSigFirstTimeoutTime" BU_SG_REL_ VMCU SG_ 517 LiftAxle2UpRequestACK_ISig_6 3000;
BA_REL_ "GenSigTimeoutTime" BU_SG_REL_ VMCU SG_ 517 LiftAxle2UpRequestACK_ISig_6 120;
BA_REL_ "GenSigFirstTimeoutTime" BU_SG_REL_ CCIOM SG_ 517 FrontLimpHomeCmd 3000;
BA_REL_ "GenSigTimeoutTime" BU_SG_REL_ CCIOM SG_ 517 FrontLimpHomeCmd 120;
BA_REL_ "GenSigFirstTimeoutTime" BU_SG_REL_ VMCU SG_ 517 LiftAxle1LiftFuncSelected_ISig_6 3000;
BA_REL_ "GenSigTimeoutTime" BU_SG_REL_ VMCU SG_ 517 LiftAxle1LiftFuncSelected_ISig_6 120;
BA_REL_ "GenSigFirstTimeoutTime" BU_SG_REL_ VMCU SG_ 517 RearAxleInBumperRange_ISig_6 3000;
BA_REL_ "GenSigTimeoutTime" BU_SG_REL_ VMCU SG_ 517 RearAxleInBumperRange_ISig_6 500;
BA_REL_ "GenSigFirstTimeoutTime" BU_SG_REL_ VMCU SG_ 517 LiftAxle1UpRequestACK_ISig_6 3000;
BA_REL_ "GenSigTimeoutTime" BU_SG_REL_ VMCU SG_ 517 LiftAxle1UpRequestACK_ISig_6 120;
BA_REL_ "GenSigFirstTimeoutTime" BU_SG_REL_ VMCU SG_ 517 FogLamp_Rear_Status 3000;
BA_REL_ "GenSigTimeoutTime" BU_SG_REL_ VMCU SG_ 517 FogLamp_Rear_Status 120;
BA_REL_ "GenSigFirstTimeoutTime" BU_SG_REL_ VMCU SG_ 517 StopLevelChangeAck_ISig_6 3000;
BA_REL_ "GenSigTimeoutTime" BU_SG_REL_ VMCU SG_ 517 StopLevelChangeAck_ISig_6 120;
BA_REL_ "GenSigFirstTimeoutTime" BU_SG_REL_ VMCU SG_ 517 RampLevelStorageAck_ISig_6 3000;
BA_REL_ "GenSigTimeoutTime" BU_SG_REL_ VMCU SG_ 517 RampLevelStorageAck_ISig_6 120;
BA_REL_ "GenSigFirstTimeoutTime" BU_SG_REL_ VMCU SG_ 517 RideHeightOutsideTargetRange_ISi 3000;
BA_REL_ "GenSigTimeoutTime" BU_SG_REL_ VMCU SG_ 517 RideHeightOutsideTargetRange_ISi 120;
BA_REL_ "GenSigFirstTimeoutTime" BU_SG_REL_ APM SG_ 517 LiftingControlModeFrontAxle_ISig 3000;
BA_REL_ "GenSigTimeoutTime" BU_SG_REL_ APM SG_ 517 LiftingControlModeFrontAxle_ISig 120;
BA_REL_ "GenSigFirstTimeoutTime" BU_SG_REL_ VMCU SG_ 517 LiftingControlModeFrontAxle_ISig 3000;
BA_REL_ "GenSigTimeoutTime" BU_SG_REL_ VMCU SG_ 517 LiftingControlModeFrontAxle_ISig 120;
BA_REL_ "GenSigFirstTimeoutTime" BU_SG_REL_ VMCU SG_ 517 LoadDistributionChangeACK_ISig_6 3000;
BA_REL_ "GenSigTimeoutTime" BU_SG_REL_ VMCU SG_ 517 LoadDistributionChangeACK_ISig_6 120;
BA_REL_ "GenSigFirstTimeoutTime" BU_SG_REL_ VMCU SG_ 517 RideHeightStorageAck_ISig_6 3000;
BA_REL_ "GenSigTimeoutTime" BU_SG_REL_ VMCU SG_ 517 RideHeightStorageAck_ISig_6 120;
BA_REL_ "GenSigFirstTimeoutTime" BU_SG_REL_ VMCU SG_ 517 ECSStandbyAllowed_ISig_6 3000;
BA_REL_ "GenSigTimeoutTime" BU_SG_REL_ VMCU SG_ 517 ECSStandbyAllowed_ISig_6 120;
BA_REL_ "GenSigFirstTimeoutTime" BU_SG_REL_ VMCU SG_ 517 LiftAxle2LiftFuncSelected_ISig_6 3000;
BA_REL_ "GenSigTimeoutTime" BU_SG_REL_ VMCU SG_ 517 LiftAxle2LiftFuncSelected_ISig_6 120;
BA_REL_ "GenSigFirstTimeoutTime" BU_SG_REL_ CCIOM SG_ 517 FrontProhibitControlRequest 3000;
BA_REL_ "GenSigTimeoutTime" BU_SG_REL_ CCIOM SG_ 517 FrontProhibitControlRequest 120;
BA_REL_ "GenSigFirstTimeoutTime" BU_SG_REL_ VMCU SG_ 517 LiftingControlModeRearAxle_ISig_ 3000;
BA_REL_ "GenSigTimeoutTime" BU_SG_REL_ VMCU SG_ 517 LiftingControlModeRearAxle_ISig_ 120;
BA_REL_ "GenSigFirstTimeoutTime" BU_SG_REL_ APM SG_ 517 LiftingControlModeRearAxle_ISig_ 3000;
BA_REL_ "GenSigTimeoutTime" BU_SG_REL_ APM SG_ 517 LiftingControlModeRearAxle_ISig_ 120;
BA_REL_ "GenSigFirstTimeoutTime" BU_SG_REL_ VMCU SG_ 517 ProhibitControlStatus_ISig_6 3000;
BA_REL_ "GenSigTimeoutTime" BU_SG_REL_ VMCU SG_ 517 ProhibitControlStatus_ISig_6 120;
BA_REL_ "GenSigFirstTimeoutTime" BU_SG_REL_ CCIOM SG_ 517 DisableMechFaultDctnFr_rqst 3000;
BA_REL_ "GenSigTimeoutTime" BU_SG_REL_ CCIOM SG_ 517 DisableMechFaultDctnFr_rqst 120;
BA_REL_ "GenSigFirstTimeoutTime" BU_SG_REL_ EBS SG_ 517 FrontParkBrakeOverrideCommand 3000;
BA_REL_ "GenSigTimeoutTime" BU_SG_REL_ EBS SG_ 517 FrontParkBrakeOverrideCommand 120;
BA_REL_ "GenSigFirstTimeoutTime" BU_SG_REL_ VMCU SG_ 1339 FrontConspicLamp_stat_LoLeft_ISi 6000;
BA_REL_ "GenSigTimeoutTime" BU_SG_REL_ VMCU SG_ 1339 FrontConspicLamp_stat_LoLeft_ISi 1500;
BA_REL_ "GenSigFirstTimeoutTime" BU_SG_REL_ VMCU SG_ 1339 HeadlampFan_stat_ISig_6 6000;
BA_REL_ "GenSigTimeoutTime" BU_SG_REL_ VMCU SG_ 1339 HeadlampFan_stat_ISig_6 1500;
BA_REL_ "GenSigFirstTimeoutTime" BU_SG_REL_ VMCU SG_ 1339 FrontConspicLamp_stat_HiLeft_ISi 6000;
BA_REL_ "GenSigTimeoutTime" BU_SG_REL_ VMCU SG_ 1339 FrontConspicLamp_stat_HiLeft_ISi 1500;
BA_REL_ "GenSigFirstTimeoutTime" BU_SG_REL_ VMCU SG_ 1339 FrontConspicLamp_stat_LoRight_IS 6000;
BA_REL_ "GenSigTimeoutTime" BU_SG_REL_ VMCU SG_ 1339 FrontConspicLamp_stat_LoRight_IS 1500;
BA_REL_ "GenSigFirstTimeoutTime" BU_SG_REL_ VMCU SG_ 1339 AmbientAirTemperature2 6000;
BA_REL_ "GenSigTimeoutTime" BU_SG_REL_ VMCU SG_ 1339 AmbientAirTemperature2 1500;
BA_REL_ "GenSigFirstTimeoutTime" BU_SG_REL_ VMCU SG_ 1339 FrontConspicLamp_stat_HiRight_IS 6000;
BA_REL_ "GenSigTimeoutTime" BU_SG_REL_ VMCU SG_ 1339 FrontConspicLamp_stat_HiRight_IS 1500;
BA_REL_ "GenSigFirstTimeoutTime" BU_SG_REL_ VMCU SG_ 1243 MainBeamLEDStatusLeft_ISig_6 3000;
BA_REL_ "GenSigTimeoutTime" BU_SG_REL_ VMCU SG_ 1243 MainBeamLEDStatusLeft_ISig_6 600;
BA_REL_ "GenSigFirstTimeoutTime" BU_SG_REL_ VMCU SG_ 1243 MainBeamLEDStatusRight_ISig_6 3000;
BA_REL_ "GenSigTimeoutTime" BU_SG_REL_ VMCU SG_ 1243 MainBeamLEDStatusRight_ISig_6 600;
VAL_ 1522 Trailer1TPMThresCfg_AxleNr_ISig_ 7 "TPMAxleNr_NotAvailable" 6 "TPMAxleNr_Error" 5 "TPMAxleNr_Axle5" 4 "TPMAxleNr_Axle4" 3 "TPMAxleNr_Axle3" 2 "TPMAxleNr_Axle2" 1 "TPMAxleNr_Axle1" 0 "TPMAxleNr_NoRequest" ;
VAL_ 1522 Trailer1TPMAxlTireCfg_Axle5_ISig 7 "TPMAxleConfig_NotAvailable" 6 "TPMAxleConfig_Error" 5 "TPMAxleConfig_Spare" 4 "TPMAxleConfig_RearAxleWith4Tires" 3 "TPMAxleConfig_RearAxleWith2Tires" 2 "TPMAxleConfig_FrontAxleWith4Tires" 1 "TPMAxleConfig_FrontAxleWith2Tires" 0 "TPMAxleConfig_NotPresent" ;
VAL_ 1522 Trailer1TPMAxlTireCfg_Axle1_ISig 7 "TPMAxleConfig_NotAvailable" 6 "TPMAxleConfig_Error" 5 "TPMAxleConfig_Spare" 4 "TPMAxleConfig_RearAxleWith4Tires" 3 "TPMAxleConfig_RearAxleWith2Tires" 2 "TPMAxleConfig_FrontAxleWith4Tires" 1 "TPMAxleConfig_FrontAxleWith2Tires" 0 "TPMAxleConfig_NotPresent" ;
VAL_ 1522 Trailer1TPMAxlTireCfg_Axle2_ISig 7 "TPMAxleConfig_NotAvailable" 6 "TPMAxleConfig_Error" 5 "TPMAxleConfig_Spare" 4 "TPMAxleConfig_RearAxleWith4Tires" 3 "TPMAxleConfig_RearAxleWith2Tires" 2 "TPMAxleConfig_FrontAxleWith4Tires" 1 "TPMAxleConfig_FrontAxleWith2Tires" 0 "TPMAxleConfig_NotPresent" ;
VAL_ 1522 Trailer1TPMType_ISig_6 3 "TPMTrailerType_NotAvailable" 2 "TPMTrailerType_Error" 1 "TPMTrailerType_ISO11992Trailer" 0 "TPMTrailerType_SKFWirelessTrailer" ;
VAL_ 1522 Trailer1TPMAxlTireCfg_Axle3_ISig 7 "TPMAxleConfig_NotAvailable" 6 "TPMAxleConfig_Error" 5 "TPMAxleConfig_Spare" 4 "TPMAxleConfig_RearAxleWith4Tires" 3 "TPMAxleConfig_RearAxleWith2Tires" 2 "TPMAxleConfig_FrontAxleWith4Tires" 1 "TPMAxleConfig_FrontAxleWith2Tires" 0 "TPMAxleConfig_NotPresent" ;
VAL_ 1522 Trailer1TPMAxlTireCfg_Axle4_ISig 7 "TPMAxleConfig_NotAvailable" 6 "TPMAxleConfig_Error" 5 "TPMAxleConfig_Spare" 4 "TPMAxleConfig_RearAxleWith4Tires" 3 "TPMAxleConfig_RearAxleWith2Tires" 2 "TPMAxleConfig_FrontAxleWith4Tires" 1 "TPMAxleConfig_FrontAxleWith2Tires" 0 "TPMAxleConfig_NotPresent" ;
VAL_ 951 Trailer2LiftAxle2PosReq 3 "TrailerLiftAxlePosReq_TakeNoAction" 2 "TrailerLiftAxlePosReq_Reserved" 1 "TrailerLiftAxlePosReq_RequestToLiftTheLiftAxle" 0 "TrailerLiftAxlePosReq_RequestToLowerTheLiftAxle" ;
VAL_ 951 Trailer3LiftAxle2PosReq 3 "TrailerLiftAxlePosReq_TakeNoAction" 2 "TrailerLiftAxlePosReq_Reserved" 1 "TrailerLiftAxlePosReq_RequestToLiftTheLiftAxle" 0 "TrailerLiftAxlePosReq_RequestToLowerTheLiftAxle" ;
VAL_ 951 Trailer1LiftAxle1PosReq 3 "TrailerLiftAxlePosReq_TakeNoAction" 2 "TrailerLiftAxlePosReq_Reserved" 1 "TrailerLiftAxlePosReq_RequestToLiftTheLiftAxle" 0 "TrailerLiftAxlePosReq_RequestToLowerTheLiftAxle" ;
VAL_ 951 Trailer2LiftAxle1PosReq 3 "TrailerLiftAxlePosReq_TakeNoAction" 2 "TrailerLiftAxlePosReq_Reserved" 1 "TrailerLiftAxlePosReq_RequestToLiftTheLiftAxle" 0 "TrailerLiftAxlePosReq_RequestToLowerTheLiftAxle" ;
VAL_ 951 Trailer3LiftAxle1PosReq 3 "TrailerLiftAxlePosReq_TakeNoAction" 2 "TrailerLiftAxlePosReq_Reserved" 1 "TrailerLiftAxlePosReq_RequestToLiftTheLiftAxle" 0 "TrailerLiftAxlePosReq_RequestToLowerTheLiftAxle" ;
VAL_ 951 Trailer1LiftAxle2PosReq 3 "TrailerLiftAxlePosReq_TakeNoAction" 2 "TrailerLiftAxlePosReq_Reserved" 1 "TrailerLiftAxlePosReq_RequestToLiftTheLiftAxle" 0 "TrailerLiftAxlePosReq_RequestToLowerTheLiftAxle" ;
VAL_ 1344 RegenInhibitVehicleHeight_ISig_6 3 "ActiveStatus_NotAvailable" 2 "ActiveStatus_Error" 1 "ActiveStatus_Active" 0 "ActiveStatus_NotActive" ;
VAL_ 1343 TrailerPosLightRightOutputStat_I 7 "TrailerLightOutputStat_NotAvailable" 6 "TrailerLightOutputStat_Error" 5 "TrailerLightOutputStat_OutputActiveStatusUncertain" 4 "TrailerLightOutputStat_OutputActiveLightDetectedOnActivation" 3 "TrailerLightOutputStat_OutputActiveLightDetected" 2 "TrailerLightOutputStat_OutputActiveNoLightDetected" 1 "TrailerLightOutputStat_OutputActiveDetectionOngoing" 0 "TrailerLightOutputStat_OutputInactive" ;
VAL_ 1343 TrailerBrakeLightOutputStat_ISig 7 "TrailerLightOutputStat_NotAvailable" 6 "TrailerLightOutputStat_Error" 5 "TrailerLightOutputStat_OutputActiveStatusUncertain" 4 "TrailerLightOutputStat_OutputActiveLightDetectedOnActivation" 3 "TrailerLightOutputStat_OutputActiveLightDetected" 2 "TrailerLightOutputStat_OutputActiveNoLightDetected" 1 "TrailerLightOutputStat_OutputActiveDetectionOngoing" 0 "TrailerLightOutputStat_OutputInactive" ;
VAL_ 1343 TrailerDirIndRightOutputStat_ISi 7 "TrailerLightOutputStat_NotAvailable" 6 "TrailerLightOutputStat_Error" 5 "TrailerLightOutputStat_OutputActiveStatusUncertain" 4 "TrailerLightOutputStat_OutputActiveLightDetectedOnActivation" 3 "TrailerLightOutputStat_OutputActiveLightDetected" 2 "TrailerLightOutputStat_OutputActiveNoLightDetected" 1 "TrailerLightOutputStat_OutputActiveDetectionOngoing" 0 "TrailerLightOutputStat_OutputInactive" ;
VAL_ 1343 ExtECSPressureUpdateAck 7 "ExtECSPressureUpdateAck_NotAvailable" 6 "ExtECSPressureUpdateAck_Error" 5 "ExtECSPressureUpdateAck_Spare4" 4 "ExtECSPressureUpdateAck_Spare3" 3 "ExtECSPressureUpdateAck_Spare2" 2 "ExtECSPressureUpdateAck_Spare1" 1 "ExtECSPressureUpdateAck_InProgress" 0 "ExtECSPressureUpdateAck_NoRequest" ;
VAL_ 1343 TrailerPosLightLeftOutputStat_IS 7 "TrailerLightOutputStat_NotAvailable" 6 "TrailerLightOutputStat_Error" 5 "TrailerLightOutputStat_OutputActiveStatusUncertain" 4 "TrailerLightOutputStat_OutputActiveLightDetectedOnActivation" 3 "TrailerLightOutputStat_OutputActiveLightDetected" 2 "TrailerLightOutputStat_OutputActiveNoLightDetected" 1 "TrailerLightOutputStat_OutputActiveDetectionOngoing" 0 "TrailerLightOutputStat_OutputInactive" ;
VAL_ 1343 TrailerDirIndLeftOutputStat_ISig 7 "TrailerLightOutputStat_NotAvailable" 6 "TrailerLightOutputStat_Error" 5 "TrailerLightOutputStat_OutputActiveStatusUncertain" 4 "TrailerLightOutputStat_OutputActiveLightDetectedOnActivation" 3 "TrailerLightOutputStat_OutputActiveLightDetected" 2 "TrailerLightOutputStat_OutputActiveNoLightDetected" 1 "TrailerLightOutputStat_OutputActiveDetectionOngoing" 0 "TrailerLightOutputStat_OutputInactive" ;
VAL_ 1343 LoadDistributionSelected2_ISig_6 15 "LoadDistributionSelected2_NotAvailable" 14 "LoadDistributionSelected2_Error" 13 "LoadDistributionSelected2_Reserved_01" 12 "LoadDistributionSelected2_TractionHelp2InterDiff" 11 "LoadDistributionSelected2_StartingHelp2InterDiff" 10 "LoadDistributionSelected2_TractionHelp2" 9 "LoadDistributionSelected2_StartingHelp2" 8 "LoadDistributionSelected2_VariableAxleLoad" 7 "LoadDistributionSelected2_NoLoadDistribution" 6 "LoadDistributionSelected2_TractionHelpInterDiff" 5 "LoadDistributionSelected2_StartingHelpInterDiff" 4 "LoadDistributionSelected2_AlternativeLoad" 3 "LoadDistributionSelected2_TractionHelp" 2 "LoadDistributionSelected2_StartingHelp" 1 "LoadDistributionSelected2_OptimisedTraction" 0 "LoadDistributionSelected2_NormalLoad" ;
VAL_ 825 RevLight_cmd 3 "InactiveActive_NotAvailable" 2 "InactiveActive_Error" 1 "InactiveActive_Active" 0 "InactiveActive_Inactive" ;
VAL_ 825 LoadDistributionALDChangeACK_ISi 7 "LoadDistributionALDChangeACK_NotAvailable" 6 "LoadDistributionALDChangeACK_Error" 5 "LoadDistributionALDChangeACK_SystemDeniedVersatile" 4 "LoadDistributionALDChangeACK_Spare_01" 3 "LoadDistributionALDChangeACK_Spare" 2 "LoadDistributionALDChangeACK_LoadShiftDeniedOverspeed" 1 "LoadDistributionALDChangeACK_ChangeAcknowledged" 0 "LoadDistributionALDChangeACK_NoAction" ;
VAL_ 825 LiftAxle2AutoLiftSelected_ISig_6 3 "FalseTrue_NotAvaiable" 2 "FalseTrue_Error" 1 "FalseTrue_True" 0 "FalseTrue_False" ;
VAL_ 825 DriveLevelPosUserInteraction_ISi 7 "DriveLevelPosUserInteraction_NotAvailable" 6 "DriveLevelPosUserInteraction_Error" 5 "DriveLevelPosUserInteraction_Spare3" 4 "DriveLevelPosUserInteraction_Spare2" 3 "DriveLevelPosUserInteraction_Spare1" 2 "DriveLevelPosUserInteraction_WarningDriveLevelPosNotSelected" 1 "DriveLevelPosUserInteraction_DriveLevelPositionNotSelected" 0 "DriveLevelPosUserInteraction_DriveLevelPositionSelected" ;
VAL_ 825 FirstAxleLowerPrioSelected_ISig_ 7 "FirstAxleLowerPrio_NotAvailable" 6 "FirstAxleLowerPrio_Error" 5 "FirstAxleLowerPrio_Reserved_03" 4 "FirstAxleLowerPrio_Reserved_02" 3 "FirstAxleLowerPrio_Reserved_01" 2 "FirstAxleLowerPrio_Reserved" 1 "FirstAxleLowerPrio_LowerPusher" 0 "FirstAxleLowerPrio_LowerTag" ;
VAL_ 825 FerryFunctionSwitchChangeACK_ISi 3 "Ack2Bit_NotAvailable" 2 "Ack2Bit_Error" 1 "Ack2Bit_ChangeAcknowledged" 0 "Ack2Bit_NoAction" ;
VAL_ 825 TrailerDirInd_status 7 "DirIndFaultStatus_NotAvailable" 6 "DirIndFaultStatus_Error" 5 "DirIndFaultStatus_SpareValue_01" 4 "DirIndFaultStatus_SpareValue" 3 "DirIndFaultStatus_BothLeftAndRightDirectionIndicatorsFault" 2 "DirIndFaultStatus_RightDirectionIndicatorLampFault" 1 "DirIndFaultStatus_LeftDirectionIndicatorLampFault" 0 "DirIndFaultStatus_NoError" ;
VAL_ 825 RevLightLamp_stat_ISig_6 7 "LampCheckLeftRight_stat_NotAvailable" 6 "LampCheckLeftRight_stat_Error" 5 "LampCheckLeftRight_stat_Spare" 4 "LampCheckLeftRight_stat_TestedLeftAndRightLampNOK" 3 "LampCheckLeftRight_stat_TestedRightLampNOK" 2 "LampCheckLeftRight_stat_TestedLeftLampNOK" 1 "LampCheckLeftRight_stat_TestedLampOK" 0 "LampCheckLeftRight_stat_NotTested" ;
VAL_ 825 UnevenLoadWarning_ISig_6 3 "Warning_NotAvailable" 2 "Warning_Error" 1 "Warning_Warning" 0 "Warning_NoWarning" ;
VAL_ 825 LoadDistributionSelected_ISig_6 15 "LoadDistributionSelected_NotAvailable" 14 "LoadDistributionSelected_Error" 13 "LoadDistributionSelected_Reserved_05" 12 "LoadDistributionSelected_Reserved_04" 11 "LoadDistributionSelected_Reserved_03" 10 "LoadDistributionSelected_TractionHelp2" 9 "LoadDistributionSelected_StartingHelp2" 8 "LoadDistributionSelected_VariableAxleLoad" 7 "LoadDistributionSelected_NoLoadDistribution" 6 "LoadDistributionSelected_TractionHelpInterDiff" 5 "LoadDistributionSelected_StartingHelpInterDiff" 4 "LoadDistributionSelected_AlternativeLoad" 3 "LoadDistributionSelected_TractionHelp" 2 "LoadDistributionSelected_StartingHelp" 1 "LoadDistributionSelected_OptimisedTraction" 0 "LoadDistributionSelected_NormalLoad" ;
VAL_ 825 PositionLightRearLamp_stat_ISig_ 7 "LampCheckLeftRight_stat_NotAvailable" 6 "LampCheckLeftRight_stat_Error" 5 "LampCheckLeftRight_stat_Spare" 4 "LampCheckLeftRight_stat_TestedLeftAndRightLampNOK" 3 "LampCheckLeftRight_stat_TestedRightLampNOK" 2 "LampCheckLeftRight_stat_TestedLeftLampNOK" 1 "LampCheckLeftRight_stat_TestedLampOK" 0 "LampCheckLeftRight_stat_NotTested" ;
VAL_ 825 LiftAxle1AutoLiftSelected_ISig_6 3 "FalseTrue_NotAvaiable" 2 "FalseTrue_Error" 1 "FalseTrue_True" 0 "FalseTrue_False" ;
VAL_ 825 StartupProhibitStatus_ISig_6 3 "InactiveActive_NotAvailable" 2 "InactiveActive_Error" 1 "InactiveActive_Active" 0 "InactiveActive_Inactive" ;
VAL_ 825 LiftAxle1LowerACK_ISig_6 7 "LiftAxle1LowerACK_NotAvailable" 6 "LiftAxle1LowerACK_Error" 5 "LiftAxle1LowerACK_SystemDeniedVersatile" 4 "LiftAxle1LowerACK_Spare_01" 3 "LiftAxle1LowerACK_Spare" 2 "LiftAxle1LowerACK_LowerDeniedRAS_EC" 1 "LiftAxle1LowerACK_ChangeAcknowledged" 0 "LiftAxle1LowerACK_NoAction" ;
VAL_ 825 RampLevelRequestACK_ISig_6 3 "ChangeRequest2Bit_NotAvailable" 2 "ChangeRequest2Bit_Error" 1 "ChangeRequest2Bit_Change" 0 "ChangeRequest2Bit_TakeNoAction" ;
VAL_ 825 BrakeLightLamp_stat_ISig_6 7 "LampCheckLeftRight_stat_NotAvailable" 6 "LampCheckLeftRight_stat_Error" 5 "LampCheckLeftRight_stat_Spare" 4 "LampCheckLeftRight_stat_TestedLeftAndRightLampNOK" 3 "LampCheckLeftRight_stat_TestedRightLampNOK" 2 "LampCheckLeftRight_stat_TestedLeftLampNOK" 1 "LampCheckLeftRight_stat_TestedLampOK" 0 "LampCheckLeftRight_stat_NotTested" ;
VAL_ 825 TrailerABSStatus_ISig_6 3 "TrailerABSStatus_NotAvailable" 2 "TrailerABSStatus_ErrorIndicator" 1 "TrailerABSStatus_OK" 0 "TrailerABSStatus_Error" ;
VAL_ 825 FogLightRearLamp_stat_ISig_6 7 "LampCheck_stat_NotAvailable" 6 "LampCheck_stat_Error" 5 "LampCheck_stat_Spare_02" 4 "LampCheck_stat_Spare_01" 3 "LampCheck_stat_Spare" 2 "LampCheck_stat_TestedLampNOK" 1 "LampCheck_stat_TestedLampOK" 0 "LampCheck_stat_NotTested" ;
VAL_ 825 ECSLimpHomeNotification_ISig_6 7 "ECSLimpHomeNotification_NotAvailable" 6 "ECSLimpHomeNotification_Error" 5 "ECSLimpHomeNotification_LimpHomeMode5" 4 "ECSLimpHomeNotification_LimpHomeMode4" 3 "ECSLimpHomeNotification_LimpHomeMode3" 2 "ECSLimpHomeNotification_LimpHomeMode2" 1 "ECSLimpHomeNotification_LimpHomeMode1" 0 "ECSLimpHomeNotification_NoLimpHomeMode" ;
VAL_ 825 BrakeLight_rqst_ISig_6 7 "BrakeLight_rqst_NotAvailable" 6 "BrakeLight_rqst_SpareValue_03" 5 "BrakeLight_rqst_SpareValue_02" 4 "BrakeLight_rqst_SpareValue_01" 3 "BrakeLight_rqst_SpareValue" 2 "BrakeLight_rqst_EmergencyBrakeLightOn" 1 "BrakeLight_rqst_BrakeLightOn" 0 "BrakeLight_rqst_BrakeLightAndEmergencyBrakeLightOff" ;
VAL_ 825 ECSValveActivationAllowed 3 "FalseTrue_NotAvaiable" 2 "FalseTrue_Error" 1 "FalseTrue_True" 0 "FalseTrue_False" ;
VAL_ 825 BrakeLightConvoy_rqst_ISig_6 3 "OffOn_NotAvailable" 2 "OffOn_Error" 1 "OffOn_On" 0 "OffOn_Off" ;
VAL_ 825 FrontParkBrakeOverrideInd_ISig_6 3 "FrontParkBrakeOverrideInd_NotAvailable" 2 "FrontParkBrakeOverrideInd_Error" 1 "FrontParkBrakeOverrideInd_FailedToOverride" 0 "FrontParkBrakeOverrideInd_OK" ;
VAL_ 948 FrontAxleInBumperRange_ISig_6 3 "AxleInBumperRange_NotAvailable" 2 "AxleInBumperRange_ErrorIndicator" 1 "AxleInBumperRange_ActualLevelWithinBumperRange" 0 "AxleInBumperRange_ActualLevelOutOfBumperRange" ;
VAL_ 948 Rear1ClutchStatus 3 "DisengageEngage_NotAvailable" 2 "DisengageEngage_Error" 1 "DisengageEngage_Engage" 0 "DisengageEngage_Disengage" ;
VAL_ 948 LoadDistributionRequestedACK_ISi 7 "LoadDistributionRequestedACK_NotAvailable" 6 "LoadDistributionRequestedACK_Error" 5 "LoadDistributionRequestedACK_SystemDeniedVersatile" 4 "LoadDistributionRequestedACK_Reserved2" 3 "LoadDistributionRequestedACK_Reserved1" 2 "LoadDistributionRequestedACK_LoadShiftDeniedFALIMOverload" 1 "LoadDistributionRequestedACK_ChangeAcknowledged" 0 "LoadDistributionRequestedACK_NoAction" ;
VAL_ 948 DirIndRearLamp_Stat_ISig_6 7 "LampCheckLeftRight_stat_NotAvailable" 6 "LampCheckLeftRight_stat_Error" 5 "LampCheckLeftRight_stat_Spare" 4 "LampCheckLeftRight_stat_TestedLeftAndRightLampNOK" 3 "LampCheckLeftRight_stat_TestedRightLampNOK" 2 "LampCheckLeftRight_stat_TestedLeftLampNOK" 1 "LampCheckLeftRight_stat_TestedLampOK" 0 "LampCheckLeftRight_stat_NotTested" ;
VAL_ 948 FrontEndPositionStatus_ISig_6 7 "EndPositionStatus_NotAvailable" 6 "EndPositionStatus_Error" 5 "EndPositionStatus_Reserved_01" 4 "EndPositionStatus_Reserved" 3 "EndPositionStatus_LiftingAndLoweringNotAllowed" 2 "EndPositionStatus_MinEndLevelReached" 1 "EndPositionStatus_MaxEndLevelReached" 0 "EndPositionStatus_NoEndLevelReached" ;
VAL_ 947 FPBRMMIStat_FPBRChangeAck_ISig_6 3 "Ack2Bit_NotAvailable" 2 "Ack2Bit_Error" 1 "Ack2Bit_ChangeAcknowledged" 0 "Ack2Bit_NoAction" ;
VAL_ 947 FPBRMMIStat_FPBRStatusInd_ISig_6 3 "FPBRStatusInd_NotAvailable" 2 "FPBRStatusInd_Changing" 1 "FPBRStatusInd_On" 0 "FPBRStatusInd_Off" ;
VAL_ 947 LiftAxle1LiftAllowed_Stat 7 "LiftAxleLiftAllowed_NotAvailable" 6 "LiftAxleLiftAllowed_Error" 5 "LiftAxleLiftAllowed_Spare2" 4 "LiftAxleLiftAllowed_Spare1" 3 "LiftAxleLiftAllowed_Stat_SystemDeniedVersatile" 2 "LiftAxleLiftAllowed_Stat_LiftDeniedRearOverload" 1 "LiftAxleLiftAllowed_Stat_LiftDeniedFrontOverload" 0 "LiftAxleLiftAllowed_Stat_LiftAllowed" ;
VAL_ 530 TrailerWithoutABS_ISig_6 3 "TrailerWithoutABS_NotAvailableOrNotInstalled" 2 "TrailerWithoutABS_ErrorIndicator" 1 "TrailerWithoutABS_YesTrailerWithoutABS" 0 "TrailerWithoutABS_NoNoTrailerPresentOraTrailerWithABS" ;
VAL_ 530 TrailerConnected_ISig_6 3 "NoYes_NotAvailable" 2 "NoYes_Error" 1 "NoYes_Yes" 0 "NoYes_No" ;
VAL_ 530 SWBrakeSwitch_ISig_6 3 "BrakeSwitch_NotAvailable" 2 "BrakeSwitch_Error" 1 "BrakeSwitch_BrakePedalDepressed" 0 "BrakeSwitch_BrakePedalReleased" ;
VAL_ 530 RearAxle2DiffLock_stat_ISig_6 3 "OffOn_NotAvailable" 2 "OffOn_Error" 1 "OffOn_On" 0 "OffOn_Off" ;
VAL_ 530 CentralRearDiffLock_stat_ISig_6 3 "DisengageEngage_NotAvailable" 2 "DisengageEngage_Error" 1 "DisengageEngage_Engage" 0 "DisengageEngage_Disengage" ;
VAL_ 530 BackToDriveReqACK_ISig_6 3 "BackToDriveReqACK_NotAvailable" 2 "BackToDriveReqACK_Error" 1 "BackToDriveReqACK_ChangeAcknowledged" 0 "BackToDriveReqACK_TakNoAction" ;
VAL_ 530 RearAxle1DiffLock_stat_ISig_6 3 "OffOn_NotAvailable" 2 "OffOn_Error" 1 "OffOn_On" 0 "OffOn_Off" ;
VAL_ 528 RearEndPositionStatus_ISig_6 7 "EndPositionStatus_NotAvailable" 6 "EndPositionStatus_Error" 5 "EndPositionStatus_Reserved_01" 4 "EndPositionStatus_Reserved" 3 "EndPositionStatus_LiftingAndLoweringNotAllowed" 2 "EndPositionStatus_MinEndLevelReached" 1 "EndPositionStatus_MaxEndLevelReached" 0 "EndPositionStatus_NoEndLevelReached" ;
VAL_ 528 FrontFerryFunctionCmd 7 "FerryFunctionCmd_NotAvailable" 6 "FerryFunctionCmd_Error" 5 "FerryFunctionCmd_Spare2" 4 "FerryFunctionCmd_Spare1" 3 "FerryFunctionCmd_Spare0" 2 "FerryFunctionCmd_Drain" 1 "FerryFunctionCmd_CloseValves" 0 "FerryFunctionCmd_Inactive" ;
VAL_ 528 RideHeightStatus_ISig_6 15 "RideHeightStatus_NotAvailable" 14 "RideHeightStatus_ErrorIndicator" 13 "RideHeightStatus_NotDefined_03" 12 "RideHeightStatus_NotDefined_02" 11 "RideHeightStatus_NotDefined_01" 10 "RideHeightStatus_NotDefined" 9 "RideHeightStatus_AlternativeDrivePosition2" 8 "RideHeightStatus_AlternativeDrivePosition1" 7 "RideHeightStatus_AlternativeDrivePosition" 6 "RideHeightStatus_HighDrivePosition" 5 "RideHeightStatus_LowDrivePosition" 4 "RideHeightStatus_SpeedDependentDrivePositionHighSpeed" 3 "RideHeightStatus_SpeedDependentDrivePositionLowSpeed" 2 "RideHeightStatus_StandardUserDrivePosition" 1 "RideHeightStatus_StandardFactoryDrivePosition" 0 "RideHeightStatus_Inactive" ;
VAL_ 528 KneelingInformation_ISig_6 15 "KneelingInformation_NotAvailable" 14 "KneelingInformation_ErrorIndicator" 13 "KneelingInformation_NotDefined_08" 12 "KneelingInformation_NotDefined_07" 11 "KneelingInformation_NotDefined_06" 10 "KneelingInformation_NotDefined_05" 9 "KneelingInformation_NotDefined_04" 8 "KneelingInformation_NotDefined_03" 7 "KneelingInformation_NotDefined_02" 6 "KneelingInformation_NotDefined_01" 5 "KneelingInformation_NotDefined" 4 "KneelingInformation_KneelingAborted" 3 "KneelingInformation_LiftingActiveVehicleIsLiftedDueToRcvrReq" 2 "KneelingInformation_KneelLevelReachedVehicleIsAtFixeKneelLvl" 1 "KneelingInformation_LoweringActiveTheVehIsLoweredDueToKneelReq" 0 "KneelingInformation_NotActiveTheKneelingFunctionIsNotActive" ;
VAL_ 528 RampHeightOutsideTargetRange_ISi 7 "HeightOutsideTargetRange_NotAvailable" 6 "HeightOutsideTargetRange_Error" 5 "HeightOutsideTargetRange_NotDefined_02" 4 "HeightOutsideTargetRange_NotDefined_01" 3 "HeightOutsideTargetRange_NotDefined" 2 "HeightOutsideTargetRange_ToHigh" 1 "HeightOutsideTargetRange_ToLow" 0 "HeightOutsideTargetRange_Inactive" ;
VAL_ 528 LiftAxle1PositionStatus_ISig_6 7 "LiftAxlePositionStatus_NotAvailable" 6 "LiftAxlePositionStatus_Error" 5 "LiftAxlePositionStatus_Reserved_01" 4 "LiftAxlePositionStatus_Reserved" 3 "LiftAxlePositionStatus_Lifting" 2 "LiftAxlePositionStatus_Lowering" 1 "LiftAxlePositionStatus_Lifted" 0 "LiftAxlePositionStatus_Lowered" ;
VAL_ 528 HeightAdjustmentAllowed_ISig_6 3 "FalseTrue_NotAvaiable" 2 "FalseTrue_Error" 1 "FalseTrue_True" 0 "FalseTrue_False" ;
VAL_ 528 FerryFunctionStatus_ISig_6 7 "FerryFunctionStatus_NotAvailable" 6 "FerryFunctionStatus_Error" 5 "FerryFunctionStatus_Spare_03" 4 "FerryFunctionStatus_Spare_02" 3 "FerryFunctionStatus_Spare_01" 2 "FerryFunctionStatus_FerryFunctionActiveLeveNotlReached" 1 "FerryFunctionStatus_FerryFunctionActiveLevelReached" 0 "FerryFunctionStatus_FerryFunctionNotActive" ;
VAL_ 528 LoadDistributionFuncSelected_ISi 15 "LoadDistributionFuncSelected_NotAvaiable" 14 "LoadDistributionFuncSelected_ErrorIndicator" 13 "LoadDistributionFuncSelected_SpareValue_08" 12 "LoadDistributionFuncSelected_SpareValue_07" 11 "LoadDistributionFuncSelected_SpareValue_06" 10 "LoadDistributionFuncSelected_SpareValue_05" 9 "LoadDistributionFuncSelected_SpareValue_04" 8 "LoadDistributionFuncSelected_SpareValue_03" 7 "LoadDistributionFuncSelected_SpareValue_02" 6 "LoadDistributionFuncSelected_MaximumTractionStartingHelp" 5 "LoadDistributionFuncSelected_VariableAxleLoad" 4 "LoadDistributionFuncSelected_NoLoadDistribution" 3 "LoadDistributionFuncSelected_AlternativeLoad" 2 "LoadDistributionFuncSelected_MaximumTractionTractionHelp" 1 "LoadDistributionFuncSelected_OptimisedTraction" 0 "LoadDistributionFuncSelected_NormalLoad" ;
VAL_ 528 RollEndPositionStatus_ISig_6 7 "RollEndPositionStatus_NotAvailable" 6 "RollEndPositionStatus_Error" 5 "RollEndPositionStatus_Reserved_01" 4 "RollEndPositionStatus_Reserved" 3 "RollEndPositionStatus_NoRollingAllowed" 2 "RollEndPositionStatus_CounterClockwiseEndLevelReached" 1 "RollEndPositionStatus_ClockwiseEndLevelReached" 0 "RollEndPositionStatus_NoEndLevelReached" ;
VAL_ 528 HeightControlMode 15 "HeightControlMode_NotAvailable" 14 "HeightControlMode_ErrorIndicator" 13 "HeightControlMode_SpareValue_03" 12 "HeightControlMode_FactorySupportMode" 11 "HeightControlMode_Calibration" 10 "HeightControlMode_Prohibit" 9 "HeightControlMode_FunctionTest" 8 "HeightControlMode_Stop" 7 "HeightControlMode_LimpHome" 6 "HeightControlMode_FerryFunction" 5 "HeightControlMode_KneelingHeight" 4 "HeightControlMode_DriveHeight" 3 "HeightControlMode_DockingRampHeight" 2 "HeightControlMode_HeightAdjustment" 1 "HeightControlMode_StartUpHeight" 0 "HeightControlMode_TakeNoAction" ;
VAL_ 528 RideHeightFunctionStatus_ISig_6 15 "RideHeightFunction_NotAvailable" 14 "RideHeightFunction_ErrorIndicator" 13 "RideHeightFunction_NotDefined_05" 12 "RideHeightFunction_NotDefined_04" 11 "RideHeightFunction_NotDefined_03" 10 "RideHeightFunction_NotDefined_02" 9 "RideHeightFunction_NotDefined_01" 8 "RideHeightFunction_NotDefined" 7 "RideHeightFunction_AlternativeDrivePosition2" 6 "RideHeightFunction_AlternativeDrivePosition1" 5 "RideHeightFunction_LowDrivePosition" 4 "RideHeightFunction_HighDrivePosition" 3 "RideHeightFunction_SpeedDependentDrivePosition" 2 "RideHeightFunction_AlternativeDrivePosition" 1 "RideHeightFunction_StandardDrivePosition" 0 "RideHeightFunction_Inactive" ;
VAL_ 528 LevelControlInformation_ISig_6 15 "LevelControlInformation_NotAvailable" 14 "LevelControlInformation_Error" 13 "LevelControlInformation_Reserved_06" 12 "LevelControlInformation_Reserved_05" 11 "LevelControlInformation_Reserved_04" 10 "LevelControlInformation_Reserved_03" 9 "LevelControlInformation_Reserved_02" 8 "LevelControlInformation_Reserved_01" 7 "LevelControlInformation_Reserved" 6 "LevelControlInformation_LimpHome" 5 "LevelControlInformation_FerryFunction" 4 "LevelControlInformation_KneelingHeight" 3 "LevelControlInformation_DriveHeight" 2 "LevelControlInformation_DockingHeight" 1 "LevelControlInformation_HeightAdjustment" 0 "LevelControlInformation_Prohibit" ;
VAL_ 528 KneelingStatusHMI_ISig_6 3 "KneelingStatusHMI_NotAvailable" 2 "KneelingStatusHMI_Error" 1 "KneelingStatusHMI_Active" 0 "KneelingStatusHMI_Inactive" ;
VAL_ 528 DirInd_Rear_Status 7 "DirIndFaultStatus_NotAvailable" 6 "DirIndFaultStatus_Error" 5 "DirIndFaultStatus_SpareValue_01" 4 "DirIndFaultStatus_SpareValue" 3 "DirIndFaultStatus_BothLeftAndRightDirectionIndicatorsFault" 2 "DirIndFaultStatus_RightDirectionIndicatorLampFault" 1 "DirIndFaultStatus_LeftDirectionIndicatorLampFault" 0 "DirIndFaultStatus_NoError" ;
VAL_ 528 VehicleDynamicSuspProhibitStat 3 "InactiveActive_NotAvailable" 2 "InactiveActive_Error" 1 "InactiveActive_Active" 0 "InactiveActive_Inactive" ;
VAL_ 528 ChangeKneelACK_ISig_6 3 "ChangeKneelACK_NotAvailable" 2 "ChangeKneelACK_Error" 1 "ChangeKneelACK_ChangeAcknowledged" 0 "ChangeKneelACK_NoAction" ;
VAL_ 528 ECSShutdownCmd 3 "FalseTrue_NotAvaiable" 2 "FalseTrue_Error" 1 "FalseTrue_True" 0 "FalseTrue_False" ;
VAL_ 528 LiftAxle2PositionStatus_ISig_6 7 "LiftAxlePositionStatus_NotAvailable" 6 "LiftAxlePositionStatus_Error" 5 "LiftAxlePositionStatus_Reserved_01" 4 "LiftAxlePositionStatus_Reserved" 3 "LiftAxlePositionStatus_Lifting" 2 "LiftAxlePositionStatus_Lowering" 1 "LiftAxlePositionStatus_Lifted" 0 "LiftAxlePositionStatus_Lowered" ;
VAL_ 517 RampLevelStatus_ISig_6 15 "RampLevelStatus_NotAvaiable" 14 "RampLevelStatus_ErrorIndicator" 13 "RampLevelStatus_NotDefined_05" 12 "RampLevelStatus_NotDefined_04" 11 "RampLevelStatus_NotDefined_03" 10 "RampLevelStatus_NotDefined_02" 9 "RampLevelStatus_NotDefined_01" 8 "RampLevelStatus_NotDefined" 7 "RampLevelStatus_RampLevelM7" 6 "RampLevelStatus_RampLevelM6" 5 "RampLevelStatus_RampLevelM5" 4 "RampLevelStatus_RampLevelM4" 3 "RampLevelStatus_RampLevelM3" 2 "RampLevelStatus_RampLevelM2" 1 "RampLevelStatus_RampLevelM1" 0 "RampLevelStatus_Inactive" ;
VAL_ 517 LiftAxle2LowerACK_ISig_6 7 "LiftAxle2LowerACK_NotAvailable" 6 "LiftAxle2LowerACK_Error" 5 "LiftAxle2LowerACK_SystemDeniedVersatile" 4 "LiftAxle2LowerACK_Spare_01" 3 "LiftAxle2LowerACK_Spare" 2 "LiftAxle2LowerACK_LowerDeniedRAS_EC" 1 "LiftAxle2LowerACK_ChangeAcknowledged" 0 "LiftAxle2LowerACK_NoAction" ;
VAL_ 517 LiftAxle2UpRequestACK_ISig_6 7 "LiftAxleUpRequestACK_NotAvailable" 6 "LiftAxleUpRequestACK_Error" 5 "LiftAxleUpRequestACK_SystemDeniedVersatile" 4 "LiftAxleUpRequestACK_LiftDeniedPBrakeActive" 3 "LiftAxleUpRequestACK_LiftDeniedRearOverload" 2 "LiftAxleUpRequestACK_LiftDeniedFrontOverload" 1 "LiftAxleUpRequestACK_ChangeAcknowledged" 0 "LiftAxleUpRequestACK_NoAction" ;
VAL_ 517 FrontLimpHomeCmd 7 "LimpHomeCmd_NotAvailable" 6 "LimpHomeCmd_Error" 5 "LimpHomeCmd_Spare_01" 4 "LimpHomeCmd_Spare" 3 "LimpHomeCmd_Fill" 2 "LimpHomeCmd_Drain" 1 "LimpHomeCmd_CloseValves" 0 "LimpHomeCmd_Inactive" ;
VAL_ 517 LiftAxle1LiftFuncSelected_ISig_6 7 "LiftAxleLiftAutoFuncSelected_NotAvailable" 6 "LiftAxleLiftAutoFuncSelected_Error" 5 "LiftAxleLiftAutoFuncSelected_Reserved" 4 "LiftAxleLiftAutoFuncSelected_UnlimitedLift" 3 "LiftAxleLiftAutoFuncSelected_LiftOverload" 2 "LiftAxleLiftAutoFuncSelected_LiftPlus30" 1 "LiftAxleLiftAutoFuncSelected_Lift" 0 "LiftAxleLiftAutoFuncSelected_NoLift" ;
VAL_ 517 RearAxleInBumperRange_ISig_6 3 "AxleInBumperRange_NotAvailable" 2 "AxleInBumperRange_ErrorIndicator" 1 "AxleInBumperRange_ActualLevelWithinBumperRange" 0 "AxleInBumperRange_ActualLevelOutOfBumperRange" ;
VAL_ 517 LiftAxle1UpRequestACK_ISig_6 7 "LiftAxleUpRequestACK_NotAvailable" 6 "LiftAxleUpRequestACK_Error" 5 "LiftAxleUpRequestACK_SystemDeniedVersatile" 4 "LiftAxleUpRequestACK_LiftDeniedPBrakeActive" 3 "LiftAxleUpRequestACK_LiftDeniedRearOverload" 2 "LiftAxleUpRequestACK_LiftDeniedFrontOverload" 1 "LiftAxleUpRequestACK_ChangeAcknowledged" 0 "LiftAxleUpRequestACK_NoAction" ;
VAL_ 517 FogLamp_Rear_Status 3 "InactiveActive_NotAvailable" 2 "InactiveActive_Error" 1 "InactiveActive_Active" 0 "InactiveActive_Inactive" ;
VAL_ 517 StopLevelChangeAck_ISig_6 3 "StopLevelChangeStatus_NotAvailable" 2 "StopLevelChangeStatus_ErrorIndicator" 1 "StopLevelChangeStatus_LevelChangedStopped" 0 "StopLevelChangeStatus_NoStopRequest" ;
VAL_ 517 RampLevelStorageAck_ISig_6 3 "StorageAck_NotAvaiable" 2 "StorageAck_Error" 1 "StorageAck_ChangeAcknowledged" 0 "StorageAck_TakeNoAction" ;
VAL_ 517 RideHeightOutsideTargetRange_ISi 7 "HeightOutsideTargetRange_NotAvailable" 6 "HeightOutsideTargetRange_Error" 5 "HeightOutsideTargetRange_NotDefined_02" 4 "HeightOutsideTargetRange_NotDefined_01" 3 "HeightOutsideTargetRange_NotDefined" 2 "HeightOutsideTargetRange_ToHigh" 1 "HeightOutsideTargetRange_ToLow" 0 "HeightOutsideTargetRange_Inactive" ;
VAL_ 517 LiftingControlModeFrontAxle_ISig 3 "InactiveActive_NotAvailable" 2 "InactiveActive_Error" 1 "InactiveActive_Active" 0 "InactiveActive_Inactive" ;
VAL_ 517 LoadDistributionChangeACK_ISig_6 7 "LoadDistributionChangeACK_NotAvailable" 6 "LoadDistributionChangeACK_Error" 5 "LoadDistributionChangeACK_SystemDeniedVersatile" 4 "LoadDistributionChangeACK_Reserved_2" 3 "LoadDistributionChangeACK_Reserved_1" 2 "LoadDistributionChangeACK_LoadShiftDeniedFALIMOverload" 1 "LoadDistributionChangeACK_ChangeAcknowledged" 0 "LoadDistributionChangeACK_NoAction" ;
VAL_ 517 RideHeightStorageAck_ISig_6 3 "StorageAck_NotAvaiable" 2 "StorageAck_Error" 1 "StorageAck_ChangeAcknowledged" 0 "StorageAck_TakeNoAction" ;
VAL_ 517 ECSStandbyAllowed_ISig_6 3 "FalseTrue_NotAvaiable" 2 "FalseTrue_Error" 1 "FalseTrue_True" 0 "FalseTrue_False" ;
VAL_ 517 LiftAxle2LiftFuncSelected_ISig_6 7 "LiftAxleLiftAutoFuncSelected_NotAvailable" 6 "LiftAxleLiftAutoFuncSelected_Error" 5 "LiftAxleLiftAutoFuncSelected_Reserved" 4 "LiftAxleLiftAutoFuncSelected_UnlimitedLift" 3 "LiftAxleLiftAutoFuncSelected_LiftOverload" 2 "LiftAxleLiftAutoFuncSelected_LiftPlus30" 1 "LiftAxleLiftAutoFuncSelected_Lift" 0 "LiftAxleLiftAutoFuncSelected_NoLift" ;
VAL_ 517 FrontProhibitControlRequest 3 "Request_NotAvailable" 2 "Request_Error" 1 "Request_RequestActive" 0 "Request_NotRequested" ;
VAL_ 517 LiftingControlModeRearAxle_ISig_ 3 "InactiveActive_NotAvailable" 2 "InactiveActive_Error" 1 "InactiveActive_Active" 0 "InactiveActive_Inactive" ;
VAL_ 517 ProhibitControlStatus_ISig_6 3 "InactiveActive_NotAvailable" 2 "InactiveActive_Error" 1 "InactiveActive_Active" 0 "InactiveActive_Inactive" ;
VAL_ 517 DisableMechFaultDctnFr_rqst 3 "FalseTrue_NotAvaiable" 2 "FalseTrue_Error" 1 "FalseTrue_True" 0 "FalseTrue_False" ;
VAL_ 517 FrontParkBrakeOverrideCommand 3 "FrontParkBrakeOverrideCommand_NotAvailable" 2 "FrontParkBrakeOverrideCommand_ErrorIndicator" 1 "FrontParkBrakeOverrideCommand_FrontParkBrakeOverrideCommand" 0 "FrontParkBrakeOverrideCommand_NoCommand" ;
VAL_ 1339 FrontConspicLamp_stat_LoLeft_ISi 7 "LampCheck_stat_NotAvailable" 6 "LampCheck_stat_Error" 5 "LampCheck_stat_Spare_02" 4 "LampCheck_stat_Spare_01" 3 "LampCheck_stat_Spare" 2 "LampCheck_stat_TestedLampNOK" 1 "LampCheck_stat_TestedLampOK" 0 "LampCheck_stat_NotTested" ;
VAL_ 1339 HeadlampFan_stat_ISig_6 7 "LampFanTestStat_NotAvailable" 6 "LampFanTestStat_Error" 5 "LampFanTestStat_Spare3" 4 "LampFanTestStat_Spare2" 3 "LampFanTestStat_Spare1" 2 "LampFanTestStat_FanTestedNOK" 1 "LampFanTestStat_FanTestedOK" 0 "LampFanTestStat_NotTested" ;
VAL_ 1339 FrontConspicLamp_stat_HiLeft_ISi 7 "LampCheck_stat_NotAvailable" 6 "LampCheck_stat_Error" 5 "LampCheck_stat_Spare_02" 4 "LampCheck_stat_Spare_01" 3 "LampCheck_stat_Spare" 2 "LampCheck_stat_TestedLampNOK" 1 "LampCheck_stat_TestedLampOK" 0 "LampCheck_stat_NotTested" ;
VAL_ 1339 FrontConspicLamp_stat_LoRight_IS 7 "LampCheck_stat_NotAvailable" 6 "LampCheck_stat_Error" 5 "LampCheck_stat_Spare_02" 4 "LampCheck_stat_Spare_01" 3 "LampCheck_stat_Spare" 2 "LampCheck_stat_TestedLampNOK" 1 "LampCheck_stat_TestedLampOK" 0 "LampCheck_stat_NotTested" ;
VAL_ 1339 FrontConspicLamp_stat_HiRight_IS 7 "LampCheck_stat_NotAvailable" 6 "LampCheck_stat_Error" 5 "LampCheck_stat_Spare_02" 4 "LampCheck_stat_Spare_01" 3 "LampCheck_stat_Spare" 2 "LampCheck_stat_TestedLampNOK" 1 "LampCheck_stat_TestedLampOK" 0 "LampCheck_stat_NotTested" ;
VAL_ 1243 MainBeamLEDStatusLeft_ISig_6 7 "LampCheck_stat_NotAvailable" 6 "LampCheck_stat_Error" 5 "LampCheck_stat_Spare_02" 4 "LampCheck_stat_Spare_01" 3 "LampCheck_stat_Spare" 2 "LampCheck_stat_TestedLampNOK" 1 "LampCheck_stat_TestedLampOK" 0 "LampCheck_stat_NotTested" ;
VAL_ 1243 MainBeamLEDStatusRight_ISig_6 7 "LampCheck_stat_NotAvailable" 6 "LampCheck_stat_Error" 5 "LampCheck_stat_Spare_02" 4 "LampCheck_stat_Spare_01" 3 "LampCheck_stat_Spare" 2 "LampCheck_stat_TestedLampNOK" 1 "LampCheck_stat_TestedLampOK" 0 "LampCheck_stat_NotTested" ;
SIG_GROUP_ 1522 Trailer1TPMAxlTireCfg_sg_ISig_6 1 : Trailer1TPMAxlTireCfg_Axle5_ISig Trailer1TPMAxlTireCfg_Axle1_ISig Trailer1TPMAxlTireCfg_Axle2_ISig Trailer1TPMAxlTireCfg_Axle3_ISig Trailer1TPMAxlTireCfg_Axle4_ISig;
SIG_GROUP_ 1522 Trailer1TPMThresCfg_sg_ISig_6 1 : Trailer1TPMThresCfg_OverPres_ISi Trailer1TPMThresCfg_AxleNr_ISig_ Trailer1TPMThresCfg_ExtOverPres_ Trailer1TPMThresCfg_ExtUnderPres Trailer1TPMThresCfg_UnderPres_IS;
SIG_GROUP_ 947 FrontLevRefCtrl_sg 1 : FrontLevRefCtrl_ShortPushCnt FrontLevRefCtrl_LevelRef;
SIG_GROUP_ 947 FPBRMMIStat_sg_ISig_6 1 : FPBRMMIStat_FPBRChangeAck_ISig_6 FPBRMMIStat_FPBRStatusInd_ISig_6;
SIG_GROUP_ 1339 FrontConspicLamp_stat_sg_ISig_6 1 : FrontConspicLamp_stat_LoLeft_ISi FrontConspicLamp_stat_HiLeft_ISi FrontConspicLamp_stat_LoRight_IS FrontConspicLamp_stat_HiRight_IS;
